VERSION "canboat-NMEA2000-curated"

NS_ :

BS_:

BU_: Vector__XXX
BO_ 2583635968 PGN_130856_simnetAlarmMessage: 229 Vector__XXX
 SG_ Manufacturer_Code : 0|11@1+ (1.0,0) [0|2047] "" Vector__XXX
 SG_ Industry_Code : 13|3@1+ (1.0,0) [0|7] "" Vector__XXX
 SG_ Alarm_ID : 16|16@1+ (1.0,0) [0|65535] "" Vector__XXX
 SG_ B : 32|8@1+ (1.0,0) [0|255] "" Vector__XXX
 SG_ C : 40|8@1+ (1.0,0) [0|255] "" Vector__XXX
 SG_ Text : 48|1784@1+ (1.0,0) [0|1090215279796298345343057319992441691038624747443985361781209060500115864369550760897269927218265076257224706224150656474098235960303036328065314058501678867531182833105052489870268422279120576700031813116210596361941430020414688522690787050244934600671795757515093047026287646566366777283893649942831776083163858446641848270013788759459916945946844663111358071639842481472666169361795887031940572252862030682746818684507336852618633070135215708762463263460541984102045620907003420426453486084172633338261276848631947315738747720031010815] "" Vector__XXX

BO_ 2650745856 PGN_130860_simnetApUnknown4: 23 Vector__XXX
 SG_ Manufacturer_Code : 0|11@1+ (1.0,0) [0|2047] "" Vector__XXX
 SG_ Industry_Code : 13|3@1+ (1.0,0) [0|7] "" Vector__XXX
 SG_ A : 16|8@1+ (1.0,0) [0|255] "" Vector__XXX
 SG_ B : 24|32@1- (1.0,0) [-2147483648|2147483647] "" Vector__XXX
 SG_ C : 56|32@1- (1.0,0) [-2147483648|2147483647] "" Vector__XXX
 SG_ D : 88|32@1+ (1.0,0) [0|4294967295] "" Vector__XXX
 SG_ E : 120|32@1- (1.0,0) [-2147483648|2147483647] "" Vector__XXX
 SG_ F : 152|32@1+ (1.0,0) [0|4294967295] "" Vector__XXX

BO_ 2583642112 PGN_130880_airmarAdditionalWeatherData: 9 Vector__XXX
 SG_ Manufacturer_Code : 0|11@1+ (1.0,0) [0|2047] "" Vector__XXX
 SG_ Industry_Code : 13|3@1+ (1.0,0) [0|7] "" Vector__XXX
 SG_ C : 16|8@1+ (1.0,0) [0|255] "" Vector__XXX
 SG_ Apparent_Windchill_Temperature : 24|16@1+ (0.01,0) [0.0|655.35] "" Vector__XXX
 SG_ True_Windchill_Temperature : 40|16@1+ (0.01,0) [0.0|655.35] "" Vector__XXX
 SG_ Dewpoint : 56|16@1+ (0.01,0) [0.0|655.35] "" Vector__XXX

BO_ 2583642368 PGN_130881_airmarHeaterControl: 9 Vector__XXX
 SG_ Manufacturer_Code : 0|11@1+ (1.0,0) [0|2047] "" Vector__XXX
 SG_ Industry_Code : 13|3@1+ (1.0,0) [0|7] "" Vector__XXX
 SG_ C : 16|8@1+ (1.0,0) [0|255] "" Vector__XXX
 SG_ Plate_Temperature : 24|16@1+ (0.01,0) [0.0|655.35] "" Vector__XXX
 SG_ Air_Temperature : 40|16@1+ (0.01,0) [0.0|655.35] "" Vector__XXX
 SG_ Dewpoint : 56|16@1+ (0.01,0) [0.0|655.35] "" Vector__XXX

BO_ 2583647232 PGN_130900_xantrexAcStatus: 20 Vector__XXX
 SG_ Manufacturer_Code : 0|11@1+ (1.0,0) [0|2047] "" Vector__XXX
 SG_ Industry_Code : 13|3@1+ (1.0,0) [0|7] "" Vector__XXX
 SG_ AC_Instance : 16|8@1+ (1.0,0) [0|255] "" Vector__XXX
 SG_ Number_of_Lines : 24|8@1+ (1.0,0) [0|255] "" Vector__XXX
 SG_ Line : 32|2@1+ (1.0,0) [0|3] "" Vector__XXX
 SG_ Acceptability : 34|2@1+ (1.0,0) [0|3] "" Vector__XXX
 SG_ Waveform : 36|3@1+ (1.0,0) [0|7] "" Vector__XXX
 SG_ Voltage : 40|16@1+ (0.01,0) [0.0|655.35] "" Vector__XXX
 SG_ Current : 56|16@1+ (0.1,0) [0.0|6553.5] "" Vector__XXX
 SG_ Frequency : 72|16@1+ (1.0,0) [0|65535] "" Vector__XXX
 SG_ Real_Power : 88|32@1- (1.0,0) [-2147483648|2147483647] "" Vector__XXX
 SG_ Reactive_Power : 120|32@1- (1.0,0) [-2147483648|2147483647] "" Vector__XXX
 SG_ Power_Factor : 152|8@1- (1.0,0) [-128|127] "%" Vector__XXX

BO_ 2583649792 PGN_130910_xantrexDcSourceConfigurationStatus: 19 Vector__XXX
 SG_ Manufacturer_Code : 0|11@1+ (1.0,0) [0|2047] "" Vector__XXX
 SG_ Industry_Code : 13|3@1+ (1.0,0) [0|7] "" Vector__XXX
 SG_ DC_Source_Instance : 16|8@1+ (1.0,0) [0|255] "" Vector__XXX
 SG_ DC_UV_Shutdown_Level : 24|16@1+ (0.01,0) [0.0|655.35] "" Vector__XXX
 SG_ DC_UV_Warning_Level : 40|16@1+ (0.01,0) [0.0|655.35] "" Vector__XXX
 SG_ DC_UV_Shutdown_Delay : 56|16@1+ (0.01,0) [0.0|655.35] "" Vector__XXX
 SG_ DC_UV_Recover_Level : 72|16@1+ (0.01,0) [0.0|655.35] "" Vector__XXX
 SG_ DC_OV_Shutdown_Level : 88|16@1+ (0.01,0) [0.0|655.35] "" Vector__XXX
 SG_ DC_OV_Warning_Level : 104|16@1+ (0.01,0) [0.0|655.35] "" Vector__XXX
 SG_ DC_OV_Shutdown_Delay : 120|16@1+ (0.01,0) [0.0|655.35] "" Vector__XXX
 SG_ DC_OV_Recover_Level : 136|16@1+ (0.01,0) [0.0|655.35] "" Vector__XXX

BO_ 2583650048 PGN_130911_xantrexAcOutputConfigurationStatus: 17 Vector__XXX
 SG_ Manufacturer_Code : 0|11@1+ (1.0,0) [0|2047] "" Vector__XXX
 SG_ Industry_Code : 13|3@1+ (1.0,0) [0|7] "" Vector__XXX
 SG_ AC_Source_Instance : 16|8@1+ (1.0,0) [0|255] "" Vector__XXX
 SG_ Number_of_Lines : 24|8@1+ (1.0,0) [0|255] "" Vector__XXX
 SG_ Line : 32|2@1+ (1.0,0) [0|3] "" Vector__XXX
 SG_ Voltage : 40|16@1+ (0.01,0) [0.0|655.35] "" Vector__XXX
 SG_ Frequency : 56|16@1+ (1.0,0) [0|65535] "" Vector__XXX
 SG_ Power_Limit : 72|32@1+ (1.0,0) [0|4294967295] "" Vector__XXX
 SG_ OV_Fault_Level : 104|16@1+ (0.01,0) [0.0|655.35] "" Vector__XXX
 SG_ UV_Fault_Level : 120|16@1+ (0.01,0) [0.0|655.35] "" Vector__XXX

BO_ 2583650304 PGN_130912_xantrexChargerConfigurationStatus: 24 Vector__XXX
 SG_ Manufacturer_Code : 0|11@1+ (1.0,0) [0|2047] "" Vector__XXX
 SG_ Industry_Code : 13|3@1+ (1.0,0) [0|7] "" Vector__XXX
 SG_ Charge_Instance : 16|8@1+ (1.0,0) [0|255] "" Vector__XXX
 SG_ Battery_Instance : 24|8@1+ (1.0,0) [0|255] "" Vector__XXX
 SG_ Bulk_Voltage : 32|16@1+ (0.01,0) [0.0|655.35] "" Vector__XXX
 SG_ Bulk_Time : 48|16@1+ (1.0,0) [0|65535] "" Vector__XXX
 SG_ Absorption_Voltage : 64|16@1+ (0.01,0) [0.0|655.35] "" Vector__XXX
 SG_ Absorption_Time : 80|16@1+ (1.0,0) [0|65535] "" Vector__XXX
 SG_ Float_Voltage : 96|16@1+ (0.01,0) [0.0|655.35] "" Vector__XXX
 SG_ Float_Time : 112|16@1+ (1.0,0) [0|65535] "" Vector__XXX
 SG_ Equalization_Voltage : 128|16@1+ (0.01,0) [0.0|655.35] "" Vector__XXX
 SG_ Generic_Charge_Voltage : 144|16@1+ (0.01,0) [0.0|655.35] "" Vector__XXX
 SG_ Generic_Charge_Current : 160|32@1+ (1.0,0) [0|4294967295] "" Vector__XXX

BO_ 2583650560 PGN_130913_xantrexAcInputConfigurationStatus: 27 Vector__XXX
 SG_ Manufacturer_Code : 0|11@1+ (1.0,0) [0|2047] "" Vector__XXX
 SG_ Industry_Code : 13|3@1+ (1.0,0) [0|7] "" Vector__XXX
 SG_ AC_Source_Instance : 16|8@1+ (1.0,0) [0|255] "" Vector__XXX
 SG_ Number_of_Lines : 24|8@1+ (1.0,0) [0|255] "" Vector__XXX
 SG_ Line : 32|2@1+ (1.0,0) [0|3] "" Vector__XXX
 SG_ Breaker_Size : 40|16@1+ (1.0,0) [0|65535] "" Vector__XXX
 SG_ AC_Lost_Level : 56|16@1+ (1.0,0) [0|65535] "" Vector__XXX
 SG_ AC_UV_Level : 72|16@1+ (0.01,0) [0.0|655.35] "" Vector__XXX
 SG_ AC_UV_Warning_Level : 88|16@1+ (1.0,0) [0|65535] "" Vector__XXX
 SG_ AC_UV_Delay : 104|16@1+ (1.0,0) [0|65535] "" Vector__XXX
 SG_ AC_OV_Level : 120|16@1+ (0.01,0) [0.0|655.35] "" Vector__XXX
 SG_ AC_OV_Warning_Level : 136|16@1+ (1.0,0) [0|65535] "" Vector__XXX
 SG_ AC_OV_Delay : 152|16@1+ (1.0,0) [0|65535] "" Vector__XXX
 SG_ AC_UF_Level : 168|16@1+ (1.0,0) [0|65535] "" Vector__XXX
 SG_ AC_OF_Level : 184|32@1+ (1.0,0) [0|4294967295] "" Vector__XXX

BO_ 2650760704 PGN_130918_seatalkRouteInformation: 47 Vector__XXX
 SG_ Manufacturer_Code : 0|11@1+ (1.0,0) [0|2047] "" Vector__XXX
 SG_ Industry_Code : 13|3@1+ (1.0,0) [0|7] "" Vector__XXX
 SG_ Current_Waypoint_Sequence : 16|16@1+ (1.0,0) [0|65535] "" Vector__XXX
 SG_ Current_Waypoint_Name : 32|128@1+ (1.0,0) [0|340282366920938463463374607431768211455] "" Vector__XXX
 SG_ Next_Waypoint_Sequence : 160|16@1+ (1.0,0) [0|65535] "" Vector__XXX
 SG_ Next_Waypoint_Name : 176|128@1+ (1.0,0) [0|340282366920938463463374607431768211455] "" Vector__XXX
 SG_ Unknown : 304|8@1+ (1.0,0) [0|255] "" Vector__XXX
 SG_ Distance__Position_to_Next_Waypoint : 312|32@1+ (1.0,0) [0|4294967295] "" Vector__XXX
 SG_ Bearing__Position_to_Next_Waypoint__True : 344|16@1+ (0.0001,0) [0.0|6.5535000000000005] "" Vector__XXX
 SG_ Bearing__Current_Waypoint_to_Next_Waypoint__True : 360|16@1+ (0.0001,0) [0.0|6.5535000000000005] "" Vector__XXX

BO_ 2583652608 PGN_130921_carlingBreakerStatusAndConfiguration: 222 Vector__XXX
 SG_ Manufacturer_Code : 0|11@1+ (1.0,0) [0|2047] "" Vector__XXX
 SG_ Industry_Code : 13|3@1+ (1.0,0) [0|7] "" Vector__XXX
 SG_ Message_Type : 16|8@1+ (1.0,0) [0|255] "" Vector__XXX
 SG_ Data : 24|1752@1+ (1.0,0) [0|253835525316255713194389203561572751737810845357362498012652867590104198169324258551297226738712069638358593504910975805040969504114016035586901488365065042751650985587633328947766782315243169828325466512751438739230257929399304213628821785153107391826760898696978820261146790945522202477765653734754718859485317591261548984333357950546759400970033524351045040329881590202605856899590205175788275025054353913931832342526721035274358715427856824538312680893703825795567971865414506855060692430514058409785217803118738186484842495] "" Vector__XXX

BO_ 2583657216 PGN_130939_lumishoreLightControl: 11 Vector__XXX
 SG_ Manufacturer_Code : 0|11@1+ (1.0,0) [0|2047] "" Vector__XXX
 SG_ Industry_Code : 13|3@1+ (1.0,0) [0|7] "" Vector__XXX
 SG_ Zone_Index : 16|8@1+ (1.0,0) [0|255] "" Vector__XXX
 SG_ Red : 24|8@1+ (1.0,0) [0|255] "" Vector__XXX
 SG_ Green : 32|8@1+ (1.0,0) [0|255] "" Vector__XXX
 SG_ Blue : 40|8@1+ (1.0,0) [0|255] "" Vector__XXX
 SG_ Cold_White : 48|8@1+ (1.0,0) [0|255] "" Vector__XXX
 SG_ Warm_White : 56|8@1+ (1.0,0) [0|255] "" Vector__XXX
 SG_ Intensity : 64|8@1+ (1.0,0) [0|255] "" Vector__XXX
 SG_ On_Off : 72|8@1+ (1.0,0) [0|255] "" Vector__XXX
 SG_ Status : 80|8@1+ (1.0,0) [0|255] "" Vector__XXX

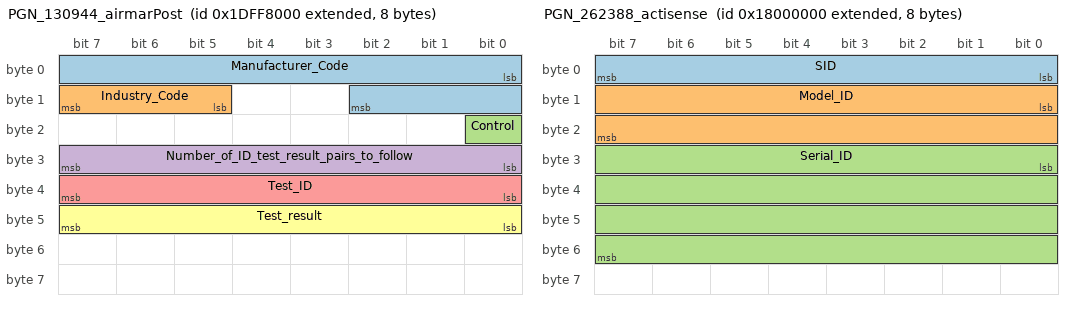
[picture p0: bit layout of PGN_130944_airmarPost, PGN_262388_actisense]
BO_ 2650767360 PGN_130944_airmarPost: 8 Vector__XXX
 SG_ Manufacturer_Code : 0|11@1+ (1.0,0) [0|2047] "" Vector__XXX
 SG_ Industry_Code : 13|3@1+ (1.0,0) [0|7] "" Vector__XXX
 SG_ Control : 16|1@1+ (1.0,0) [0|1] "" Vector__XXX
 SG_ Number_of_ID_test_result_pairs_to_follow : 24|8@1+ (1.0,0) [0|255] "" Vector__XXX
 SG_ Test_ID : 32|8@1+ (1.0,0) [0|255] "" Vector__XXX
 SG_ Test_result : 40|8@1+ (1.0,0) [0|255] "" Vector__XXX

BO_ 2583658752 PGN_130945_yamahaEngineData: 8 Vector__XXX
 SG_ Manufacturer_Code : 0|11@1+ (1.0,0) [0|2047] "" Vector__XXX
 SG_ Industry_Code : 13|3@1+ (1.0,0) [0|7] "" Vector__XXX

BO_ 2583659008 PGN_130946_yamahaEngineData2: 8 Vector__XXX
 SG_ Manufacturer_Code : 0|11@1+ (1.0,0) [0|2047] "" Vector__XXX
 SG_ Industry_Code : 13|3@1+ (1.0,0) [0|7] "" Vector__XXX

BO_ 2583659264 PGN_130947_yamahaEngineData3: 8 Vector__XXX
 SG_ Manufacturer_Code : 0|11@1+ (1.0,0) [0|2047] "" Vector__XXX
 SG_ Industry_Code : 13|3@1+ (1.0,0) [0|7] "" Vector__XXX

BO_ 2583660288 PGN_130951_yamahaEngineData4: 8 Vector__XXX
 SG_ Manufacturer_Code : 0|11@1+ (1.0,0) [0|2047] "" Vector__XXX
 SG_ Industry_Code : 13|3@1+ (1.0,0) [0|7] "" Vector__XXX

BO_ 2583674880 PGN_131008_yamahaEngineData5: 8 Vector__XXX
 SG_ Manufacturer_Code : 0|11@1+ (1.0,0) [0|2047] "" Vector__XXX
 SG_ Industry_Code : 13|3@1+ (1.0,0) [0|7] "" Vector__XXX

BO_ 2583675648 PGN_131011_yamahaEngineData6: 8 Vector__XXX
 SG_ Manufacturer_Code : 0|11@1+ (1.0,0) [0|2047] "" Vector__XXX
 SG_ Industry_Code : 13|3@1+ (1.0,0) [0|7] "" Vector__XXX

BO_ 2583675904 PGN_131012_yamahaEngineData7: 8 Vector__XXX
 SG_ Manufacturer_Code : 0|11@1+ (1.0,0) [0|2047] "" Vector__XXX
 SG_ Industry_Code : 13|3@1+ (1.0,0) [0|7] "" Vector__XXX

BO_ 2550136832 PGN_262161_actisenseOperatingMode: 13 Vector__XXX
 SG_ SID : 0|8@1+ (1.0,0) [0|255] "" Vector__XXX
 SG_ Model_ID : 8|16@1+ (1.0,0) [0|65535] "" Vector__XXX
 SG_ Serial_ID : 24|32@1+ (1.0,0) [0|4294967295] "" Vector__XXX
 SG_ Error_ID : 56|32@1+ (1.0,0) [0|4294967295] "" Vector__XXX
 SG_ Operating_Mode : 88|16@1+ (1.0,0) [0|65535] "" Vector__XXX

BO_ 2550136832 PGN_262384_actisenseStartupStatus: 15 Vector__XXX
 SG_ SID : 0|8@1+ (1.0,0) [0|255] "" Vector__XXX
 SG_ Model_ID : 8|16@1+ (1.0,0) [0|65535] "" Vector__XXX
 SG_ Serial_ID : 24|32@1+ (1.0,0) [0|4294967295] "" Vector__XXX
 SG_ Error_ID : 56|32@1+ (1.0,0) [0|4294967295] "" Vector__XXX
 SG_ Firmware_version : 88|16@1+ (0.001,0) [0.0|65.535] "" Vector__XXX
 SG_ Reset_status : 104|8@1+ (1.0,0) [0|255] "" Vector__XXX
 SG_ A : 112|8@1+ (1.0,0) [0|255] "" Vector__XXX

BO_ 2550136832 PGN_262386_actisenseSystemStatus: 33 Vector__XXX
 SG_ SID : 0|8@1+ (1.0,0) [0|255] "" Vector__XXX
 SG_ Model_ID : 8|16@1+ (1.0,0) [0|65535] "" Vector__XXX
 SG_ Serial_ID : 24|32@1+ (1.0,0) [0|4294967295] "" Vector__XXX
 SG_ Error_ID : 56|32@1+ (1.0,0) [0|4294967295] "" Vector__XXX
 SG_ Indi_channel_count : 88|8@1+ (1.0,0) [0|255] "" Vector__XXX
 SG_ Ch1_Rx_Bandwidth : 96|8@1+ (1.0,0) [0|255] "" Vector__XXX
 SG_ Ch1_Rx_Load : 104|8@1+ (1.0,0) [0|255] "" Vector__XXX
 SG_ Ch1_Rx_Filtered : 112|8@1+ (1.0,0) [0|255] "" Vector__XXX
 SG_ Ch1_Rx_Dropped : 120|8@1+ (1.0,0) [0|255] "" Vector__XXX
 SG_ Ch1_Tx_Bandwidth : 128|8@1+ (1.0,0) [0|255] "" Vector__XXX
 SG_ Ch1_Tx_Load : 136|8@1+ (1.0,0) [0|255] "" Vector__XXX
 SG_ Ch2_Rx_Bandwidth : 144|8@1+ (1.0,0) [0|255] "" Vector__XXX
 SG_ Ch2_Rx_Load : 152|8@1+ (1.0,0) [0|255] "" Vector__XXX
 SG_ Ch2_Rx_Filtered : 160|8@1+ (1.0,0) [0|255] "" Vector__XXX
 SG_ Ch2_Rx_Dropped : 168|8@1+ (1.0,0) [0|255] "" Vector__XXX
 SG_ Ch2_Tx_Bandwidth : 176|8@1+ (1.0,0) [0|255] "" Vector__XXX
 SG_ Ch2_Tx_Load : 184|8@1+ (1.0,0) [0|255] "" Vector__XXX
 SG_ Uni_channel_count : 192|8@1+ (1.0,0) [0|255] "" Vector__XXX
 SG_ Ch1_Bandwidth : 200|8@1+ (1.0,0) [0|255] "" Vector__XXX
 SG_ Ch1_Deleted : 208|8@1+ (1.0,0) [0|255] "" Vector__XXX
 SG_ Ch1_BufferLoading : 216|8@1+ (1.0,0) [0|255] "" Vector__XXX
 SG_ Ch1_PointerLoading : 224|8@1+ (1.0,0) [0|255] "" Vector__XXX
 SG_ Ch2_Bandwidth : 232|8@1+ (1.0,0) [0|255] "" Vector__XXX
 SG_ Ch2_Deleted : 240|8@1+ (1.0,0) [0|255] "" Vector__XXX
 SG_ Ch2_BufferLoading : 248|8@1+ (1.0,0) [0|255] "" Vector__XXX
 SG_ Ch2_PointerLoading : 256|8@1+ (1.0,0) [0|255] "" Vector__XXX

BO_ 2550136832 PGN_262388_actisense: 8 Vector__XXX
 SG_ SID : 0|8@1+ (1.0,0) [0|255] "" Vector__XXX
 SG_ Model_ID : 8|16@1+ (1.0,0) [0|65535] "" Vector__XXX
 SG_ Serial_ID : 24|32@1+ (1.0,0) [0|4294967295] "" Vector__XXX

BO_ 2550202368 PGN_262400_nmea2000GatewayNetworkStatus: 15 Vector__XXX
 SG_ CAN_network_load : 0|8@1+ (1.0,0) [0|255] "" Vector__XXX
 SG_ Errors : 8|32@1+ (1.0,0) [0|4294967295] "" Vector__XXX
 SG_ Device_count : 40|8@1+ (1.0,0) [0|255] "" Vector__XXX
 SG_ Uptime : 48|32@1+ (1.0,0) [0|4294967295] "" Vector__XXX
 SG_ Gateway_address : 80|8@1+ (1.0,0) [0|255] "" Vector__XXX
 SG_ Rejected_TX_requests : 88|32@1+ (1.0,0) [0|4294967295] "" Vector__XXX

BO_ 2550267904 PGN_262656_canboatStartup: 66 Vector__XXX
 SG_ Version : 0|16@1+ (0.001,0) [0.0|65.535] "" Vector__XXX
 SG_ Source : 16|256@1+ (1.0,0) [0|115792089237316195423570985008687907853269984665640564039457584007913129639935] "" Vector__XXX
 SG_ Device : 272|256@1+ (1.0,0) [0|115792089237316195423570985008687907853269984665640564039457584007913129639935] "" Vector__XXX

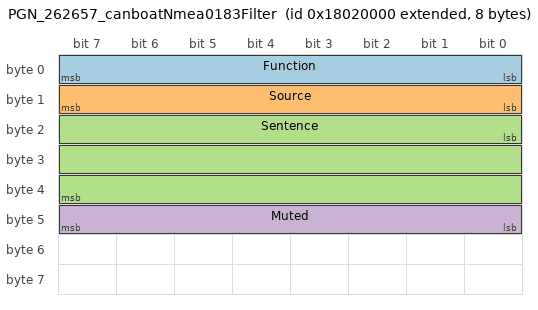
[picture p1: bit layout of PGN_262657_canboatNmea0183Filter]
BO_ 2550267904 PGN_262657_canboatNmea0183Filter: 8 Vector__XXX
 SG_ Function : 0|8@1+ (1.0,0) [0|255] "" Vector__XXX
 SG_ Source : 8|8@1+ (1.0,0) [0|255] "" Vector__XXX
 SG_ Sentence : 16|24@1+ (1.0,0) [0|16777215] "" Vector__XXX
 SG_ Muted : 40|8@1+ (1.0,0) [0|255] "" Vector__XXX

BO_ 2550267904 PGN_262658_canboatPgnOverride: 12 Vector__XXX
 SG_ Function : 0|8@1+ (1.0,0) [0|255] "" Vector__XXX
 SG_ Source : 8|8@1+ (1.0,0) [0|255] "" Vector__XXX
 SG_ PGN : 16|24@1+ (1.0,0) [0|16777215] "" Vector__XXX
 SG_ Interval : 40|32@1+ (1.0,0) [0|4294967295] "" Vector__XXX
 SG_ Manufacturer_Code : 72|16@1+ (1.0,0) [0|65535] "" Vector__XXX
 SG_ Industry_Code : 88|8@1+ (1.0,0) [0|255] "" Vector__XXX

CM_ BO_ 2583635968 "NMEA2000: PGN 130856 - Simnet: Alarm Message (type: Fast)";
CM_ BO_ 2650745856 "NMEA2000: PGN 130860 - Simnet: AP Unknown 4 (type: Fast)";
CM_ BO_ 2583642112 "NMEA2000: PGN 130880 - Airmar: Additional Weather Data (type: Fast)";
CM_ BO_ 2583642368 "NMEA2000: PGN 130881 - Airmar: Heater Control (type: Fast)";
CM_ BO_ 2583647232 "NMEA2000: PGN 130900 - Xantrex: AC Status (type: Fast)";
CM_ BO_ 2583649792 "NMEA2000: PGN 130910 - Xantrex: DC Source Configuration Status (type: Fast)";
CM_ BO_ 2583650048 "NMEA2000: PGN 130911 - Xantrex: AC Output Configuration Status (type: Fast)";
CM_ BO_ 2583650304 "NMEA2000: PGN 130912 - Xantrex: Charger Configuration Status (type: Fast)";
CM_ BO_ 2583650560 "NMEA2000: PGN 130913 - Xantrex: AC Input Configuration Status (type: Fast)";
CM_ BO_ 2650760704 "NMEA2000: PGN 130918 - SeaTalk: Route Information (type: Fast)";
CM_ BO_ 2583652608 "NMEA2000: PGN 130921 - Carling: Breaker Status and Configuration (type: Fast)";
CM_ BO_ 2583657216 "NMEA2000: PGN 130939 - Lumishore: Light Control (type: Fast)";
CM_ BO_ 2650767360 "NMEA2000: PGN 130944 - Airmar: POST (type: Fast)";
CM_ BO_ 2583658752 "NMEA2000: PGN 130945 - Yamaha: Engine Data (type: Fast)";
CM_ BO_ 2583659008 "NMEA2000: PGN 130946 - Yamaha: Engine Data 2 (type: Fast)";
CM_ BO_ 2583659264 "NMEA2000: PGN 130947 - Yamaha: Engine Data 3 (type: Fast)";
CM_ BO_ 2583660288 "NMEA2000: PGN 130951 - Yamaha: Engine Data 4 (type: Fast)";
CM_ BO_ 2583674880 "NMEA2000: PGN 131008 - Yamaha: Engine Data 5 (type: Fast)";
CM_ BO_ 2583675648 "NMEA2000: PGN 131011 - Yamaha: Engine Data 6 (type: Fast)";
CM_ BO_ 2583675904 "NMEA2000: PGN 131012 - Yamaha: Engine Data 7 (type: Fast)";
CM_ BO_ 2550136832 "NMEA2000: PGN 262161 - Actisense: Operating mode (type: Fast)";
CM_ BO_ 2550136832 "NMEA2000: PGN 262384 - Actisense: Startup status (type: Fast)";
CM_ BO_ 2550136832 "NMEA2000: PGN 262386 - Actisense: System status (type: Fast)";
CM_ BO_ 2550136832 "NMEA2000: PGN 262388 - Actisense: ? (type: Fast)";
CM_ BO_ 2550202368 "NMEA2000: PGN 262400 - NMEA 2000 gateway: network status (type: Fast)";
CM_ BO_ 2550267904 "NMEA2000: PGN 262656 - CANboat: Startup (type: Fast)";
CM_ BO_ 2550267904 "NMEA2000: PGN 262657 - CANboat: NMEA 0183 filter (type: Single)";
CM_ BO_ 2550267904 "NMEA2000: PGN 262658 - CANboat: PGN transmission-interval override (type: Fast)";
CM_ SG_ 2583635968 Manufacturer_Code "Simrad; canboat type: LOOKUP";
CM_ SG_ 2583635968 Industry_Code "Marine Industry; canboat type: LOOKUP";
CM_ SG_ 2583635968 Alarm_ID "canboat type: LOOKUP";
CM_ SG_ 2583635968 B "canboat type: UINT8";
CM_ SG_ 2583635968 C "canboat type: UINT8";
CM_ SG_ 2583635968 Text "canboat type: STRING_FIX";
CM_ SG_ 2650745856 Manufacturer_Code "Simrad; canboat type: LOOKUP";
CM_ SG_ 2650745856 Industry_Code "Marine Industry; canboat type: LOOKUP";
CM_ SG_ 2650745856 A "canboat type: UINT8";
CM_ SG_ 2650745856 B "canboat type: INT32";
CM_ SG_ 2650745856 C "canboat type: INT32";
CM_ SG_ 2650745856 D "canboat type: UINT32";
CM_ SG_ 2650745856 E "canboat type: INT32";
CM_ SG_ 2650745856 F "canboat type: UINT32";
CM_ SG_ 2583642112 Manufacturer_Code "Airmar; canboat type: LOOKUP";
CM_ SG_ 2583642112 Industry_Code "Marine Industry; canboat type: LOOKUP";
CM_ SG_ 2583642112 C "canboat type: UINT8";
CM_ SG_ 2583642112 Apparent_Windchill_Temperature "canboat type: TEMPERATURE";
CM_ SG_ 2583642112 True_Windchill_Temperature "canboat type: TEMPERATURE";
CM_ SG_ 2583642112 Dewpoint "canboat type: TEMPERATURE";
CM_ SG_ 2583642368 Manufacturer_Code "Airmar; canboat type: LOOKUP";
CM_ SG_ 2583642368 Industry_Code "Marine Industry; canboat type: LOOKUP";
CM_ SG_ 2583642368 C "canboat type: UINT8";
CM_ SG_ 2583642368 Plate_Temperature "canboat type: TEMPERATURE";
CM_ SG_ 2583642368 Air_Temperature "canboat type: TEMPERATURE";
CM_ SG_ 2583642368 Dewpoint "canboat type: TEMPERATURE";
CM_ SG_ 2583647232 Manufacturer_Code "Xantrex Technology Inc.; canboat type: LOOKUP";
CM_ SG_ 2583647232 Industry_Code "Marine Industry; canboat type: LOOKUP";
CM_ SG_ 2583647232 AC_Instance "canboat type: UINT8";
CM_ SG_ 2583647232 Number_of_Lines "canboat type: UINT8";
CM_ SG_ 2583647232 Line "canboat type: UNSIGNED_INTEGER";
CM_ SG_ 2583647232 Acceptability "canboat type: UNSIGNED_INTEGER";
CM_ SG_ 2583647232 Waveform "canboat type: UNSIGNED_INTEGER";
CM_ SG_ 2583647232 Voltage "canboat type: VOLTAGE_UFIX16_10MV";
CM_ SG_ 2583647232 Current "canboat type: CURRENT_UFIX16_DA";
CM_ SG_ 2583647232 Frequency "canboat type: UINT16";
CM_ SG_ 2583647232 Real_Power "W; canboat type: INT32";
CM_ SG_ 2583647232 Reactive_Power "VAR; canboat type: INT32";
CM_ SG_ 2583647232 Power_Factor "canboat type: PERCENTAGE_INT8";
CM_ SG_ 2583649792 Manufacturer_Code "Xantrex Technology Inc.; canboat type: LOOKUP";
CM_ SG_ 2583649792 Industry_Code "Marine Industry; canboat type: LOOKUP";
CM_ SG_ 2583649792 DC_Source_Instance "canboat type: UINT8";
CM_ SG_ 2583649792 DC_UV_Shutdown_Level "canboat type: VOLTAGE_UFIX16_10MV";
CM_ SG_ 2583649792 DC_UV_Warning_Level "canboat type: VOLTAGE_UFIX16_10MV";
CM_ SG_ 2583649792 DC_UV_Shutdown_Delay "canboat type: VOLTAGE_UFIX16_10MV";
CM_ SG_ 2583649792 DC_UV_Recover_Level "canboat type: VOLTAGE_UFIX16_10MV";
CM_ SG_ 2583649792 DC_OV_Shutdown_Level "canboat type: VOLTAGE_UFIX16_10MV";
CM_ SG_ 2583649792 DC_OV_Warning_Level "canboat type: VOLTAGE_UFIX16_10MV";
CM_ SG_ 2583649792 DC_OV_Shutdown_Delay "canboat type: VOLTAGE_UFIX16_10MV";
CM_ SG_ 2583649792 DC_OV_Recover_Level "canboat type: VOLTAGE_UFIX16_10MV";
CM_ SG_ 2583650048 Manufacturer_Code "Xantrex Technology Inc.; canboat type: LOOKUP";
CM_ SG_ 2583650048 Industry_Code "Marine Industry; canboat type: LOOKUP";
CM_ SG_ 2583650048 AC_Source_Instance "canboat type: UINT8";
CM_ SG_ 2583650048 Number_of_Lines "canboat type: UINT8";
CM_ SG_ 2583650048 Line "canboat type: UNSIGNED_INTEGER";
CM_ SG_ 2583650048 Voltage "canboat type: VOLTAGE_UFIX16_10MV";
CM_ SG_ 2583650048 Frequency "canboat type: UINT16";
CM_ SG_ 2583650048 Power_Limit "canboat type: UINT32";
CM_ SG_ 2583650048 OV_Fault_Level "canboat type: VOLTAGE_UFIX16_10MV";
CM_ SG_ 2583650048 UV_Fault_Level "canboat type: VOLTAGE_UFIX16_10MV";
CM_ SG_ 2583650304 Manufacturer_Code "Xantrex Technology Inc.; canboat type: LOOKUP";
CM_ SG_ 2583650304 Industry_Code "Marine Industry; canboat type: LOOKUP";
CM_ SG_ 2583650304 Charge_Instance "canboat type: UINT8";
CM_ SG_ 2583650304 Battery_Instance "canboat type: UINT8";
CM_ SG_ 2583650304 Bulk_Voltage "canboat type: VOLTAGE_UFIX16_10MV";
CM_ SG_ 2583650304 Bulk_Time "canboat type: UINT16";
CM_ SG_ 2583650304 Absorption_Voltage "canboat type: VOLTAGE_UFIX16_10MV";
CM_ SG_ 2583650304 Absorption_Time "canboat type: UINT16";
CM_ SG_ 2583650304 Float_Voltage "canboat type: VOLTAGE_UFIX16_10MV";
CM_ SG_ 2583650304 Float_Time "canboat type: UINT16";
CM_ SG_ 2583650304 Equalization_Voltage "canboat type: VOLTAGE_UFIX16_10MV";
CM_ SG_ 2583650304 Generic_Charge_Voltage "canboat type: VOLTAGE_UFIX16_10MV";
CM_ SG_ 2583650304 Generic_Charge_Current "canboat type: UINT32";
CM_ SG_ 2583650560 Manufacturer_Code "Xantrex Technology Inc.; canboat type: LOOKUP";
CM_ SG_ 2583650560 Industry_Code "Marine Industry; canboat type: LOOKUP";
CM_ SG_ 2583650560 AC_Source_Instance "canboat type: UINT8";
CM_ SG_ 2583650560 Number_of_Lines "canboat type: UINT8";
CM_ SG_ 2583650560 Line "canboat type: UNSIGNED_INTEGER";
CM_ SG_ 2583650560 Breaker_Size "canboat type: UINT16";
CM_ SG_ 2583650560 AC_Lost_Level "canboat type: UINT16";
CM_ SG_ 2583650560 AC_UV_Level "canboat type: VOLTAGE_UFIX16_10MV";
CM_ SG_ 2583650560 AC_UV_Warning_Level "canboat type: UINT16";
CM_ SG_ 2583650560 AC_UV_Delay "canboat type: UINT16";
CM_ SG_ 2583650560 AC_OV_Level "canboat type: VOLTAGE_UFIX16_10MV";
CM_ SG_ 2583650560 AC_OV_Warning_Level "canboat type: UINT16";
CM_ SG_ 2583650560 AC_OV_Delay "canboat type: UINT16";
CM_ SG_ 2583650560 AC_UF_Level "canboat type: UINT16";
CM_ SG_ 2583650560 AC_OF_Level "canboat type: UINT32";
CM_ SG_ 2650760704 Manufacturer_Code "Raymarine; canboat type: LOOKUP";
CM_ SG_ 2650760704 Industry_Code "Marine Industry; canboat type: LOOKUP";
CM_ SG_ 2650760704 Current_Waypoint_Sequence "canboat type: UINT16";
CM_ SG_ 2650760704 Current_Waypoint_Name "canboat type: STRING_FIX";
CM_ SG_ 2650760704 Next_Waypoint_Sequence "canboat type: UINT16";
CM_ SG_ 2650760704 Next_Waypoint_Name "canboat type: STRING_FIX";
CM_ SG_ 2650760704 Unknown "canboat type: UINT8";
CM_ SG_ 2650760704 Distance__Position_to_Next_Waypoint "canboat type: LENGTH_UFIX32_M";
CM_ SG_ 2650760704 Bearing__Position_to_Next_Waypoint__True "canboat type: ANGLE_UFIX16";
CM_ SG_ 2650760704 Bearing__Current_Waypoint_to_Next_Waypoint__True "canboat type: ANGLE_UFIX16";
CM_ SG_ 2583652608 Manufacturer_Code "Carling Technologies Inc. (Moritz Aerospace); canboat type: LOOKUP";
CM_ SG_ 2583652608 Industry_Code "Marine Industry; canboat type: LOOKUP";
CM_ SG_ 2583652608 Message_Type "canboat type: UINT8";
CM_ SG_ 2583652608 Data "Payload varies by Message Type.; canboat type: BINARY";
CM_ SG_ 2583657216 Manufacturer_Code "Lumishore; canboat type: LOOKUP";
CM_ SG_ 2583657216 Industry_Code "Marine Industry; canboat type: LOOKUP";
CM_ SG_ 2583657216 Zone_Index "canboat type: UINT8";
CM_ SG_ 2583657216 Red "canboat type: UINT8";
CM_ SG_ 2583657216 Green "canboat type: UINT8";
CM_ SG_ 2583657216 Blue "canboat type: UINT8";
CM_ SG_ 2583657216 Cold_White "canboat type: UINT8";
CM_ SG_ 2583657216 Warm_White "canboat type: UINT8";
CM_ SG_ 2583657216 Intensity "canboat type: UINT8";
CM_ SG_ 2583657216 On_Off "canboat type: UINT8";
CM_ SG_ 2583657216 Status "canboat type: UINT8";
CM_ SG_ 2650767360 Manufacturer_Code "Airmar; canboat type: LOOKUP";
CM_ SG_ 2650767360 Industry_Code "Marine Industry; canboat type: LOOKUP";
CM_ SG_ 2650767360 Control "canboat type: LOOKUP";
CM_ SG_ 2650767360 Number_of_ID_test_result_pairs_to_follow "canboat type: UINT8";
CM_ SG_ 2650767360 Test_ID "See Airmar docs for table of IDs and failure codes; these lookup values are for DST200; canboat type: LOOKUP";
CM_ SG_ 2650767360 Test_result "Values other than 0 are failure codes; canboat type: UINT8";
CM_ SG_ 2583658752 Manufacturer_Code "Mystic Valley Communications; canboat type: LOOKUP";
CM_ SG_ 2583658752 Industry_Code "Marine Industry; canboat type: LOOKUP";
CM_ SG_ 2583659008 Manufacturer_Code "Mystic Valley Communications; canboat type: LOOKUP";
CM_ SG_ 2583659008 Industry_Code "Marine Industry; canboat type: LOOKUP";
CM_ SG_ 2583659264 Manufacturer_Code "Mystic Valley Communications; canboat type: LOOKUP";
CM_ SG_ 2583659264 Industry_Code "Marine Industry; canboat type: LOOKUP";
CM_ SG_ 2583660288 Manufacturer_Code "Mystic Valley Communications; canboat type: LOOKUP";
CM_ SG_ 2583660288 Industry_Code "Marine Industry; canboat type: LOOKUP";
CM_ SG_ 2583674880 Manufacturer_Code "Mystic Valley Communications; canboat type: LOOKUP";
CM_ SG_ 2583674880 Industry_Code "Marine Industry; canboat type: LOOKUP";
CM_ SG_ 2583675648 Manufacturer_Code "Mystic Valley Communications; canboat type: LOOKUP";
CM_ SG_ 2583675648 Industry_Code "Marine Industry; canboat type: LOOKUP";
CM_ SG_ 2583675904 Manufacturer_Code "Mystic Valley Communications; canboat type: LOOKUP";
CM_ SG_ 2583675904 Industry_Code "Marine Industry; canboat type: LOOKUP";
CM_ SG_ 2550136832 SID "canboat type: UINT8";
CM_ SG_ 2550136832 Model_ID "canboat type: UINT16";
CM_ SG_ 2550136832 Serial_ID "canboat type: UINT32";
CM_ SG_ 2550136832 Error_ID "canboat type: UINT32";
CM_ SG_ 2550136832 Operating_Mode "canboat type: UINT16";
CM_ SG_ 2550136832 SID "canboat type: UINT8";
CM_ SG_ 2550136832 Model_ID "canboat type: UINT16";
CM_ SG_ 2550136832 Serial_ID "canboat type: UINT32";
CM_ SG_ 2550136832 Error_ID "canboat type: UINT32";
CM_ SG_ 2550136832 Firmware_version "canboat type: VERSION";
CM_ SG_ 2550136832 Reset_status "canboat type: UINT8";
CM_ SG_ 2550136832 A "canboat type: UINT8";
CM_ SG_ 2550136832 SID "canboat type: UINT8";
CM_ SG_ 2550136832 Model_ID "canboat type: UINT16";
CM_ SG_ 2550136832 Serial_ID "canboat type: UINT32";
CM_ SG_ 2550136832 Error_ID "canboat type: UINT32";
CM_ SG_ 2550136832 Indi_channel_count "canboat type: UINT8";
CM_ SG_ 2550136832 Ch1_Rx_Bandwidth "canboat type: UINT8";
CM_ SG_ 2550136832 Ch1_Rx_Load "canboat type: UINT8";
CM_ SG_ 2550136832 Ch1_Rx_Filtered "canboat type: UINT8";
CM_ SG_ 2550136832 Ch1_Rx_Dropped "canboat type: UINT8";
CM_ SG_ 2550136832 Ch1_Tx_Bandwidth "canboat type: UINT8";
CM_ SG_ 2550136832 Ch1_Tx_Load "canboat type: UINT8";
CM_ SG_ 2550136832 Ch2_Rx_Bandwidth "canboat type: UINT8";
CM_ SG_ 2550136832 Ch2_Rx_Load "canboat type: UINT8";
CM_ SG_ 2550136832 Ch2_Rx_Filtered "canboat type: UINT8";
CM_ SG_ 2550136832 Ch2_Rx_Dropped "canboat type: UINT8";
CM_ SG_ 2550136832 Ch2_Tx_Bandwidth "canboat type: UINT8";
CM_ SG_ 2550136832 Ch2_Tx_Load "canboat type: UINT8";
CM_ SG_ 2550136832 Uni_channel_count "canboat type: UINT8";
CM_ SG_ 2550136832 Ch1_Bandwidth "canboat type: UINT8";
CM_ SG_ 2550136832 Ch1_Deleted "canboat type: UINT8";
CM_ SG_ 2550136832 Ch1_BufferLoading "canboat type: UINT8";
CM_ SG_ 2550136832 Ch1_PointerLoading "canboat type: UINT8";
CM_ SG_ 2550136832 Ch2_Bandwidth "canboat type: UINT8";
CM_ SG_ 2550136832 Ch2_Deleted "canboat type: UINT8";
CM_ SG_ 2550136832 Ch2_BufferLoading "canboat type: UINT8";
CM_ SG_ 2550136832 Ch2_PointerLoading "canboat type: UINT8";
CM_ SG_ 2550136832 SID "canboat type: UINT8";
CM_ SG_ 2550136832 Model_ID "canboat type: UINT16";
CM_ SG_ 2550136832 Serial_ID "canboat type: UINT32";
CM_ SG_ 2550202368 CAN_network_load "canboat type: UINT8";
CM_ SG_ 2550202368 Errors "canboat type: UINT32";
CM_ SG_ 2550202368 Device_count "canboat type: UINT8";
CM_ SG_ 2550202368 Uptime "canboat type: DURATION_UFIX32_S";
CM_ SG_ 2550202368 Gateway_address "canboat type: UINT8";
CM_ SG_ 2550202368 Rejected_TX_requests "canboat type: UINT32";
CM_ SG_ 2550267904 Version "canboat type: VERSION";
CM_ SG_ 2550267904 Source "canboat type: STRING_FIX";
CM_ SG_ 2550267904 Device "canboat type: STRING_FIX";
CM_ SG_ 2550267904 Function "0=Report (pipeline->tui), 1=Set (tui->pipeline); canboat type: NUMBER";
CM_ SG_ 2550267904 Source "N2K source address this record refers to; canboat type: NUMBER";
CM_ SG_ 2550267904 Sentence "3-letter NMEA 0183 formatter, or 'ALL' for the whole source; canboat type: STRING_FIX";
CM_ SG_ 2550267904 Muted "0=active (emitting), 1=muted; canboat type: NUMBER";
CM_ SG_ 2550267904 Function "0=Report (server->tui), 1=Set, 2=Request, 3=Delete (tui->server); canboat type: NUMBER";
CM_ SG_ 2550267904 Source "N2K source address of the device the override targets; canboat type: NUMBER";
CM_ SG_ 2550267904 PGN "Commanded PGN whose transmission interval is overridden; canboat type: NUMBER";
CM_ SG_ 2550267904 Interval "Requested transmission interval in ms; 0 = stop transmitting; canboat type: NUMBER";
CM_ SG_ 2550267904 Manufacturer_Code "For proprietary PGNs; 0xffff = not applicable; canboat type: NUMBER";
CM_ SG_ 2550267904 Industry_Code "For proprietary PGNs; 0xff = not applicable; canboat type: NUMBER";
VAL_ 2583635968 Manufacturer_Code 69 "ARKS Enterprises" 78 "FW Murphy/Enovation Controls" 80 "Twin Disc" 85 "Kohler Power Systems" 88 "Hemisphere GPS" 135 "Airmar" 137 "Maretron" 140 "Lowrance" 144 "Mercury Marine" 147 "Nautibus Electronic" 148 "Blue Water Data" 154 "Westerbeke" 157 "ISSPRO" 161 "Offshore Systems (UK)" 163 "Evinrude/BRP" 165 "CPAC Systems" 168 "Xantrex Technology" 169 "Marlin Technologies" 172 "Yanmar Marine" 174 "Volvo Penta" 176 "Carling Technologies Inc. (Moritz Aerospace)" 185 "Beede Instruments" 192 "Floscan Instrument" 193 "Nobeltec" 198 "Mystic Valley Communications" 199 "Actia" 201 "Disenos Y Technologia" 211 "Digital Switching Systems" 215 "Xintex/Atena" 224 "EMMI NETWORK" 228 "ZF" 229 "Garmin" 233 "Yacht Monitoring Solutions" 235 "Sailormade Marine Telemetry/Tetra Technology" 243 "Eride" 257 "Honda Motor" 272 "Groco" 273 "Actisense" 274 "Amphenol LTW Technology" 275 "Navico" 283 "Hamilton Jet" 285 "Sea Recovery" 286 "Coelmo SRL Italy" 295 "BEP Marine" 304 "Empir Bus" 305 "NovAtel" 306 "Sleipner Motor" 307 "MBW Technologies" 315 "ICOM" 328 "Qwerty" 329 "Dief" 341 "Boening Automationstechnologie" 345 "Korean Maritime University" 351 "Thrane and Thrane" 355 "Mastervolt" 356 "Fischer Panda Generators" 358 "Victron Energy" 370 "Rolls Royce Marine" 373 "Electronic Design" 374 "Northern Lights" 378 "Glendinning" 381 "B & G" 384 "Rose Point Navigation Systems" 385 "Johnson Outdoors Marine Electronics Inc Geonav" 394 "Capi 2" 396 "Beyond Measure" 400 "Livorsi Marine" 404 "ComNav" 409 "Chetco" 419 "Fusion Electronics" 421 "Standard Horizon" 422 "True Heading" 426 "Egersund Marine Electronics" 427 "em-trak Marine Electronics" 431 "Tohatsu Co, JP" 437 "Digital Yacht" 438 "Comar Systems Limited" 440 "Cummins" 443 "VDO (aka Continental-Corporation)" 451 "Parker Hannifin aka Village Marine Tech" 459 "Alltek Marine Electronics" 460 "SAN GIORGIO S.E.I.N" 466 "Veethree Electronics & Marine" 470 "SI-TEX Marine Electronics" 471 "Sea Cross Marine" 475 "GME aka Standard Communications" 476 "Humminbird Marine Electronics" 478 "Ocean Sat" 481 "Chetco Digital Instruments" 493 "Watcheye" 499 "Lcj Capteurs" 502 "Attwood Marine" 503 "Naviop S.R.L." 504 "Vesper Marine" 510 "Marinesoft" 513 "Simarine" 517 "NoLand Engineering" 518 "Transas USA" 529 "National Instruments Korea" 530 "National Marine Electronics Association" 532 "Onwa Marine" 540 "Webasto" 571 "Marinecraft (South Korea)" 573 "McMurdo Group aka Orolia" 578 "Advansea" 579 "KVH" 580 "San Jose Technology" 583 "Yacht Control" 586 "Suzuki Motor" 591 "US Coast Guard" 595 "Ship Module aka Customware" 600 "Aquatic AV" 605 "Aventics" 606 "Intellian" 612 "SamwonIT" 614 "Arlt Tecnologies" 637 "Bavaria Yachts" 641 "Diverse Yacht Services" 644 "Wema U.S.A dba KUS" 658 "Shenzhen Jiuzhou Himunication" 688 "Rockford" 699 "Harman International" 704 "JL Audio" 708 "Lars Thrane" 715 "Autonnic" 717 "Yacht Devices" 734 "REAP Systems" 735 "AEM Performance Electronics" 739 "LxNav" 741 "Littelfuse, Inc (formerly Carling Technologies)" 743 "DaeMyung" 744 "Woosung" 748 "ISOTTA IFRA srl" 773 "Clarion US" 776 "HMI Systems" 777 "Ocean Signal" 778 "Seakeeper" 781 "Poly Planar" 785 "Fischer Panda DE" 795 "Broyda Industries" 796 "Canadian Automotive" 797 "Tides Marine" 798 "Lumishore" 799 "Still Water Designs and Audio" 802 "BJ Technologies (Beneteau)" 803 "Gill Sensors" 811 "Blue Water Desalination" 815 "FLIR" 824 "Undheim Systems" 826 "Lewmar" 838 "TeamSurv" 844 "Fell Marine" 847 "Oceanvolt" 862 "Prospec" 868 "Data Panel" 890 "L3 Technologies" 894 "Rhodan Marine Systems" 896 "Nexfour Solutions" 905 "ASA Electronics" 909 "Marines Co (South Korea)" 911 "Nautic-on" 917 "Sentinel" 929 "JL Marine Systems" 930 "Ecotronix" 944 "Zontisa Marine" 951 "EXOR International" 962 "Timbolier Industries" 963 "TJC Micro" 968 "Cox Powertrain" 969 "Blue Seas" 981 "Kobelt Manufacturing" 992 "Blue Ocean IOT" 997 "Xenta Systems" 999 "Signal K" 1004 "Ultraflex" 1008 "Lintest SmartBoat" 1011 "Soundmax" 1020 "Team Italia Marine (Onyx Marine Automation s.r.l)" 1021 "Entratech" 1022 "ITC" 1029 "The Marine Guardian" 1047 "Sonic" 1051 "ProNav" 1053 "Vetus Maxwell INC." 1056 "Lithium Pros" 1059 "Boatrax" 1062 "Marol Co ltd" 1065 "CALYPSO Instruments" 1066 "Spot Zero Water" 1069 "Lithionics Battery" 1070 "Quick-teck Electronics" 1075 "Uniden America" 1083 "Nauticoncept" 1084 "Shadow-Caster LED lighting" 1085 "Wet Sounds" 1088 "E-T-A Circuit Breakers" 1092 "Scheiber" 1100 "Smart Yachts International Limited" 1109 "Dockmate" 1114 "Bobs Machine" 1118 "L3Harris ASV" 1119 "Balmar" 1120 "Elettromedia" 1127 "Electromaax" 1140 "Across Oceans Systems" 1145 "Kiwi Yachting" 1150 "BSB Artificial Intelligence" 1151 "Orca Technologies" 1154 "TBS Electronics" 1158 "Technoton Electroics" 1160 "MG Energy Systems" 1169 "Sea Machine Robotics" 1171 "Vista Manufacturing" 1183 "Zipwake" 1186 "Sailmon" 1192 "Airmoniq Pro Kft" 1194 "Sierra Marine" 1200 "Xinuo Information Technology (Xiamen)" 1218 "Septentrio" 1233 "NKE Marine Electronics" 1238 "SuperTrack Aps" 1239 "Honda Electronics" 1245 "Raritan Engineering" 1249 "Integrated Power Solutions AG" 1260 "Interactive Technologies" 1283 "LTG-Tech" 1299 "Energy Solutions (UK)" 1300 "WATT Fuel Cell" 1302 "Pro Mainer" 1305 "Dragonfly Energy" 1306 "Koden Electronics" 1311 "Humphree" 1316 "Hinkley Yachts" 1317 "Global Marine Management GmbH (GMM)" 1320 "Triskel Marine" 1330 "Warwick Control Technologies" 1331 "Dolphin Charger" 1337 "Barnacle Systems" 1348 "Radian IoT" 1353 "Ocean LED Marine" 1359 "BluNav" 1361 "OVA (Nantong Saiyang Electronics Co., Ltd)" 1368 "RAD Propulsion" 1369 "Electric Yacht" 1372 "Elco Motor Yachts" 1384 "Tecnoseal Foundry S.r.l" 1385 "Pro Charging Systems" 1389 "EVEX" 1398 "Gobius Sensor Technology" 1403 "Arco Marine" 1408 "Lenco Marine" 1413 "Naocontrol" 1417 "Revatek" 1438 "Aeolionics" 1439 "PredictWind" 1440 "Egis Mobile Electric" 1445 "Starboard Yacht Group" 1446 "Roswell Marine" 1451 "ePropulsion (Guangdong ePropulsion Technology Ltd.)" 1452 "Micro-Air" 1453 "Vital Battery" 1458 "Ride Controller" 1460 "Tocaro Blue" 1461 "Vanquish Yachts" 1471 "FT Technologies" 1478 "Alps Alpine" 1481 "E-Force Marine" 1482 "CMC Marine" 1483 "Nanjing Sandemarine Information Technology" 1850 "Teleflex Marine (SeaStar Solutions)" 1851 "Raymarine" 1852 "Navionics" 1853 "Japan Radio" 1854 "Northstar Technologies" 1855 "Furuno" 1856 "Trimble" 1857 "Simrad" 1858 "Litton" 1859 "Kvasar" 1860 "MMP" 1861 "Vector Cantech" 1862 "Yamaha Marine" 1863 "Faria Instruments" ;
VAL_ 2583635968 Industry_Code 0 "Global" 1 "Highway" 2 "Agriculture" 3 "Construction" 4 "Marine Industry" 5 "Industrial" ;
VAL_ 2583635968 Alarm_ID 10 "Shallow water" 11 "Deep water" 12 "Anchor depth" 13 "True wind shift" 14 "True wind high" 15 "True wind low" 16 "Low boat speed" 17 "High voltage" 18 "Low voltage" 19 "Depth data missing" 20 "Wind data missing" 21 "Nav data missing" 22 "Heading missing" 23 "XTE" 24 "Rudder data missing" 25 "Rudder controller fault" 26 "No rudder response" 27 "Rudder drive overload" 28 "High internal temperature" 29 "AP clutch overload" 30 "AP clutch disengaged" 31 "High drive supply" 32 "Low drive supply" 33 "No active autopilot control unit" 34 "No autopilot computer" 35 "Memory fail" 36 "Water temp missing" 37 "Low water temp" 38 "High water temp" 39 "Water temp rate" 40 "Fish" 41 "No GPS fix" 42 "WAAS/DGPS" 45 "Arrival" 46 "Anchor" 47 "Fuel low" 48 "Fuel high" 49 "Tank low" 50 "Tank high" 51 "BEP" 52 "Waypoint radius" 53 "CPA" 54 "AIS range to vessel" 55 "AIS vessel lost" 56 "Vessel message" 57 "Lightning" 58 "Severe weather" 59 "Storm" 61 "Engine Check" 62 "Engine over temperature" 63 "Engine low oil pressure" 64 "Engine low oil level" 65 "Engine low fuel pressure" 66 "Engine low voltage" 67 "Engine low coolant level" 68 "Engine water flow" 69 "Engine water in fuel" 70 "Engine charge" 71 "Engine preheat" 72 "Engine high boost pressure" 73 "Engine rev limit" 74 "Engine EGR system" 75 "Engine throttle position" 76 "Engine emergency stop" 77 "Engine warning level 1" 78 "Engine warning level 2" 79 "Engine power reduction" 80 "Engine maintenance" 81 "Engine comm error" 82 "Engine throttle" 83 "Engine start protect" 84 "Engine shutting down" 85 "Transmission Check" 86 "Transmission over temperature" 87 "Transmission low oil pressure" 88 "Transmission low oil level" 89 "Sail drive" 96 "Fresh water low" 97 "Fresh water high" 98 "Gray water low" 99 "Gray water high" 100 "Live well low" 101 "Live well high" 102 "Oil low" 103 "Oil high" 104 "Black water low" 105 "Black water high" 106 "Weather data missing" 107 "AP Position data missing" 108 "AP Speed data missing" 109 "AP Depth data missing" 110 "AP Heading data missing" 111 "AP Nav data missing" 112 "AP Off course" 113 "AP Rudder data missing" 114 "AP Wind data missing" 115 "Radar guard zone" 116 "MARPA target lost" 117 "MARPA unavailable" 118 "Dangerous vessel" 119 "Radar error" 120 "CZone critical" 121 "CZone important" 122 "CZone standard" 123 "CZone warning" 124 "True wind shift" 125 "EVC Com Error" 126 "EVC override" 127 "High drive temperature" 128 "Drive inhibit" 129 "CAN bus supply overload" 130 "Drive ref voltage missing" 131 "Rudder limit" 132 "Compass difference" 133 "AP Low boat speed" 134 "Monitor compass missing" 135 "Cross track distance limit" 137 "End of route" 138 "Compass alignment" 139 "R.A.I.M" 141 "Off heading" 142 "Supply voltage" 143 "Low CAN bus voltage" 144 "CAN bus failure" 145 "Drive ready missing" 146 "Drive computer missing" 147 "External mode illegal" 148 "Rudder too slow" 149 "Wheel over" 150 "Thruster inhibited" 151 "Check heading" 152 "True wind speed high" 153 "Override" 154 "Speed through water rationality fault" 155 "No drives available" 156 "Fuel remaining low" 157 "Fuel remaining high" 158 "Generator Check" 159 "Generator over temperature" 160 "Generator low oil pressure" 161 "Generator low oil level" 162 "Generator low fuel pressure" 163 "Generator low voltage" 164 "Generator low coolant level" 165 "Generator water flow" 166 "Generator water in fuel" 167 "Generator charge" 168 "Generator preheat" 169 "Generator high boost pressure" 170 "Generator rev limit" 171 "Generator EGR system" 172 "Generator throttle position" 173 "Generator emergency stop" 174 "Generator warning level 1" 175 "Generator warning level 2" 176 "Generator power reduction" 177 "Generator maintenance" 178 "Generator comm error" 179 "Generator throttle" 180 "Generator start protect" 181 "Generator shutting down" 182 "Shallow aft depth" 183 "Forward range" 245 "Alarm source missing" 246 "External" 247 "EVC Com Error" 248 "Wind sensor battery low" 266 "Gasoline low" 267 "Gasoline high" 268 "Charging System" 269 "Seawater Flow" 270 "Water in Drive Seal" 272 "Turnover" 273 "Helm ECU Detect Failure" 274 "Joystick ECU Detect Failure" 275 "Drive ECU Detect Failure" 276 "Hot Transmission" 277 "Low Gear Oil Pressure" 278 "Low Drive Lub Oil Level" 285 "Check Thermostat" 287 "Track offset active" 385 "Navigation Not Supported" ;
VAL_ 2650745856 Manufacturer_Code 69 "ARKS Enterprises" 78 "FW Murphy/Enovation Controls" 80 "Twin Disc" 85 "Kohler Power Systems" 88 "Hemisphere GPS" 135 "Airmar" 137 "Maretron" 140 "Lowrance" 144 "Mercury Marine" 147 "Nautibus Electronic" 148 "Blue Water Data" 154 "Westerbeke" 157 "ISSPRO" 161 "Offshore Systems (UK)" 163 "Evinrude/BRP" 165 "CPAC Systems" 168 "Xantrex Technology" 169 "Marlin Technologies" 172 "Yanmar Marine" 174 "Volvo Penta" 176 "Carling Technologies Inc. (Moritz Aerospace)" 185 "Beede Instruments" 192 "Floscan Instrument" 193 "Nobeltec" 198 "Mystic Valley Communications" 199 "Actia" 201 "Disenos Y Technologia" 211 "Digital Switching Systems" 215 "Xintex/Atena" 224 "EMMI NETWORK" 228 "ZF" 229 "Garmin" 233 "Yacht Monitoring Solutions" 235 "Sailormade Marine Telemetry/Tetra Technology" 243 "Eride" 257 "Honda Motor" 272 "Groco" 273 "Actisense" 274 "Amphenol LTW Technology" 275 "Navico" 283 "Hamilton Jet" 285 "Sea Recovery" 286 "Coelmo SRL Italy" 295 "BEP Marine" 304 "Empir Bus" 305 "NovAtel" 306 "Sleipner Motor" 307 "MBW Technologies" 315 "ICOM" 328 "Qwerty" 329 "Dief" 341 "Boening Automationstechnologie" 345 "Korean Maritime University" 351 "Thrane and Thrane" 355 "Mastervolt" 356 "Fischer Panda Generators" 358 "Victron Energy" 370 "Rolls Royce Marine" 373 "Electronic Design" 374 "Northern Lights" 378 "Glendinning" 381 "B & G" 384 "Rose Point Navigation Systems" 385 "Johnson Outdoors Marine Electronics Inc Geonav" 394 "Capi 2" 396 "Beyond Measure" 400 "Livorsi Marine" 404 "ComNav" 409 "Chetco" 419 "Fusion Electronics" 421 "Standard Horizon" 422 "True Heading" 426 "Egersund Marine Electronics" 427 "em-trak Marine Electronics" 431 "Tohatsu Co, JP" 437 "Digital Yacht" 438 "Comar Systems Limited" 440 "Cummins" 443 "VDO (aka Continental-Corporation)" 451 "Parker Hannifin aka Village Marine Tech" 459 "Alltek Marine Electronics" 460 "SAN GIORGIO S.E.I.N" 466 "Veethree Electronics & Marine" 470 "SI-TEX Marine Electronics" 471 "Sea Cross Marine" 475 "GME aka Standard Communications" 476 "Humminbird Marine Electronics" 478 "Ocean Sat" 481 "Chetco Digital Instruments" 493 "Watcheye" 499 "Lcj Capteurs" 502 "Attwood Marine" 503 "Naviop S.R.L." 504 "Vesper Marine" 510 "Marinesoft" 513 "Simarine" 517 "NoLand Engineering" 518 "Transas USA" 529 "National Instruments Korea" 530 "National Marine Electronics Association" 532 "Onwa Marine" 540 "Webasto" 571 "Marinecraft (South Korea)" 573 "McMurdo Group aka Orolia" 578 "Advansea" 579 "KVH" 580 "San Jose Technology" 583 "Yacht Control" 586 "Suzuki Motor" 591 "US Coast Guard" 595 "Ship Module aka Customware" 600 "Aquatic AV" 605 "Aventics" 606 "Intellian" 612 "SamwonIT" 614 "Arlt Tecnologies" 637 "Bavaria Yachts" 641 "Diverse Yacht Services" 644 "Wema U.S.A dba KUS" 658 "Shenzhen Jiuzhou Himunication" 688 "Rockford" 699 "Harman International" 704 "JL Audio" 708 "Lars Thrane" 715 "Autonnic" 717 "Yacht Devices" 734 "REAP Systems" 735 "AEM Performance Electronics" 739 "LxNav" 741 "Littelfuse, Inc (formerly Carling Technologies)" 743 "DaeMyung" 744 "Woosung" 748 "ISOTTA IFRA srl" 773 "Clarion US" 776 "HMI Systems" 777 "Ocean Signal" 778 "Seakeeper" 781 "Poly Planar" 785 "Fischer Panda DE" 795 "Broyda Industries" 796 "Canadian Automotive" 797 "Tides Marine" 798 "Lumishore" 799 "Still Water Designs and Audio" 802 "BJ Technologies (Beneteau)" 803 "Gill Sensors" 811 "Blue Water Desalination" 815 "FLIR" 824 "Undheim Systems" 826 "Lewmar" 838 "TeamSurv" 844 "Fell Marine" 847 "Oceanvolt" 862 "Prospec" 868 "Data Panel" 890 "L3 Technologies" 894 "Rhodan Marine Systems" 896 "Nexfour Solutions" 905 "ASA Electronics" 909 "Marines Co (South Korea)" 911 "Nautic-on" 917 "Sentinel" 929 "JL Marine Systems" 930 "Ecotronix" 944 "Zontisa Marine" 951 "EXOR International" 962 "Timbolier Industries" 963 "TJC Micro" 968 "Cox Powertrain" 969 "Blue Seas" 981 "Kobelt Manufacturing" 992 "Blue Ocean IOT" 997 "Xenta Systems" 999 "Signal K" 1004 "Ultraflex" 1008 "Lintest SmartBoat" 1011 "Soundmax" 1020 "Team Italia Marine (Onyx Marine Automation s.r.l)" 1021 "Entratech" 1022 "ITC" 1029 "The Marine Guardian" 1047 "Sonic" 1051 "ProNav" 1053 "Vetus Maxwell INC." 1056 "Lithium Pros" 1059 "Boatrax" 1062 "Marol Co ltd" 1065 "CALYPSO Instruments" 1066 "Spot Zero Water" 1069 "Lithionics Battery" 1070 "Quick-teck Electronics" 1075 "Uniden America" 1083 "Nauticoncept" 1084 "Shadow-Caster LED lighting" 1085 "Wet Sounds" 1088 "E-T-A Circuit Breakers" 1092 "Scheiber" 1100 "Smart Yachts International Limited" 1109 "Dockmate" 1114 "Bobs Machine" 1118 "L3Harris ASV" 1119 "Balmar" 1120 "Elettromedia" 1127 "Electromaax" 1140 "Across Oceans Systems" 1145 "Kiwi Yachting" 1150 "BSB Artificial Intelligence" 1151 "Orca Technologies" 1154 "TBS Electronics" 1158 "Technoton Electroics" 1160 "MG Energy Systems" 1169 "Sea Machine Robotics" 1171 "Vista Manufacturing" 1183 "Zipwake" 1186 "Sailmon" 1192 "Airmoniq Pro Kft" 1194 "Sierra Marine" 1200 "Xinuo Information Technology (Xiamen)" 1218 "Septentrio" 1233 "NKE Marine Electronics" 1238 "SuperTrack Aps" 1239 "Honda Electronics" 1245 "Raritan Engineering" 1249 "Integrated Power Solutions AG" 1260 "Interactive Technologies" 1283 "LTG-Tech" 1299 "Energy Solutions (UK)" 1300 "WATT Fuel Cell" 1302 "Pro Mainer" 1305 "Dragonfly Energy" 1306 "Koden Electronics" 1311 "Humphree" 1316 "Hinkley Yachts" 1317 "Global Marine Management GmbH (GMM)" 1320 "Triskel Marine" 1330 "Warwick Control Technologies" 1331 "Dolphin Charger" 1337 "Barnacle Systems" 1348 "Radian IoT" 1353 "Ocean LED Marine" 1359 "BluNav" 1361 "OVA (Nantong Saiyang Electronics Co., Ltd)" 1368 "RAD Propulsion" 1369 "Electric Yacht" 1372 "Elco Motor Yachts" 1384 "Tecnoseal Foundry S.r.l" 1385 "Pro Charging Systems" 1389 "EVEX" 1398 "Gobius Sensor Technology" 1403 "Arco Marine" 1408 "Lenco Marine" 1413 "Naocontrol" 1417 "Revatek" 1438 "Aeolionics" 1439 "PredictWind" 1440 "Egis Mobile Electric" 1445 "Starboard Yacht Group" 1446 "Roswell Marine" 1451 "ePropulsion (Guangdong ePropulsion Technology Ltd.)" 1452 "Micro-Air" 1453 "Vital Battery" 1458 "Ride Controller" 1460 "Tocaro Blue" 1461 "Vanquish Yachts" 1471 "FT Technologies" 1478 "Alps Alpine" 1481 "E-Force Marine" 1482 "CMC Marine" 1483 "Nanjing Sandemarine Information Technology" 1850 "Teleflex Marine (SeaStar Solutions)" 1851 "Raymarine" 1852 "Navionics" 1853 "Japan Radio" 1854 "Northstar Technologies" 1855 "Furuno" 1856 "Trimble" 1857 "Simrad" 1858 "Litton" 1859 "Kvasar" 1860 "MMP" 1861 "Vector Cantech" 1862 "Yamaha Marine" 1863 "Faria Instruments" ;
VAL_ 2650745856 Industry_Code 0 "Global" 1 "Highway" 2 "Agriculture" 3 "Construction" 4 "Marine Industry" 5 "Industrial" ;
VAL_ 2583642112 Manufacturer_Code 69 "ARKS Enterprises" 78 "FW Murphy/Enovation Controls" 80 "Twin Disc" 85 "Kohler Power Systems" 88 "Hemisphere GPS" 135 "Airmar" 137 "Maretron" 140 "Lowrance" 144 "Mercury Marine" 147 "Nautibus Electronic" 148 "Blue Water Data" 154 "Westerbeke" 157 "ISSPRO" 161 "Offshore Systems (UK)" 163 "Evinrude/BRP" 165 "CPAC Systems" 168 "Xantrex Technology" 169 "Marlin Technologies" 172 "Yanmar Marine" 174 "Volvo Penta" 176 "Carling Technologies Inc. (Moritz Aerospace)" 185 "Beede Instruments" 192 "Floscan Instrument" 193 "Nobeltec" 198 "Mystic Valley Communications" 199 "Actia" 201 "Disenos Y Technologia" 211 "Digital Switching Systems" 215 "Xintex/Atena" 224 "EMMI NETWORK" 228 "ZF" 229 "Garmin" 233 "Yacht Monitoring Solutions" 235 "Sailormade Marine Telemetry/Tetra Technology" 243 "Eride" 257 "Honda Motor" 272 "Groco" 273 "Actisense" 274 "Amphenol LTW Technology" 275 "Navico" 283 "Hamilton Jet" 285 "Sea Recovery" 286 "Coelmo SRL Italy" 295 "BEP Marine" 304 "Empir Bus" 305 "NovAtel" 306 "Sleipner Motor" 307 "MBW Technologies" 315 "ICOM" 328 "Qwerty" 329 "Dief" 341 "Boening Automationstechnologie" 345 "Korean Maritime University" 351 "Thrane and Thrane" 355 "Mastervolt" 356 "Fischer Panda Generators" 358 "Victron Energy" 370 "Rolls Royce Marine" 373 "Electronic Design" 374 "Northern Lights" 378 "Glendinning" 381 "B & G" 384 "Rose Point Navigation Systems" 385 "Johnson Outdoors Marine Electronics Inc Geonav" 394 "Capi 2" 396 "Beyond Measure" 400 "Livorsi Marine" 404 "ComNav" 409 "Chetco" 419 "Fusion Electronics" 421 "Standard Horizon" 422 "True Heading" 426 "Egersund Marine Electronics" 427 "em-trak Marine Electronics" 431 "Tohatsu Co, JP" 437 "Digital Yacht" 438 "Comar Systems Limited" 440 "Cummins" 443 "VDO (aka Continental-Corporation)" 451 "Parker Hannifin aka Village Marine Tech" 459 "Alltek Marine Electronics" 460 "SAN GIORGIO S.E.I.N" 466 "Veethree Electronics & Marine" 470 "SI-TEX Marine Electronics" 471 "Sea Cross Marine" 475 "GME aka Standard Communications" 476 "Humminbird Marine Electronics" 478 "Ocean Sat" 481 "Chetco Digital Instruments" 493 "Watcheye" 499 "Lcj Capteurs" 502 "Attwood Marine" 503 "Naviop S.R.L." 504 "Vesper Marine" 510 "Marinesoft" 513 "Simarine" 517 "NoLand Engineering" 518 "Transas USA" 529 "National Instruments Korea" 530 "National Marine Electronics Association" 532 "Onwa Marine" 540 "Webasto" 571 "Marinecraft (South Korea)" 573 "McMurdo Group aka Orolia" 578 "Advansea" 579 "KVH" 580 "San Jose Technology" 583 "Yacht Control" 586 "Suzuki Motor" 591 "US Coast Guard" 595 "Ship Module aka Customware" 600 "Aquatic AV" 605 "Aventics" 606 "Intellian" 612 "SamwonIT" 614 "Arlt Tecnologies" 637 "Bavaria Yachts" 641 "Diverse Yacht Services" 644 "Wema U.S.A dba KUS" 658 "Shenzhen Jiuzhou Himunication" 688 "Rockford" 699 "Harman International" 704 "JL Audio" 708 "Lars Thrane" 715 "Autonnic" 717 "Yacht Devices" 734 "REAP Systems" 735 "AEM Performance Electronics" 739 "LxNav" 741 "Littelfuse, Inc (formerly Carling Technologies)" 743 "DaeMyung" 744 "Woosung" 748 "ISOTTA IFRA srl" 773 "Clarion US" 776 "HMI Systems" 777 "Ocean Signal" 778 "Seakeeper" 781 "Poly Planar" 785 "Fischer Panda DE" 795 "Broyda Industries" 796 "Canadian Automotive" 797 "Tides Marine" 798 "Lumishore" 799 "Still Water Designs and Audio" 802 "BJ Technologies (Beneteau)" 803 "Gill Sensors" 811 "Blue Water Desalination" 815 "FLIR" 824 "Undheim Systems" 826 "Lewmar" 838 "TeamSurv" 844 "Fell Marine" 847 "Oceanvolt" 862 "Prospec" 868 "Data Panel" 890 "L3 Technologies" 894 "Rhodan Marine Systems" 896 "Nexfour Solutions" 905 "ASA Electronics" 909 "Marines Co (South Korea)" 911 "Nautic-on" 917 "Sentinel" 929 "JL Marine Systems" 930 "Ecotronix" 944 "Zontisa Marine" 951 "EXOR International" 962 "Timbolier Industries" 963 "TJC Micro" 968 "Cox Powertrain" 969 "Blue Seas" 981 "Kobelt Manufacturing" 992 "Blue Ocean IOT" 997 "Xenta Systems" 999 "Signal K" 1004 "Ultraflex" 1008 "Lintest SmartBoat" 1011 "Soundmax" 1020 "Team Italia Marine (Onyx Marine Automation s.r.l)" 1021 "Entratech" 1022 "ITC" 1029 "The Marine Guardian" 1047 "Sonic" 1051 "ProNav" 1053 "Vetus Maxwell INC." 1056 "Lithium Pros" 1059 "Boatrax" 1062 "Marol Co ltd" 1065 "CALYPSO Instruments" 1066 "Spot Zero Water" 1069 "Lithionics Battery" 1070 "Quick-teck Electronics" 1075 "Uniden America" 1083 "Nauticoncept" 1084 "Shadow-Caster LED lighting" 1085 "Wet Sounds" 1088 "E-T-A Circuit Breakers" 1092 "Scheiber" 1100 "Smart Yachts International Limited" 1109 "Dockmate" 1114 "Bobs Machine" 1118 "L3Harris ASV" 1119 "Balmar" 1120 "Elettromedia" 1127 "Electromaax" 1140 "Across Oceans Systems" 1145 "Kiwi Yachting" 1150 "BSB Artificial Intelligence" 1151 "Orca Technologies" 1154 "TBS Electronics" 1158 "Technoton Electroics" 1160 "MG Energy Systems" 1169 "Sea Machine Robotics" 1171 "Vista Manufacturing" 1183 "Zipwake" 1186 "Sailmon" 1192 "Airmoniq Pro Kft" 1194 "Sierra Marine" 1200 "Xinuo Information Technology (Xiamen)" 1218 "Septentrio" 1233 "NKE Marine Electronics" 1238 "SuperTrack Aps" 1239 "Honda Electronics" 1245 "Raritan Engineering" 1249 "Integrated Power Solutions AG" 1260 "Interactive Technologies" 1283 "LTG-Tech" 1299 "Energy Solutions (UK)" 1300 "WATT Fuel Cell" 1302 "Pro Mainer" 1305 "Dragonfly Energy" 1306 "Koden Electronics" 1311 "Humphree" 1316 "Hinkley Yachts" 1317 "Global Marine Management GmbH (GMM)" 1320 "Triskel Marine" 1330 "Warwick Control Technologies" 1331 "Dolphin Charger" 1337 "Barnacle Systems" 1348 "Radian IoT" 1353 "Ocean LED Marine" 1359 "BluNav" 1361 "OVA (Nantong Saiyang Electronics Co., Ltd)" 1368 "RAD Propulsion" 1369 "Electric Yacht" 1372 "Elco Motor Yachts" 1384 "Tecnoseal Foundry S.r.l" 1385 "Pro Charging Systems" 1389 "EVEX" 1398 "Gobius Sensor Technology" 1403 "Arco Marine" 1408 "Lenco Marine" 1413 "Naocontrol" 1417 "Revatek" 1438 "Aeolionics" 1439 "PredictWind" 1440 "Egis Mobile Electric" 1445 "Starboard Yacht Group" 1446 "Roswell Marine" 1451 "ePropulsion (Guangdong ePropulsion Technology Ltd.)" 1452 "Micro-Air" 1453 "Vital Battery" 1458 "Ride Controller" 1460 "Tocaro Blue" 1461 "Vanquish Yachts" 1471 "FT Technologies" 1478 "Alps Alpine" 1481 "E-Force Marine" 1482 "CMC Marine" 1483 "Nanjing Sandemarine Information Technology" 1850 "Teleflex Marine (SeaStar Solutions)" 1851 "Raymarine" 1852 "Navionics" 1853 "Japan Radio" 1854 "Northstar Technologies" 1855 "Furuno" 1856 "Trimble" 1857 "Simrad" 1858 "Litton" 1859 "Kvasar" 1860 "MMP" 1861 "Vector Cantech" 1862 "Yamaha Marine" 1863 "Faria Instruments" ;
VAL_ 2583642112 Industry_Code 0 "Global" 1 "Highway" 2 "Agriculture" 3 "Construction" 4 "Marine Industry" 5 "Industrial" ;
VAL_ 2583642368 Manufacturer_Code 69 "ARKS Enterprises" 78 "FW Murphy/Enovation Controls" 80 "Twin Disc" 85 "Kohler Power Systems" 88 "Hemisphere GPS" 135 "Airmar" 137 "Maretron" 140 "Lowrance" 144 "Mercury Marine" 147 "Nautibus Electronic" 148 "Blue Water Data" 154 "Westerbeke" 157 "ISSPRO" 161 "Offshore Systems (UK)" 163 "Evinrude/BRP" 165 "CPAC Systems" 168 "Xantrex Technology" 169 "Marlin Technologies" 172 "Yanmar Marine" 174 "Volvo Penta" 176 "Carling Technologies Inc. (Moritz Aerospace)" 185 "Beede Instruments" 192 "Floscan Instrument" 193 "Nobeltec" 198 "Mystic Valley Communications" 199 "Actia" 201 "Disenos Y Technologia" 211 "Digital Switching Systems" 215 "Xintex/Atena" 224 "EMMI NETWORK" 228 "ZF" 229 "Garmin" 233 "Yacht Monitoring Solutions" 235 "Sailormade Marine Telemetry/Tetra Technology" 243 "Eride" 257 "Honda Motor" 272 "Groco" 273 "Actisense" 274 "Amphenol LTW Technology" 275 "Navico" 283 "Hamilton Jet" 285 "Sea Recovery" 286 "Coelmo SRL Italy" 295 "BEP Marine" 304 "Empir Bus" 305 "NovAtel" 306 "Sleipner Motor" 307 "MBW Technologies" 315 "ICOM" 328 "Qwerty" 329 "Dief" 341 "Boening Automationstechnologie" 345 "Korean Maritime University" 351 "Thrane and Thrane" 355 "Mastervolt" 356 "Fischer Panda Generators" 358 "Victron Energy" 370 "Rolls Royce Marine" 373 "Electronic Design" 374 "Northern Lights" 378 "Glendinning" 381 "B & G" 384 "Rose Point Navigation Systems" 385 "Johnson Outdoors Marine Electronics Inc Geonav" 394 "Capi 2" 396 "Beyond Measure" 400 "Livorsi Marine" 404 "ComNav" 409 "Chetco" 419 "Fusion Electronics" 421 "Standard Horizon" 422 "True Heading" 426 "Egersund Marine Electronics" 427 "em-trak Marine Electronics" 431 "Tohatsu Co, JP" 437 "Digital Yacht" 438 "Comar Systems Limited" 440 "Cummins" 443 "VDO (aka Continental-Corporation)" 451 "Parker Hannifin aka Village Marine Tech" 459 "Alltek Marine Electronics" 460 "SAN GIORGIO S.E.I.N" 466 "Veethree Electronics & Marine" 470 "SI-TEX Marine Electronics" 471 "Sea Cross Marine" 475 "GME aka Standard Communications" 476 "Humminbird Marine Electronics" 478 "Ocean Sat" 481 "Chetco Digital Instruments" 493 "Watcheye" 499 "Lcj Capteurs" 502 "Attwood Marine" 503 "Naviop S.R.L." 504 "Vesper Marine" 510 "Marinesoft" 513 "Simarine" 517 "NoLand Engineering" 518 "Transas USA" 529 "National Instruments Korea" 530 "National Marine Electronics Association" 532 "Onwa Marine" 540 "Webasto" 571 "Marinecraft (South Korea)" 573 "McMurdo Group aka Orolia" 578 "Advansea" 579 "KVH" 580 "San Jose Technology" 583 "Yacht Control" 586 "Suzuki Motor" 591 "US Coast Guard" 595 "Ship Module aka Customware" 600 "Aquatic AV" 605 "Aventics" 606 "Intellian" 612 "SamwonIT" 614 "Arlt Tecnologies" 637 "Bavaria Yachts" 641 "Diverse Yacht Services" 644 "Wema U.S.A dba KUS" 658 "Shenzhen Jiuzhou Himunication" 688 "Rockford" 699 "Harman International" 704 "JL Audio" 708 "Lars Thrane" 715 "Autonnic" 717 "Yacht Devices" 734 "REAP Systems" 735 "AEM Performance Electronics" 739 "LxNav" 741 "Littelfuse, Inc (formerly Carling Technologies)" 743 "DaeMyung" 744 "Woosung" 748 "ISOTTA IFRA srl" 773 "Clarion US" 776 "HMI Systems" 777 "Ocean Signal" 778 "Seakeeper" 781 "Poly Planar" 785 "Fischer Panda DE" 795 "Broyda Industries" 796 "Canadian Automotive" 797 "Tides Marine" 798 "Lumishore" 799 "Still Water Designs and Audio" 802 "BJ Technologies (Beneteau)" 803 "Gill Sensors" 811 "Blue Water Desalination" 815 "FLIR" 824 "Undheim Systems" 826 "Lewmar" 838 "TeamSurv" 844 "Fell Marine" 847 "Oceanvolt" 862 "Prospec" 868 "Data Panel" 890 "L3 Technologies" 894 "Rhodan Marine Systems" 896 "Nexfour Solutions" 905 "ASA Electronics" 909 "Marines Co (South Korea)" 911 "Nautic-on" 917 "Sentinel" 929 "JL Marine Systems" 930 "Ecotronix" 944 "Zontisa Marine" 951 "EXOR International" 962 "Timbolier Industries" 963 "TJC Micro" 968 "Cox Powertrain" 969 "Blue Seas" 981 "Kobelt Manufacturing" 992 "Blue Ocean IOT" 997 "Xenta Systems" 999 "Signal K" 1004 "Ultraflex" 1008 "Lintest SmartBoat" 1011 "Soundmax" 1020 "Team Italia Marine (Onyx Marine Automation s.r.l)" 1021 "Entratech" 1022 "ITC" 1029 "The Marine Guardian" 1047 "Sonic" 1051 "ProNav" 1053 "Vetus Maxwell INC." 1056 "Lithium Pros" 1059 "Boatrax" 1062 "Marol Co ltd" 1065 "CALYPSO Instruments" 1066 "Spot Zero Water" 1069 "Lithionics Battery" 1070 "Quick-teck Electronics" 1075 "Uniden America" 1083 "Nauticoncept" 1084 "Shadow-Caster LED lighting" 1085 "Wet Sounds" 1088 "E-T-A Circuit Breakers" 1092 "Scheiber" 1100 "Smart Yachts International Limited" 1109 "Dockmate" 1114 "Bobs Machine" 1118 "L3Harris ASV" 1119 "Balmar" 1120 "Elettromedia" 1127 "Electromaax" 1140 "Across Oceans Systems" 1145 "Kiwi Yachting" 1150 "BSB Artificial Intelligence" 1151 "Orca Technologies" 1154 "TBS Electronics" 1158 "Technoton Electroics" 1160 "MG Energy Systems" 1169 "Sea Machine Robotics" 1171 "Vista Manufacturing" 1183 "Zipwake" 1186 "Sailmon" 1192 "Airmoniq Pro Kft" 1194 "Sierra Marine" 1200 "Xinuo Information Technology (Xiamen)" 1218 "Septentrio" 1233 "NKE Marine Electronics" 1238 "SuperTrack Aps" 1239 "Honda Electronics" 1245 "Raritan Engineering" 1249 "Integrated Power Solutions AG" 1260 "Interactive Technologies" 1283 "LTG-Tech" 1299 "Energy Solutions (UK)" 1300 "WATT Fuel Cell" 1302 "Pro Mainer" 1305 "Dragonfly Energy" 1306 "Koden Electronics" 1311 "Humphree" 1316 "Hinkley Yachts" 1317 "Global Marine Management GmbH (GMM)" 1320 "Triskel Marine" 1330 "Warwick Control Technologies" 1331 "Dolphin Charger" 1337 "Barnacle Systems" 1348 "Radian IoT" 1353 "Ocean LED Marine" 1359 "BluNav" 1361 "OVA (Nantong Saiyang Electronics Co., Ltd)" 1368 "RAD Propulsion" 1369 "Electric Yacht" 1372 "Elco Motor Yachts" 1384 "Tecnoseal Foundry S.r.l" 1385 "Pro Charging Systems" 1389 "EVEX" 1398 "Gobius Sensor Technology" 1403 "Arco Marine" 1408 "Lenco Marine" 1413 "Naocontrol" 1417 "Revatek" 1438 "Aeolionics" 1439 "PredictWind" 1440 "Egis Mobile Electric" 1445 "Starboard Yacht Group" 1446 "Roswell Marine" 1451 "ePropulsion (Guangdong ePropulsion Technology Ltd.)" 1452 "Micro-Air" 1453 "Vital Battery" 1458 "Ride Controller" 1460 "Tocaro Blue" 1461 "Vanquish Yachts" 1471 "FT Technologies" 1478 "Alps Alpine" 1481 "E-Force Marine" 1482 "CMC Marine" 1483 "Nanjing Sandemarine Information Technology" 1850 "Teleflex Marine (SeaStar Solutions)" 1851 "Raymarine" 1852 "Navionics" 1853 "Japan Radio" 1854 "Northstar Technologies" 1855 "Furuno" 1856 "Trimble" 1857 "Simrad" 1858 "Litton" 1859 "Kvasar" 1860 "MMP" 1861 "Vector Cantech" 1862 "Yamaha Marine" 1863 "Faria Instruments" ;
VAL_ 2583642368 Industry_Code 0 "Global" 1 "Highway" 2 "Agriculture" 3 "Construction" 4 "Marine Industry" 5 "Industrial" ;
VAL_ 2583647232 Manufacturer_Code 69 "ARKS Enterprises" 78 "FW Murphy/Enovation Controls" 80 "Twin Disc" 85 "Kohler Power Systems" 88 "Hemisphere GPS" 135 "Airmar" 137 "Maretron" 140 "Lowrance" 144 "Mercury Marine" 147 "Nautibus Electronic" 148 "Blue Water Data" 154 "Westerbeke" 157 "ISSPRO" 161 "Offshore Systems (UK)" 163 "Evinrude/BRP" 165 "CPAC Systems" 168 "Xantrex Technology" 169 "Marlin Technologies" 172 "Yanmar Marine" 174 "Volvo Penta" 176 "Carling Technologies Inc. (Moritz Aerospace)" 185 "Beede Instruments" 192 "Floscan Instrument" 193 "Nobeltec" 198 "Mystic Valley Communications" 199 "Actia" 201 "Disenos Y Technologia" 211 "Digital Switching Systems" 215 "Xintex/Atena" 224 "EMMI NETWORK" 228 "ZF" 229 "Garmin" 233 "Yacht Monitoring Solutions" 235 "Sailormade Marine Telemetry/Tetra Technology" 243 "Eride" 257 "Honda Motor" 272 "Groco" 273 "Actisense" 274 "Amphenol LTW Technology" 275 "Navico" 283 "Hamilton Jet" 285 "Sea Recovery" 286 "Coelmo SRL Italy" 295 "BEP Marine" 304 "Empir Bus" 305 "NovAtel" 306 "Sleipner Motor" 307 "MBW Technologies" 315 "ICOM" 328 "Qwerty" 329 "Dief" 341 "Boening Automationstechnologie" 345 "Korean Maritime University" 351 "Thrane and Thrane" 355 "Mastervolt" 356 "Fischer Panda Generators" 358 "Victron Energy" 370 "Rolls Royce Marine" 373 "Electronic Design" 374 "Northern Lights" 378 "Glendinning" 381 "B & G" 384 "Rose Point Navigation Systems" 385 "Johnson Outdoors Marine Electronics Inc Geonav" 394 "Capi 2" 396 "Beyond Measure" 400 "Livorsi Marine" 404 "ComNav" 409 "Chetco" 419 "Fusion Electronics" 421 "Standard Horizon" 422 "True Heading" 426 "Egersund Marine Electronics" 427 "em-trak Marine Electronics" 431 "Tohatsu Co, JP" 437 "Digital Yacht" 438 "Comar Systems Limited" 440 "Cummins" 443 "VDO (aka Continental-Corporation)" 451 "Parker Hannifin aka Village Marine Tech" 459 "Alltek Marine Electronics" 460 "SAN GIORGIO S.E.I.N" 466 "Veethree Electronics & Marine" 470 "SI-TEX Marine Electronics" 471 "Sea Cross Marine" 475 "GME aka Standard Communications" 476 "Humminbird Marine Electronics" 478 "Ocean Sat" 481 "Chetco Digital Instruments" 493 "Watcheye" 499 "Lcj Capteurs" 502 "Attwood Marine" 503 "Naviop S.R.L." 504 "Vesper Marine" 510 "Marinesoft" 513 "Simarine" 517 "NoLand Engineering" 518 "Transas USA" 529 "National Instruments Korea" 530 "National Marine Electronics Association" 532 "Onwa Marine" 540 "Webasto" 571 "Marinecraft (South Korea)" 573 "McMurdo Group aka Orolia" 578 "Advansea" 579 "KVH" 580 "San Jose Technology" 583 "Yacht Control" 586 "Suzuki Motor" 591 "US Coast Guard" 595 "Ship Module aka Customware" 600 "Aquatic AV" 605 "Aventics" 606 "Intellian" 612 "SamwonIT" 614 "Arlt Tecnologies" 637 "Bavaria Yachts" 641 "Diverse Yacht Services" 644 "Wema U.S.A dba KUS" 658 "Shenzhen Jiuzhou Himunication" 688 "Rockford" 699 "Harman International" 704 "JL Audio" 708 "Lars Thrane" 715 "Autonnic" 717 "Yacht Devices" 734 "REAP Systems" 735 "AEM Performance Electronics" 739 "LxNav" 741 "Littelfuse, Inc (formerly Carling Technologies)" 743 "DaeMyung" 744 "Woosung" 748 "ISOTTA IFRA srl" 773 "Clarion US" 776 "HMI Systems" 777 "Ocean Signal" 778 "Seakeeper" 781 "Poly Planar" 785 "Fischer Panda DE" 795 "Broyda Industries" 796 "Canadian Automotive" 797 "Tides Marine" 798 "Lumishore" 799 "Still Water Designs and Audio" 802 "BJ Technologies (Beneteau)" 803 "Gill Sensors" 811 "Blue Water Desalination" 815 "FLIR" 824 "Undheim Systems" 826 "Lewmar" 838 "TeamSurv" 844 "Fell Marine" 847 "Oceanvolt" 862 "Prospec" 868 "Data Panel" 890 "L3 Technologies" 894 "Rhodan Marine Systems" 896 "Nexfour Solutions" 905 "ASA Electronics" 909 "Marines Co (South Korea)" 911 "Nautic-on" 917 "Sentinel" 929 "JL Marine Systems" 930 "Ecotronix" 944 "Zontisa Marine" 951 "EXOR International" 962 "Timbolier Industries" 963 "TJC Micro" 968 "Cox Powertrain" 969 "Blue Seas" 981 "Kobelt Manufacturing" 992 "Blue Ocean IOT" 997 "Xenta Systems" 999 "Signal K" 1004 "Ultraflex" 1008 "Lintest SmartBoat" 1011 "Soundmax" 1020 "Team Italia Marine (Onyx Marine Automation s.r.l)" 1021 "Entratech" 1022 "ITC" 1029 "The Marine Guardian" 1047 "Sonic" 1051 "ProNav" 1053 "Vetus Maxwell INC." 1056 "Lithium Pros" 1059 "Boatrax" 1062 "Marol Co ltd" 1065 "CALYPSO Instruments" 1066 "Spot Zero Water" 1069 "Lithionics Battery" 1070 "Quick-teck Electronics" 1075 "Uniden America" 1083 "Nauticoncept" 1084 "Shadow-Caster LED lighting" 1085 "Wet Sounds" 1088 "E-T-A Circuit Breakers" 1092 "Scheiber" 1100 "Smart Yachts International Limited" 1109 "Dockmate" 1114 "Bobs Machine" 1118 "L3Harris ASV" 1119 "Balmar" 1120 "Elettromedia" 1127 "Electromaax" 1140 "Across Oceans Systems" 1145 "Kiwi Yachting" 1150 "BSB Artificial Intelligence" 1151 "Orca Technologies" 1154 "TBS Electronics" 1158 "Technoton Electroics" 1160 "MG Energy Systems" 1169 "Sea Machine Robotics" 1171 "Vista Manufacturing" 1183 "Zipwake" 1186 "Sailmon" 1192 "Airmoniq Pro Kft" 1194 "Sierra Marine" 1200 "Xinuo Information Technology (Xiamen)" 1218 "Septentrio" 1233 "NKE Marine Electronics" 1238 "SuperTrack Aps" 1239 "Honda Electronics" 1245 "Raritan Engineering" 1249 "Integrated Power Solutions AG" 1260 "Interactive Technologies" 1283 "LTG-Tech" 1299 "Energy Solutions (UK)" 1300 "WATT Fuel Cell" 1302 "Pro Mainer" 1305 "Dragonfly Energy" 1306 "Koden Electronics" 1311 "Humphree" 1316 "Hinkley Yachts" 1317 "Global Marine Management GmbH (GMM)" 1320 "Triskel Marine" 1330 "Warwick Control Technologies" 1331 "Dolphin Charger" 1337 "Barnacle Systems" 1348 "Radian IoT" 1353 "Ocean LED Marine" 1359 "BluNav" 1361 "OVA (Nantong Saiyang Electronics Co., Ltd)" 1368 "RAD Propulsion" 1369 "Electric Yacht" 1372 "Elco Motor Yachts" 1384 "Tecnoseal Foundry S.r.l" 1385 "Pro Charging Systems" 1389 "EVEX" 1398 "Gobius Sensor Technology" 1403 "Arco Marine" 1408 "Lenco Marine" 1413 "Naocontrol" 1417 "Revatek" 1438 "Aeolionics" 1439 "PredictWind" 1440 "Egis Mobile Electric" 1445 "Starboard Yacht Group" 1446 "Roswell Marine" 1451 "ePropulsion (Guangdong ePropulsion Technology Ltd.)" 1452 "Micro-Air" 1453 "Vital Battery" 1458 "Ride Controller" 1460 "Tocaro Blue" 1461 "Vanquish Yachts" 1471 "FT Technologies" 1478 "Alps Alpine" 1481 "E-Force Marine" 1482 "CMC Marine" 1483 "Nanjing Sandemarine Information Technology" 1850 "Teleflex Marine (SeaStar Solutions)" 1851 "Raymarine" 1852 "Navionics" 1853 "Japan Radio" 1854 "Northstar Technologies" 1855 "Furuno" 1856 "Trimble" 1857 "Simrad" 1858 "Litton" 1859 "Kvasar" 1860 "MMP" 1861 "Vector Cantech" 1862 "Yamaha Marine" 1863 "Faria Instruments" ;
VAL_ 2583647232 Industry_Code 0 "Global" 1 "Highway" 2 "Agriculture" 3 "Construction" 4 "Marine Industry" 5 "Industrial" ;
VAL_ 2583649792 Manufacturer_Code 69 "ARKS Enterprises" 78 "FW Murphy/Enovation Controls" 80 "Twin Disc" 85 "Kohler Power Systems" 88 "Hemisphere GPS" 135 "Airmar" 137 "Maretron" 140 "Lowrance" 144 "Mercury Marine" 147 "Nautibus Electronic" 148 "Blue Water Data" 154 "Westerbeke" 157 "ISSPRO" 161 "Offshore Systems (UK)" 163 "Evinrude/BRP" 165 "CPAC Systems" 168 "Xantrex Technology" 169 "Marlin Technologies" 172 "Yanmar Marine" 174 "Volvo Penta" 176 "Carling Technologies Inc. (Moritz Aerospace)" 185 "Beede Instruments" 192 "Floscan Instrument" 193 "Nobeltec" 198 "Mystic Valley Communications" 199 "Actia" 201 "Disenos Y Technologia" 211 "Digital Switching Systems" 215 "Xintex/Atena" 224 "EMMI NETWORK" 228 "ZF" 229 "Garmin" 233 "Yacht Monitoring Solutions" 235 "Sailormade Marine Telemetry/Tetra Technology" 243 "Eride" 257 "Honda Motor" 272 "Groco" 273 "Actisense" 274 "Amphenol LTW Technology" 275 "Navico" 283 "Hamilton Jet" 285 "Sea Recovery" 286 "Coelmo SRL Italy" 295 "BEP Marine" 304 "Empir Bus" 305 "NovAtel" 306 "Sleipner Motor" 307 "MBW Technologies" 315 "ICOM" 328 "Qwerty" 329 "Dief" 341 "Boening Automationstechnologie" 345 "Korean Maritime University" 351 "Thrane and Thrane" 355 "Mastervolt" 356 "Fischer Panda Generators" 358 "Victron Energy" 370 "Rolls Royce Marine" 373 "Electronic Design" 374 "Northern Lights" 378 "Glendinning" 381 "B & G" 384 "Rose Point Navigation Systems" 385 "Johnson Outdoors Marine Electronics Inc Geonav" 394 "Capi 2" 396 "Beyond Measure" 400 "Livorsi Marine" 404 "ComNav" 409 "Chetco" 419 "Fusion Electronics" 421 "Standard Horizon" 422 "True Heading" 426 "Egersund Marine Electronics" 427 "em-trak Marine Electronics" 431 "Tohatsu Co, JP" 437 "Digital Yacht" 438 "Comar Systems Limited" 440 "Cummins" 443 "VDO (aka Continental-Corporation)" 451 "Parker Hannifin aka Village Marine Tech" 459 "Alltek Marine Electronics" 460 "SAN GIORGIO S.E.I.N" 466 "Veethree Electronics & Marine" 470 "SI-TEX Marine Electronics" 471 "Sea Cross Marine" 475 "GME aka Standard Communications" 476 "Humminbird Marine Electronics" 478 "Ocean Sat" 481 "Chetco Digital Instruments" 493 "Watcheye" 499 "Lcj Capteurs" 502 "Attwood Marine" 503 "Naviop S.R.L." 504 "Vesper Marine" 510 "Marinesoft" 513 "Simarine" 517 "NoLand Engineering" 518 "Transas USA" 529 "National Instruments Korea" 530 "National Marine Electronics Association" 532 "Onwa Marine" 540 "Webasto" 571 "Marinecraft (South Korea)" 573 "McMurdo Group aka Orolia" 578 "Advansea" 579 "KVH" 580 "San Jose Technology" 583 "Yacht Control" 586 "Suzuki Motor" 591 "US Coast Guard" 595 "Ship Module aka Customware" 600 "Aquatic AV" 605 "Aventics" 606 "Intellian" 612 "SamwonIT" 614 "Arlt Tecnologies" 637 "Bavaria Yachts" 641 "Diverse Yacht Services" 644 "Wema U.S.A dba KUS" 658 "Shenzhen Jiuzhou Himunication" 688 "Rockford" 699 "Harman International" 704 "JL Audio" 708 "Lars Thrane" 715 "Autonnic" 717 "Yacht Devices" 734 "REAP Systems" 735 "AEM Performance Electronics" 739 "LxNav" 741 "Littelfuse, Inc (formerly Carling Technologies)" 743 "DaeMyung" 744 "Woosung" 748 "ISOTTA IFRA srl" 773 "Clarion US" 776 "HMI Systems" 777 "Ocean Signal" 778 "Seakeeper" 781 "Poly Planar" 785 "Fischer Panda DE" 795 "Broyda Industries" 796 "Canadian Automotive" 797 "Tides Marine" 798 "Lumishore" 799 "Still Water Designs and Audio" 802 "BJ Technologies (Beneteau)" 803 "Gill Sensors" 811 "Blue Water Desalination" 815 "FLIR" 824 "Undheim Systems" 826 "Lewmar" 838 "TeamSurv" 844 "Fell Marine" 847 "Oceanvolt" 862 "Prospec" 868 "Data Panel" 890 "L3 Technologies" 894 "Rhodan Marine Systems" 896 "Nexfour Solutions" 905 "ASA Electronics" 909 "Marines Co (South Korea)" 911 "Nautic-on" 917 "Sentinel" 929 "JL Marine Systems" 930 "Ecotronix" 944 "Zontisa Marine" 951 "EXOR International" 962 "Timbolier Industries" 963 "TJC Micro" 968 "Cox Powertrain" 969 "Blue Seas" 981 "Kobelt Manufacturing" 992 "Blue Ocean IOT" 997 "Xenta Systems" 999 "Signal K" 1004 "Ultraflex" 1008 "Lintest SmartBoat" 1011 "Soundmax" 1020 "Team Italia Marine (Onyx Marine Automation s.r.l)" 1021 "Entratech" 1022 "ITC" 1029 "The Marine Guardian" 1047 "Sonic" 1051 "ProNav" 1053 "Vetus Maxwell INC." 1056 "Lithium Pros" 1059 "Boatrax" 1062 "Marol Co ltd" 1065 "CALYPSO Instruments" 1066 "Spot Zero Water" 1069 "Lithionics Battery" 1070 "Quick-teck Electronics" 1075 "Uniden America" 1083 "Nauticoncept" 1084 "Shadow-Caster LED lighting" 1085 "Wet Sounds" 1088 "E-T-A Circuit Breakers" 1092 "Scheiber" 1100 "Smart Yachts International Limited" 1109 "Dockmate" 1114 "Bobs Machine" 1118 "L3Harris ASV" 1119 "Balmar" 1120 "Elettromedia" 1127 "Electromaax" 1140 "Across Oceans Systems" 1145 "Kiwi Yachting" 1150 "BSB Artificial Intelligence" 1151 "Orca Technologies" 1154 "TBS Electronics" 1158 "Technoton Electroics" 1160 "MG Energy Systems" 1169 "Sea Machine Robotics" 1171 "Vista Manufacturing" 1183 "Zipwake" 1186 "Sailmon" 1192 "Airmoniq Pro Kft" 1194 "Sierra Marine" 1200 "Xinuo Information Technology (Xiamen)" 1218 "Septentrio" 1233 "NKE Marine Electronics" 1238 "SuperTrack Aps" 1239 "Honda Electronics" 1245 "Raritan Engineering" 1249 "Integrated Power Solutions AG" 1260 "Interactive Technologies" 1283 "LTG-Tech" 1299 "Energy Solutions (UK)" 1300 "WATT Fuel Cell" 1302 "Pro Mainer" 1305 "Dragonfly Energy" 1306 "Koden Electronics" 1311 "Humphree" 1316 "Hinkley Yachts" 1317 "Global Marine Management GmbH (GMM)" 1320 "Triskel Marine" 1330 "Warwick Control Technologies" 1331 "Dolphin Charger" 1337 "Barnacle Systems" 1348 "Radian IoT" 1353 "Ocean LED Marine" 1359 "BluNav" 1361 "OVA (Nantong Saiyang Electronics Co., Ltd)" 1368 "RAD Propulsion" 1369 "Electric Yacht" 1372 "Elco Motor Yachts" 1384 "Tecnoseal Foundry S.r.l" 1385 "Pro Charging Systems" 1389 "EVEX" 1398 "Gobius Sensor Technology" 1403 "Arco Marine" 1408 "Lenco Marine" 1413 "Naocontrol" 1417 "Revatek" 1438 "Aeolionics" 1439 "PredictWind" 1440 "Egis Mobile Electric" 1445 "Starboard Yacht Group" 1446 "Roswell Marine" 1451 "ePropulsion (Guangdong ePropulsion Technology Ltd.)" 1452 "Micro-Air" 1453 "Vital Battery" 1458 "Ride Controller" 1460 "Tocaro Blue" 1461 "Vanquish Yachts" 1471 "FT Technologies" 1478 "Alps Alpine" 1481 "E-Force Marine" 1482 "CMC Marine" 1483 "Nanjing Sandemarine Information Technology" 1850 "Teleflex Marine (SeaStar Solutions)" 1851 "Raymarine" 1852 "Navionics" 1853 "Japan Radio" 1854 "Northstar Technologies" 1855 "Furuno" 1856 "Trimble" 1857 "Simrad" 1858 "Litton" 1859 "Kvasar" 1860 "MMP" 1861 "Vector Cantech" 1862 "Yamaha Marine" 1863 "Faria Instruments" ;
VAL_ 2583649792 Industry_Code 0 "Global" 1 "Highway" 2 "Agriculture" 3 "Construction" 4 "Marine Industry" 5 "Industrial" ;
VAL_ 2583650048 Manufacturer_Code 69 "ARKS Enterprises" 78 "FW Murphy/Enovation Controls" 80 "Twin Disc" 85 "Kohler Power Systems" 88 "Hemisphere GPS" 135 "Airmar" 137 "Maretron" 140 "Lowrance" 144 "Mercury Marine" 147 "Nautibus Electronic" 148 "Blue Water Data" 154 "Westerbeke" 157 "ISSPRO" 161 "Offshore Systems (UK)" 163 "Evinrude/BRP" 165 "CPAC Systems" 168 "Xantrex Technology" 169 "Marlin Technologies" 172 "Yanmar Marine" 174 "Volvo Penta" 176 "Carling Technologies Inc. (Moritz Aerospace)" 185 "Beede Instruments" 192 "Floscan Instrument" 193 "Nobeltec" 198 "Mystic Valley Communications" 199 "Actia" 201 "Disenos Y Technologia" 211 "Digital Switching Systems" 215 "Xintex/Atena" 224 "EMMI NETWORK" 228 "ZF" 229 "Garmin" 233 "Yacht Monitoring Solutions" 235 "Sailormade Marine Telemetry/Tetra Technology" 243 "Eride" 257 "Honda Motor" 272 "Groco" 273 "Actisense" 274 "Amphenol LTW Technology" 275 "Navico" 283 "Hamilton Jet" 285 "Sea Recovery" 286 "Coelmo SRL Italy" 295 "BEP Marine" 304 "Empir Bus" 305 "NovAtel" 306 "Sleipner Motor" 307 "MBW Technologies" 315 "ICOM" 328 "Qwerty" 329 "Dief" 341 "Boening Automationstechnologie" 345 "Korean Maritime University" 351 "Thrane and Thrane" 355 "Mastervolt" 356 "Fischer Panda Generators" 358 "Victron Energy" 370 "Rolls Royce Marine" 373 "Electronic Design" 374 "Northern Lights" 378 "Glendinning" 381 "B & G" 384 "Rose Point Navigation Systems" 385 "Johnson Outdoors Marine Electronics Inc Geonav" 394 "Capi 2" 396 "Beyond Measure" 400 "Livorsi Marine" 404 "ComNav" 409 "Chetco" 419 "Fusion Electronics" 421 "Standard Horizon" 422 "True Heading" 426 "Egersund Marine Electronics" 427 "em-trak Marine Electronics" 431 "Tohatsu Co, JP" 437 "Digital Yacht" 438 "Comar Systems Limited" 440 "Cummins" 443 "VDO (aka Continental-Corporation)" 451 "Parker Hannifin aka Village Marine Tech" 459 "Alltek Marine Electronics" 460 "SAN GIORGIO S.E.I.N" 466 "Veethree Electronics & Marine" 470 "SI-TEX Marine Electronics" 471 "Sea Cross Marine" 475 "GME aka Standard Communications" 476 "Humminbird Marine Electronics" 478 "Ocean Sat" 481 "Chetco Digital Instruments" 493 "Watcheye" 499 "Lcj Capteurs" 502 "Attwood Marine" 503 "Naviop S.R.L." 504 "Vesper Marine" 510 "Marinesoft" 513 "Simarine" 517 "NoLand Engineering" 518 "Transas USA" 529 "National Instruments Korea" 530 "National Marine Electronics Association" 532 "Onwa Marine" 540 "Webasto" 571 "Marinecraft (South Korea)" 573 "McMurdo Group aka Orolia" 578 "Advansea" 579 "KVH" 580 "San Jose Technology" 583 "Yacht Control" 586 "Suzuki Motor" 591 "US Coast Guard" 595 "Ship Module aka Customware" 600 "Aquatic AV" 605 "Aventics" 606 "Intellian" 612 "SamwonIT" 614 "Arlt Tecnologies" 637 "Bavaria Yachts" 641 "Diverse Yacht Services" 644 "Wema U.S.A dba KUS" 658 "Shenzhen Jiuzhou Himunication" 688 "Rockford" 699 "Harman International" 704 "JL Audio" 708 "Lars Thrane" 715 "Autonnic" 717 "Yacht Devices" 734 "REAP Systems" 735 "AEM Performance Electronics" 739 "LxNav" 741 "Littelfuse, Inc (formerly Carling Technologies)" 743 "DaeMyung" 744 "Woosung" 748 "ISOTTA IFRA srl" 773 "Clarion US" 776 "HMI Systems" 777 "Ocean Signal" 778 "Seakeeper" 781 "Poly Planar" 785 "Fischer Panda DE" 795 "Broyda Industries" 796 "Canadian Automotive" 797 "Tides Marine" 798 "Lumishore" 799 "Still Water Designs and Audio" 802 "BJ Technologies (Beneteau)" 803 "Gill Sensors" 811 "Blue Water Desalination" 815 "FLIR" 824 "Undheim Systems" 826 "Lewmar" 838 "TeamSurv" 844 "Fell Marine" 847 "Oceanvolt" 862 "Prospec" 868 "Data Panel" 890 "L3 Technologies" 894 "Rhodan Marine Systems" 896 "Nexfour Solutions" 905 "ASA Electronics" 909 "Marines Co (South Korea)" 911 "Nautic-on" 917 "Sentinel" 929 "JL Marine Systems" 930 "Ecotronix" 944 "Zontisa Marine" 951 "EXOR International" 962 "Timbolier Industries" 963 "TJC Micro" 968 "Cox Powertrain" 969 "Blue Seas" 981 "Kobelt Manufacturing" 992 "Blue Ocean IOT" 997 "Xenta Systems" 999 "Signal K" 1004 "Ultraflex" 1008 "Lintest SmartBoat" 1011 "Soundmax" 1020 "Team Italia Marine (Onyx Marine Automation s.r.l)" 1021 "Entratech" 1022 "ITC" 1029 "The Marine Guardian" 1047 "Sonic" 1051 "ProNav" 1053 "Vetus Maxwell INC." 1056 "Lithium Pros" 1059 "Boatrax" 1062 "Marol Co ltd" 1065 "CALYPSO Instruments" 1066 "Spot Zero Water" 1069 "Lithionics Battery" 1070 "Quick-teck Electronics" 1075 "Uniden America" 1083 "Nauticoncept" 1084 "Shadow-Caster LED lighting" 1085 "Wet Sounds" 1088 "E-T-A Circuit Breakers" 1092 "Scheiber" 1100 "Smart Yachts International Limited" 1109 "Dockmate" 1114 "Bobs Machine" 1118 "L3Harris ASV" 1119 "Balmar" 1120 "Elettromedia" 1127 "Electromaax" 1140 "Across Oceans Systems" 1145 "Kiwi Yachting" 1150 "BSB Artificial Intelligence" 1151 "Orca Technologies" 1154 "TBS Electronics" 1158 "Technoton Electroics" 1160 "MG Energy Systems" 1169 "Sea Machine Robotics" 1171 "Vista Manufacturing" 1183 "Zipwake" 1186 "Sailmon" 1192 "Airmoniq Pro Kft" 1194 "Sierra Marine" 1200 "Xinuo Information Technology (Xiamen)" 1218 "Septentrio" 1233 "NKE Marine Electronics" 1238 "SuperTrack Aps" 1239 "Honda Electronics" 1245 "Raritan Engineering" 1249 "Integrated Power Solutions AG" 1260 "Interactive Technologies" 1283 "LTG-Tech" 1299 "Energy Solutions (UK)" 1300 "WATT Fuel Cell" 1302 "Pro Mainer" 1305 "Dragonfly Energy" 1306 "Koden Electronics" 1311 "Humphree" 1316 "Hinkley Yachts" 1317 "Global Marine Management GmbH (GMM)" 1320 "Triskel Marine" 1330 "Warwick Control Technologies" 1331 "Dolphin Charger" 1337 "Barnacle Systems" 1348 "Radian IoT" 1353 "Ocean LED Marine" 1359 "BluNav" 1361 "OVA (Nantong Saiyang Electronics Co., Ltd)" 1368 "RAD Propulsion" 1369 "Electric Yacht" 1372 "Elco Motor Yachts" 1384 "Tecnoseal Foundry S.r.l" 1385 "Pro Charging Systems" 1389 "EVEX" 1398 "Gobius Sensor Technology" 1403 "Arco Marine" 1408 "Lenco Marine" 1413 "Naocontrol" 1417 "Revatek" 1438 "Aeolionics" 1439 "PredictWind" 1440 "Egis Mobile Electric" 1445 "Starboard Yacht Group" 1446 "Roswell Marine" 1451 "ePropulsion (Guangdong ePropulsion Technology Ltd.)" 1452 "Micro-Air" 1453 "Vital Battery" 1458 "Ride Controller" 1460 "Tocaro Blue" 1461 "Vanquish Yachts" 1471 "FT Technologies" 1478 "Alps Alpine" 1481 "E-Force Marine" 1482 "CMC Marine" 1483 "Nanjing Sandemarine Information Technology" 1850 "Teleflex Marine (SeaStar Solutions)" 1851 "Raymarine" 1852 "Navionics" 1853 "Japan Radio" 1854 "Northstar Technologies" 1855 "Furuno" 1856 "Trimble" 1857 "Simrad" 1858 "Litton" 1859 "Kvasar" 1860 "MMP" 1861 "Vector Cantech" 1862 "Yamaha Marine" 1863 "Faria Instruments" ;
VAL_ 2583650048 Industry_Code 0 "Global" 1 "Highway" 2 "Agriculture" 3 "Construction" 4 "Marine Industry" 5 "Industrial" ;
VAL_ 2583650304 Manufacturer_Code 69 "ARKS Enterprises" 78 "FW Murphy/Enovation Controls" 80 "Twin Disc" 85 "Kohler Power Systems" 88 "Hemisphere GPS" 135 "Airmar" 137 "Maretron" 140 "Lowrance" 144 "Mercury Marine" 147 "Nautibus Electronic" 148 "Blue Water Data" 154 "Westerbeke" 157 "ISSPRO" 161 "Offshore Systems (UK)" 163 "Evinrude/BRP" 165 "CPAC Systems" 168 "Xantrex Technology" 169 "Marlin Technologies" 172 "Yanmar Marine" 174 "Volvo Penta" 176 "Carling Technologies Inc. (Moritz Aerospace)" 185 "Beede Instruments" 192 "Floscan Instrument" 193 "Nobeltec" 198 "Mystic Valley Communications" 199 "Actia" 201 "Disenos Y Technologia" 211 "Digital Switching Systems" 215 "Xintex/Atena" 224 "EMMI NETWORK" 228 "ZF" 229 "Garmin" 233 "Yacht Monitoring Solutions" 235 "Sailormade Marine Telemetry/Tetra Technology" 243 "Eride" 257 "Honda Motor" 272 "Groco" 273 "Actisense" 274 "Amphenol LTW Technology" 275 "Navico" 283 "Hamilton Jet" 285 "Sea Recovery" 286 "Coelmo SRL Italy" 295 "BEP Marine" 304 "Empir Bus" 305 "NovAtel" 306 "Sleipner Motor" 307 "MBW Technologies" 315 "ICOM" 328 "Qwerty" 329 "Dief" 341 "Boening Automationstechnologie" 345 "Korean Maritime University" 351 "Thrane and Thrane" 355 "Mastervolt" 356 "Fischer Panda Generators" 358 "Victron Energy" 370 "Rolls Royce Marine" 373 "Electronic Design" 374 "Northern Lights" 378 "Glendinning" 381 "B & G" 384 "Rose Point Navigation Systems" 385 "Johnson Outdoors Marine Electronics Inc Geonav" 394 "Capi 2" 396 "Beyond Measure" 400 "Livorsi Marine" 404 "ComNav" 409 "Chetco" 419 "Fusion Electronics" 421 "Standard Horizon" 422 "True Heading" 426 "Egersund Marine Electronics" 427 "em-trak Marine Electronics" 431 "Tohatsu Co, JP" 437 "Digital Yacht" 438 "Comar Systems Limited" 440 "Cummins" 443 "VDO (aka Continental-Corporation)" 451 "Parker Hannifin aka Village Marine Tech" 459 "Alltek Marine Electronics" 460 "SAN GIORGIO S.E.I.N" 466 "Veethree Electronics & Marine" 470 "SI-TEX Marine Electronics" 471 "Sea Cross Marine" 475 "GME aka Standard Communications" 476 "Humminbird Marine Electronics" 478 "Ocean Sat" 481 "Chetco Digital Instruments" 493 "Watcheye" 499 "Lcj Capteurs" 502 "Attwood Marine" 503 "Naviop S.R.L." 504 "Vesper Marine" 510 "Marinesoft" 513 "Simarine" 517 "NoLand Engineering" 518 "Transas USA" 529 "National Instruments Korea" 530 "National Marine Electronics Association" 532 "Onwa Marine" 540 "Webasto" 571 "Marinecraft (South Korea)" 573 "McMurdo Group aka Orolia" 578 "Advansea" 579 "KVH" 580 "San Jose Technology" 583 "Yacht Control" 586 "Suzuki Motor" 591 "US Coast Guard" 595 "Ship Module aka Customware" 600 "Aquatic AV" 605 "Aventics" 606 "Intellian" 612 "SamwonIT" 614 "Arlt Tecnologies" 637 "Bavaria Yachts" 641 "Diverse Yacht Services" 644 "Wema U.S.A dba KUS" 658 "Shenzhen Jiuzhou Himunication" 688 "Rockford" 699 "Harman International" 704 "JL Audio" 708 "Lars Thrane" 715 "Autonnic" 717 "Yacht Devices" 734 "REAP Systems" 735 "AEM Performance Electronics" 739 "LxNav" 741 "Littelfuse, Inc (formerly Carling Technologies)" 743 "DaeMyung" 744 "Woosung" 748 "ISOTTA IFRA srl" 773 "Clarion US" 776 "HMI Systems" 777 "Ocean Signal" 778 "Seakeeper" 781 "Poly Planar" 785 "Fischer Panda DE" 795 "Broyda Industries" 796 "Canadian Automotive" 797 "Tides Marine" 798 "Lumishore" 799 "Still Water Designs and Audio" 802 "BJ Technologies (Beneteau)" 803 "Gill Sensors" 811 "Blue Water Desalination" 815 "FLIR" 824 "Undheim Systems" 826 "Lewmar" 838 "TeamSurv" 844 "Fell Marine" 847 "Oceanvolt" 862 "Prospec" 868 "Data Panel" 890 "L3 Technologies" 894 "Rhodan Marine Systems" 896 "Nexfour Solutions" 905 "ASA Electronics" 909 "Marines Co (South Korea)" 911 "Nautic-on" 917 "Sentinel" 929 "JL Marine Systems" 930 "Ecotronix" 944 "Zontisa Marine" 951 "EXOR International" 962 "Timbolier Industries" 963 "TJC Micro" 968 "Cox Powertrain" 969 "Blue Seas" 981 "Kobelt Manufacturing" 992 "Blue Ocean IOT" 997 "Xenta Systems" 999 "Signal K" 1004 "Ultraflex" 1008 "Lintest SmartBoat" 1011 "Soundmax" 1020 "Team Italia Marine (Onyx Marine Automation s.r.l)" 1021 "Entratech" 1022 "ITC" 1029 "The Marine Guardian" 1047 "Sonic" 1051 "ProNav" 1053 "Vetus Maxwell INC." 1056 "Lithium Pros" 1059 "Boatrax" 1062 "Marol Co ltd" 1065 "CALYPSO Instruments" 1066 "Spot Zero Water" 1069 "Lithionics Battery" 1070 "Quick-teck Electronics" 1075 "Uniden America" 1083 "Nauticoncept" 1084 "Shadow-Caster LED lighting" 1085 "Wet Sounds" 1088 "E-T-A Circuit Breakers" 1092 "Scheiber" 1100 "Smart Yachts International Limited" 1109 "Dockmate" 1114 "Bobs Machine" 1118 "L3Harris ASV" 1119 "Balmar" 1120 "Elettromedia" 1127 "Electromaax" 1140 "Across Oceans Systems" 1145 "Kiwi Yachting" 1150 "BSB Artificial Intelligence" 1151 "Orca Technologies" 1154 "TBS Electronics" 1158 "Technoton Electroics" 1160 "MG Energy Systems" 1169 "Sea Machine Robotics" 1171 "Vista Manufacturing" 1183 "Zipwake" 1186 "Sailmon" 1192 "Airmoniq Pro Kft" 1194 "Sierra Marine" 1200 "Xinuo Information Technology (Xiamen)" 1218 "Septentrio" 1233 "NKE Marine Electronics" 1238 "SuperTrack Aps" 1239 "Honda Electronics" 1245 "Raritan Engineering" 1249 "Integrated Power Solutions AG" 1260 "Interactive Technologies" 1283 "LTG-Tech" 1299 "Energy Solutions (UK)" 1300 "WATT Fuel Cell" 1302 "Pro Mainer" 1305 "Dragonfly Energy" 1306 "Koden Electronics" 1311 "Humphree" 1316 "Hinkley Yachts" 1317 "Global Marine Management GmbH (GMM)" 1320 "Triskel Marine" 1330 "Warwick Control Technologies" 1331 "Dolphin Charger" 1337 "Barnacle Systems" 1348 "Radian IoT" 1353 "Ocean LED Marine" 1359 "BluNav" 1361 "OVA (Nantong Saiyang Electronics Co., Ltd)" 1368 "RAD Propulsion" 1369 "Electric Yacht" 1372 "Elco Motor Yachts" 1384 "Tecnoseal Foundry S.r.l" 1385 "Pro Charging Systems" 1389 "EVEX" 1398 "Gobius Sensor Technology" 1403 "Arco Marine" 1408 "Lenco Marine" 1413 "Naocontrol" 1417 "Revatek" 1438 "Aeolionics" 1439 "PredictWind" 1440 "Egis Mobile Electric" 1445 "Starboard Yacht Group" 1446 "Roswell Marine" 1451 "ePropulsion (Guangdong ePropulsion Technology Ltd.)" 1452 "Micro-Air" 1453 "Vital Battery" 1458 "Ride Controller" 1460 "Tocaro Blue" 1461 "Vanquish Yachts" 1471 "FT Technologies" 1478 "Alps Alpine" 1481 "E-Force Marine" 1482 "CMC Marine" 1483 "Nanjing Sandemarine Information Technology" 1850 "Teleflex Marine (SeaStar Solutions)" 1851 "Raymarine" 1852 "Navionics" 1853 "Japan Radio" 1854 "Northstar Technologies" 1855 "Furuno" 1856 "Trimble" 1857 "Simrad" 1858 "Litton" 1859 "Kvasar" 1860 "MMP" 1861 "Vector Cantech" 1862 "Yamaha Marine" 1863 "Faria Instruments" ;
VAL_ 2583650304 Industry_Code 0 "Global" 1 "Highway" 2 "Agriculture" 3 "Construction" 4 "Marine Industry" 5 "Industrial" ;
VAL_ 2583650560 Manufacturer_Code 69 "ARKS Enterprises" 78 "FW Murphy/Enovation Controls" 80 "Twin Disc" 85 "Kohler Power Systems" 88 "Hemisphere GPS" 135 "Airmar" 137 "Maretron" 140 "Lowrance" 144 "Mercury Marine" 147 "Nautibus Electronic" 148 "Blue Water Data" 154 "Westerbeke" 157 "ISSPRO" 161 "Offshore Systems (UK)" 163 "Evinrude/BRP" 165 "CPAC Systems" 168 "Xantrex Technology" 169 "Marlin Technologies" 172 "Yanmar Marine" 174 "Volvo Penta" 176 "Carling Technologies Inc. (Moritz Aerospace)" 185 "Beede Instruments" 192 "Floscan Instrument" 193 "Nobeltec" 198 "Mystic Valley Communications" 199 "Actia" 201 "Disenos Y Technologia" 211 "Digital Switching Systems" 215 "Xintex/Atena" 224 "EMMI NETWORK" 228 "ZF" 229 "Garmin" 233 "Yacht Monitoring Solutions" 235 "Sailormade Marine Telemetry/Tetra Technology" 243 "Eride" 257 "Honda Motor" 272 "Groco" 273 "Actisense" 274 "Amphenol LTW Technology" 275 "Navico" 283 "Hamilton Jet" 285 "Sea Recovery" 286 "Coelmo SRL Italy" 295 "BEP Marine" 304 "Empir Bus" 305 "NovAtel" 306 "Sleipner Motor" 307 "MBW Technologies" 315 "ICOM" 328 "Qwerty" 329 "Dief" 341 "Boening Automationstechnologie" 345 "Korean Maritime University" 351 "Thrane and Thrane" 355 "Mastervolt" 356 "Fischer Panda Generators" 358 "Victron Energy" 370 "Rolls Royce Marine" 373 "Electronic Design" 374 "Northern Lights" 378 "Glendinning" 381 "B & G" 384 "Rose Point Navigation Systems" 385 "Johnson Outdoors Marine Electronics Inc Geonav" 394 "Capi 2" 396 "Beyond Measure" 400 "Livorsi Marine" 404 "ComNav" 409 "Chetco" 419 "Fusion Electronics" 421 "Standard Horizon" 422 "True Heading" 426 "Egersund Marine Electronics" 427 "em-trak Marine Electronics" 431 "Tohatsu Co, JP" 437 "Digital Yacht" 438 "Comar Systems Limited" 440 "Cummins" 443 "VDO (aka Continental-Corporation)" 451 "Parker Hannifin aka Village Marine Tech" 459 "Alltek Marine Electronics" 460 "SAN GIORGIO S.E.I.N" 466 "Veethree Electronics & Marine" 470 "SI-TEX Marine Electronics" 471 "Sea Cross Marine" 475 "GME aka Standard Communications" 476 "Humminbird Marine Electronics" 478 "Ocean Sat" 481 "Chetco Digital Instruments" 493 "Watcheye" 499 "Lcj Capteurs" 502 "Attwood Marine" 503 "Naviop S.R.L." 504 "Vesper Marine" 510 "Marinesoft" 513 "Simarine" 517 "NoLand Engineering" 518 "Transas USA" 529 "National Instruments Korea" 530 "National Marine Electronics Association" 532 "Onwa Marine" 540 "Webasto" 571 "Marinecraft (South Korea)" 573 "McMurdo Group aka Orolia" 578 "Advansea" 579 "KVH" 580 "San Jose Technology" 583 "Yacht Control" 586 "Suzuki Motor" 591 "US Coast Guard" 595 "Ship Module aka Customware" 600 "Aquatic AV" 605 "Aventics" 606 "Intellian" 612 "SamwonIT" 614 "Arlt Tecnologies" 637 "Bavaria Yachts" 641 "Diverse Yacht Services" 644 "Wema U.S.A dba KUS" 658 "Shenzhen Jiuzhou Himunication" 688 "Rockford" 699 "Harman International" 704 "JL Audio" 708 "Lars Thrane" 715 "Autonnic" 717 "Yacht Devices" 734 "REAP Systems" 735 "AEM Performance Electronics" 739 "LxNav" 741 "Littelfuse, Inc (formerly Carling Technologies)" 743 "DaeMyung" 744 "Woosung" 748 "ISOTTA IFRA srl" 773 "Clarion US" 776 "HMI Systems" 777 "Ocean Signal" 778 "Seakeeper" 781 "Poly Planar" 785 "Fischer Panda DE" 795 "Broyda Industries" 796 "Canadian Automotive" 797 "Tides Marine" 798 "Lumishore" 799 "Still Water Designs and Audio" 802 "BJ Technologies (Beneteau)" 803 "Gill Sensors" 811 "Blue Water Desalination" 815 "FLIR" 824 "Undheim Systems" 826 "Lewmar" 838 "TeamSurv" 844 "Fell Marine" 847 "Oceanvolt" 862 "Prospec" 868 "Data Panel" 890 "L3 Technologies" 894 "Rhodan Marine Systems" 896 "Nexfour Solutions" 905 "ASA Electronics" 909 "Marines Co (South Korea)" 911 "Nautic-on" 917 "Sentinel" 929 "JL Marine Systems" 930 "Ecotronix" 944 "Zontisa Marine" 951 "EXOR International" 962 "Timbolier Industries" 963 "TJC Micro" 968 "Cox Powertrain" 969 "Blue Seas" 981 "Kobelt Manufacturing" 992 "Blue Ocean IOT" 997 "Xenta Systems" 999 "Signal K" 1004 "Ultraflex" 1008 "Lintest SmartBoat" 1011 "Soundmax" 1020 "Team Italia Marine (Onyx Marine Automation s.r.l)" 1021 "Entratech" 1022 "ITC" 1029 "The Marine Guardian" 1047 "Sonic" 1051 "ProNav" 1053 "Vetus Maxwell INC." 1056 "Lithium Pros" 1059 "Boatrax" 1062 "Marol Co ltd" 1065 "CALYPSO Instruments" 1066 "Spot Zero Water" 1069 "Lithionics Battery" 1070 "Quick-teck Electronics" 1075 "Uniden America" 1083 "Nauticoncept" 1084 "Shadow-Caster LED lighting" 1085 "Wet Sounds" 1088 "E-T-A Circuit Breakers" 1092 "Scheiber" 1100 "Smart Yachts International Limited" 1109 "Dockmate" 1114 "Bobs Machine" 1118 "L3Harris ASV" 1119 "Balmar" 1120 "Elettromedia" 1127 "Electromaax" 1140 "Across Oceans Systems" 1145 "Kiwi Yachting" 1150 "BSB Artificial Intelligence" 1151 "Orca Technologies" 1154 "TBS Electronics" 1158 "Technoton Electroics" 1160 "MG Energy Systems" 1169 "Sea Machine Robotics" 1171 "Vista Manufacturing" 1183 "Zipwake" 1186 "Sailmon" 1192 "Airmoniq Pro Kft" 1194 "Sierra Marine" 1200 "Xinuo Information Technology (Xiamen)" 1218 "Septentrio" 1233 "NKE Marine Electronics" 1238 "SuperTrack Aps" 1239 "Honda Electronics" 1245 "Raritan Engineering" 1249 "Integrated Power Solutions AG" 1260 "Interactive Technologies" 1283 "LTG-Tech" 1299 "Energy Solutions (UK)" 1300 "WATT Fuel Cell" 1302 "Pro Mainer" 1305 "Dragonfly Energy" 1306 "Koden Electronics" 1311 "Humphree" 1316 "Hinkley Yachts" 1317 "Global Marine Management GmbH (GMM)" 1320 "Triskel Marine" 1330 "Warwick Control Technologies" 1331 "Dolphin Charger" 1337 "Barnacle Systems" 1348 "Radian IoT" 1353 "Ocean LED Marine" 1359 "BluNav" 1361 "OVA (Nantong Saiyang Electronics Co., Ltd)" 1368 "RAD Propulsion" 1369 "Electric Yacht" 1372 "Elco Motor Yachts" 1384 "Tecnoseal Foundry S.r.l" 1385 "Pro Charging Systems" 1389 "EVEX" 1398 "Gobius Sensor Technology" 1403 "Arco Marine" 1408 "Lenco Marine" 1413 "Naocontrol" 1417 "Revatek" 1438 "Aeolionics" 1439 "PredictWind" 1440 "Egis Mobile Electric" 1445 "Starboard Yacht Group" 1446 "Roswell Marine" 1451 "ePropulsion (Guangdong ePropulsion Technology Ltd.)" 1452 "Micro-Air" 1453 "Vital Battery" 1458 "Ride Controller" 1460 "Tocaro Blue" 1461 "Vanquish Yachts" 1471 "FT Technologies" 1478 "Alps Alpine" 1481 "E-Force Marine" 1482 "CMC Marine" 1483 "Nanjing Sandemarine Information Technology" 1850 "Teleflex Marine (SeaStar Solutions)" 1851 "Raymarine" 1852 "Navionics" 1853 "Japan Radio" 1854 "Northstar Technologies" 1855 "Furuno" 1856 "Trimble" 1857 "Simrad" 1858 "Litton" 1859 "Kvasar" 1860 "MMP" 1861 "Vector Cantech" 1862 "Yamaha Marine" 1863 "Faria Instruments" ;
VAL_ 2583650560 Industry_Code 0 "Global" 1 "Highway" 2 "Agriculture" 3 "Construction" 4 "Marine Industry" 5 "Industrial" ;
VAL_ 2650760704 Manufacturer_Code 69 "ARKS Enterprises" 78 "FW Murphy/Enovation Controls" 80 "Twin Disc" 85 "Kohler Power Systems" 88 "Hemisphere GPS" 135 "Airmar" 137 "Maretron" 140 "Lowrance" 144 "Mercury Marine" 147 "Nautibus Electronic" 148 "Blue Water Data" 154 "Westerbeke" 157 "ISSPRO" 161 "Offshore Systems (UK)" 163 "Evinrude/BRP" 165 "CPAC Systems" 168 "Xantrex Technology" 169 "Marlin Technologies" 172 "Yanmar Marine" 174 "Volvo Penta" 176 "Carling Technologies Inc. (Moritz Aerospace)" 185 "Beede Instruments" 192 "Floscan Instrument" 193 "Nobeltec" 198 "Mystic Valley Communications" 199 "Actia" 201 "Disenos Y Technologia" 211 "Digital Switching Systems" 215 "Xintex/Atena" 224 "EMMI NETWORK" 228 "ZF" 229 "Garmin" 233 "Yacht Monitoring Solutions" 235 "Sailormade Marine Telemetry/Tetra Technology" 243 "Eride" 257 "Honda Motor" 272 "Groco" 273 "Actisense" 274 "Amphenol LTW Technology" 275 "Navico" 283 "Hamilton Jet" 285 "Sea Recovery" 286 "Coelmo SRL Italy" 295 "BEP Marine" 304 "Empir Bus" 305 "NovAtel" 306 "Sleipner Motor" 307 "MBW Technologies" 315 "ICOM" 328 "Qwerty" 329 "Dief" 341 "Boening Automationstechnologie" 345 "Korean Maritime University" 351 "Thrane and Thrane" 355 "Mastervolt" 356 "Fischer Panda Generators" 358 "Victron Energy" 370 "Rolls Royce Marine" 373 "Electronic Design" 374 "Northern Lights" 378 "Glendinning" 381 "B & G" 384 "Rose Point Navigation Systems" 385 "Johnson Outdoors Marine Electronics Inc Geonav" 394 "Capi 2" 396 "Beyond Measure" 400 "Livorsi Marine" 404 "ComNav" 409 "Chetco" 419 "Fusion Electronics" 421 "Standard Horizon" 422 "True Heading" 426 "Egersund Marine Electronics" 427 "em-trak Marine Electronics" 431 "Tohatsu Co, JP" 437 "Digital Yacht" 438 "Comar Systems Limited" 440 "Cummins" 443 "VDO (aka Continental-Corporation)" 451 "Parker Hannifin aka Village Marine Tech" 459 "Alltek Marine Electronics" 460 "SAN GIORGIO S.E.I.N" 466 "Veethree Electronics & Marine" 470 "SI-TEX Marine Electronics" 471 "Sea Cross Marine" 475 "GME aka Standard Communications" 476 "Humminbird Marine Electronics" 478 "Ocean Sat" 481 "Chetco Digital Instruments" 493 "Watcheye" 499 "Lcj Capteurs" 502 "Attwood Marine" 503 "Naviop S.R.L." 504 "Vesper Marine" 510 "Marinesoft" 513 "Simarine" 517 "NoLand Engineering" 518 "Transas USA" 529 "National Instruments Korea" 530 "National Marine Electronics Association" 532 "Onwa Marine" 540 "Webasto" 571 "Marinecraft (South Korea)" 573 "McMurdo Group aka Orolia" 578 "Advansea" 579 "KVH" 580 "San Jose Technology" 583 "Yacht Control" 586 "Suzuki Motor" 591 "US Coast Guard" 595 "Ship Module aka Customware" 600 "Aquatic AV" 605 "Aventics" 606 "Intellian" 612 "SamwonIT" 614 "Arlt Tecnologies" 637 "Bavaria Yachts" 641 "Diverse Yacht Services" 644 "Wema U.S.A dba KUS" 658 "Shenzhen Jiuzhou Himunication" 688 "Rockford" 699 "Harman International" 704 "JL Audio" 708 "Lars Thrane" 715 "Autonnic" 717 "Yacht Devices" 734 "REAP Systems" 735 "AEM Performance Electronics" 739 "LxNav" 741 "Littelfuse, Inc (formerly Carling Technologies)" 743 "DaeMyung" 744 "Woosung" 748 "ISOTTA IFRA srl" 773 "Clarion US" 776 "HMI Systems" 777 "Ocean Signal" 778 "Seakeeper" 781 "Poly Planar" 785 "Fischer Panda DE" 795 "Broyda Industries" 796 "Canadian Automotive" 797 "Tides Marine" 798 "Lumishore" 799 "Still Water Designs and Audio" 802 "BJ Technologies (Beneteau)" 803 "Gill Sensors" 811 "Blue Water Desalination" 815 "FLIR" 824 "Undheim Systems" 826 "Lewmar" 838 "TeamSurv" 844 "Fell Marine" 847 "Oceanvolt" 862 "Prospec" 868 "Data Panel" 890 "L3 Technologies" 894 "Rhodan Marine Systems" 896 "Nexfour Solutions" 905 "ASA Electronics" 909 "Marines Co (South Korea)" 911 "Nautic-on" 917 "Sentinel" 929 "JL Marine Systems" 930 "Ecotronix" 944 "Zontisa Marine" 951 "EXOR International" 962 "Timbolier Industries" 963 "TJC Micro" 968 "Cox Powertrain" 969 "Blue Seas" 981 "Kobelt Manufacturing" 992 "Blue Ocean IOT" 997 "Xenta Systems" 999 "Signal K" 1004 "Ultraflex" 1008 "Lintest SmartBoat" 1011 "Soundmax" 1020 "Team Italia Marine (Onyx Marine Automation s.r.l)" 1021 "Entratech" 1022 "ITC" 1029 "The Marine Guardian" 1047 "Sonic" 1051 "ProNav" 1053 "Vetus Maxwell INC." 1056 "Lithium Pros" 1059 "Boatrax" 1062 "Marol Co ltd" 1065 "CALYPSO Instruments" 1066 "Spot Zero Water" 1069 "Lithionics Battery" 1070 "Quick-teck Electronics" 1075 "Uniden America" 1083 "Nauticoncept" 1084 "Shadow-Caster LED lighting" 1085 "Wet Sounds" 1088 "E-T-A Circuit Breakers" 1092 "Scheiber" 1100 "Smart Yachts International Limited" 1109 "Dockmate" 1114 "Bobs Machine" 1118 "L3Harris ASV" 1119 "Balmar" 1120 "Elettromedia" 1127 "Electromaax" 1140 "Across Oceans Systems" 1145 "Kiwi Yachting" 1150 "BSB Artificial Intelligence" 1151 "Orca Technologies" 1154 "TBS Electronics" 1158 "Technoton Electroics" 1160 "MG Energy Systems" 1169 "Sea Machine Robotics" 1171 "Vista Manufacturing" 1183 "Zipwake" 1186 "Sailmon" 1192 "Airmoniq Pro Kft" 1194 "Sierra Marine" 1200 "Xinuo Information Technology (Xiamen)" 1218 "Septentrio" 1233 "NKE Marine Electronics" 1238 "SuperTrack Aps" 1239 "Honda Electronics" 1245 "Raritan Engineering" 1249 "Integrated Power Solutions AG" 1260 "Interactive Technologies" 1283 "LTG-Tech" 1299 "Energy Solutions (UK)" 1300 "WATT Fuel Cell" 1302 "Pro Mainer" 1305 "Dragonfly Energy" 1306 "Koden Electronics" 1311 "Humphree" 1316 "Hinkley Yachts" 1317 "Global Marine Management GmbH (GMM)" 1320 "Triskel Marine" 1330 "Warwick Control Technologies" 1331 "Dolphin Charger" 1337 "Barnacle Systems" 1348 "Radian IoT" 1353 "Ocean LED Marine" 1359 "BluNav" 1361 "OVA (Nantong Saiyang Electronics Co., Ltd)" 1368 "RAD Propulsion" 1369 "Electric Yacht" 1372 "Elco Motor Yachts" 1384 "Tecnoseal Foundry S.r.l" 1385 "Pro Charging Systems" 1389 "EVEX" 1398 "Gobius Sensor Technology" 1403 "Arco Marine" 1408 "Lenco Marine" 1413 "Naocontrol" 1417 "Revatek" 1438 "Aeolionics" 1439 "PredictWind" 1440 "Egis Mobile Electric" 1445 "Starboard Yacht Group" 1446 "Roswell Marine" 1451 "ePropulsion (Guangdong ePropulsion Technology Ltd.)" 1452 "Micro-Air" 1453 "Vital Battery" 1458 "Ride Controller" 1460 "Tocaro Blue" 1461 "Vanquish Yachts" 1471 "FT Technologies" 1478 "Alps Alpine" 1481 "E-Force Marine" 1482 "CMC Marine" 1483 "Nanjing Sandemarine Information Technology" 1850 "Teleflex Marine (SeaStar Solutions)" 1851 "Raymarine" 1852 "Navionics" 1853 "Japan Radio" 1854 "Northstar Technologies" 1855 "Furuno" 1856 "Trimble" 1857 "Simrad" 1858 "Litton" 1859 "Kvasar" 1860 "MMP" 1861 "Vector Cantech" 1862 "Yamaha Marine" 1863 "Faria Instruments" ;
VAL_ 2650760704 Industry_Code 0 "Global" 1 "Highway" 2 "Agriculture" 3 "Construction" 4 "Marine Industry" 5 "Industrial" ;
VAL_ 2583652608 Manufacturer_Code 69 "ARKS Enterprises" 78 "FW Murphy/Enovation Controls" 80 "Twin Disc" 85 "Kohler Power Systems" 88 "Hemisphere GPS" 135 "Airmar" 137 "Maretron" 140 "Lowrance" 144 "Mercury Marine" 147 "Nautibus Electronic" 148 "Blue Water Data" 154 "Westerbeke" 157 "ISSPRO" 161 "Offshore Systems (UK)" 163 "Evinrude/BRP" 165 "CPAC Systems" 168 "Xantrex Technology" 169 "Marlin Technologies" 172 "Yanmar Marine" 174 "Volvo Penta" 176 "Carling Technologies Inc. (Moritz Aerospace)" 185 "Beede Instruments" 192 "Floscan Instrument" 193 "Nobeltec" 198 "Mystic Valley Communications" 199 "Actia" 201 "Disenos Y Technologia" 211 "Digital Switching Systems" 215 "Xintex/Atena" 224 "EMMI NETWORK" 228 "ZF" 229 "Garmin" 233 "Yacht Monitoring Solutions" 235 "Sailormade Marine Telemetry/Tetra Technology" 243 "Eride" 257 "Honda Motor" 272 "Groco" 273 "Actisense" 274 "Amphenol LTW Technology" 275 "Navico" 283 "Hamilton Jet" 285 "Sea Recovery" 286 "Coelmo SRL Italy" 295 "BEP Marine" 304 "Empir Bus" 305 "NovAtel" 306 "Sleipner Motor" 307 "MBW Technologies" 315 "ICOM" 328 "Qwerty" 329 "Dief" 341 "Boening Automationstechnologie" 345 "Korean Maritime University" 351 "Thrane and Thrane" 355 "Mastervolt" 356 "Fischer Panda Generators" 358 "Victron Energy" 370 "Rolls Royce Marine" 373 "Electronic Design" 374 "Northern Lights" 378 "Glendinning" 381 "B & G" 384 "Rose Point Navigation Systems" 385 "Johnson Outdoors Marine Electronics Inc Geonav" 394 "Capi 2" 396 "Beyond Measure" 400 "Livorsi Marine" 404 "ComNav" 409 "Chetco" 419 "Fusion Electronics" 421 "Standard Horizon" 422 "True Heading" 426 "Egersund Marine Electronics" 427 "em-trak Marine Electronics" 431 "Tohatsu Co, JP" 437 "Digital Yacht" 438 "Comar Systems Limited" 440 "Cummins" 443 "VDO (aka Continental-Corporation)" 451 "Parker Hannifin aka Village Marine Tech" 459 "Alltek Marine Electronics" 460 "SAN GIORGIO S.E.I.N" 466 "Veethree Electronics & Marine" 470 "SI-TEX Marine Electronics" 471 "Sea Cross Marine" 475 "GME aka Standard Communications" 476 "Humminbird Marine Electronics" 478 "Ocean Sat" 481 "Chetco Digital Instruments" 493 "Watcheye" 499 "Lcj Capteurs" 502 "Attwood Marine" 503 "Naviop S.R.L." 504 "Vesper Marine" 510 "Marinesoft" 513 "Simarine" 517 "NoLand Engineering" 518 "Transas USA" 529 "National Instruments Korea" 530 "National Marine Electronics Association" 532 "Onwa Marine" 540 "Webasto" 571 "Marinecraft (South Korea)" 573 "McMurdo Group aka Orolia" 578 "Advansea" 579 "KVH" 580 "San Jose Technology" 583 "Yacht Control" 586 "Suzuki Motor" 591 "US Coast Guard" 595 "Ship Module aka Customware" 600 "Aquatic AV" 605 "Aventics" 606 "Intellian" 612 "SamwonIT" 614 "Arlt Tecnologies" 637 "Bavaria Yachts" 641 "Diverse Yacht Services" 644 "Wema U.S.A dba KUS" 658 "Shenzhen Jiuzhou Himunication" 688 "Rockford" 699 "Harman International" 704 "JL Audio" 708 "Lars Thrane" 715 "Autonnic" 717 "Yacht Devices" 734 "REAP Systems" 735 "AEM Performance Electronics" 739 "LxNav" 741 "Littelfuse, Inc (formerly Carling Technologies)" 743 "DaeMyung" 744 "Woosung" 748 "ISOTTA IFRA srl" 773 "Clarion US" 776 "HMI Systems" 777 "Ocean Signal" 778 "Seakeeper" 781 "Poly Planar" 785 "Fischer Panda DE" 795 "Broyda Industries" 796 "Canadian Automotive" 797 "Tides Marine" 798 "Lumishore" 799 "Still Water Designs and Audio" 802 "BJ Technologies (Beneteau)" 803 "Gill Sensors" 811 "Blue Water Desalination" 815 "FLIR" 824 "Undheim Systems" 826 "Lewmar" 838 "TeamSurv" 844 "Fell Marine" 847 "Oceanvolt" 862 "Prospec" 868 "Data Panel" 890 "L3 Technologies" 894 "Rhodan Marine Systems" 896 "Nexfour Solutions" 905 "ASA Electronics" 909 "Marines Co (South Korea)" 911 "Nautic-on" 917 "Sentinel" 929 "JL Marine Systems" 930 "Ecotronix" 944 "Zontisa Marine" 951 "EXOR International" 962 "Timbolier Industries" 963 "TJC Micro" 968 "Cox Powertrain" 969 "Blue Seas" 981 "Kobelt Manufacturing" 992 "Blue Ocean IOT" 997 "Xenta Systems" 999 "Signal K" 1004 "Ultraflex" 1008 "Lintest SmartBoat" 1011 "Soundmax" 1020 "Team Italia Marine (Onyx Marine Automation s.r.l)" 1021 "Entratech" 1022 "ITC" 1029 "The Marine Guardian" 1047 "Sonic" 1051 "ProNav" 1053 "Vetus Maxwell INC." 1056 "Lithium Pros" 1059 "Boatrax" 1062 "Marol Co ltd" 1065 "CALYPSO Instruments" 1066 "Spot Zero Water" 1069 "Lithionics Battery" 1070 "Quick-teck Electronics" 1075 "Uniden America" 1083 "Nauticoncept" 1084 "Shadow-Caster LED lighting" 1085 "Wet Sounds" 1088 "E-T-A Circuit Breakers" 1092 "Scheiber" 1100 "Smart Yachts International Limited" 1109 "Dockmate" 1114 "Bobs Machine" 1118 "L3Harris ASV" 1119 "Balmar" 1120 "Elettromedia" 1127 "Electromaax" 1140 "Across Oceans Systems" 1145 "Kiwi Yachting" 1150 "BSB Artificial Intelligence" 1151 "Orca Technologies" 1154 "TBS Electronics" 1158 "Technoton Electroics" 1160 "MG Energy Systems" 1169 "Sea Machine Robotics" 1171 "Vista Manufacturing" 1183 "Zipwake" 1186 "Sailmon" 1192 "Airmoniq Pro Kft" 1194 "Sierra Marine" 1200 "Xinuo Information Technology (Xiamen)" 1218 "Septentrio" 1233 "NKE Marine Electronics" 1238 "SuperTrack Aps" 1239 "Honda Electronics" 1245 "Raritan Engineering" 1249 "Integrated Power Solutions AG" 1260 "Interactive Technologies" 1283 "LTG-Tech" 1299 "Energy Solutions (UK)" 1300 "WATT Fuel Cell" 1302 "Pro Mainer" 1305 "Dragonfly Energy" 1306 "Koden Electronics" 1311 "Humphree" 1316 "Hinkley Yachts" 1317 "Global Marine Management GmbH (GMM)" 1320 "Triskel Marine" 1330 "Warwick Control Technologies" 1331 "Dolphin Charger" 1337 "Barnacle Systems" 1348 "Radian IoT" 1353 "Ocean LED Marine" 1359 "BluNav" 1361 "OVA (Nantong Saiyang Electronics Co., Ltd)" 1368 "RAD Propulsion" 1369 "Electric Yacht" 1372 "Elco Motor Yachts" 1384 "Tecnoseal Foundry S.r.l" 1385 "Pro Charging Systems" 1389 "EVEX" 1398 "Gobius Sensor Technology" 1403 "Arco Marine" 1408 "Lenco Marine" 1413 "Naocontrol" 1417 "Revatek" 1438 "Aeolionics" 1439 "PredictWind" 1440 "Egis Mobile Electric" 1445 "Starboard Yacht Group" 1446 "Roswell Marine" 1451 "ePropulsion (Guangdong ePropulsion Technology Ltd.)" 1452 "Micro-Air" 1453 "Vital Battery" 1458 "Ride Controller" 1460 "Tocaro Blue" 1461 "Vanquish Yachts" 1471 "FT Technologies" 1478 "Alps Alpine" 1481 "E-Force Marine" 1482 "CMC Marine" 1483 "Nanjing Sandemarine Information Technology" 1850 "Teleflex Marine (SeaStar Solutions)" 1851 "Raymarine" 1852 "Navionics" 1853 "Japan Radio" 1854 "Northstar Technologies" 1855 "Furuno" 1856 "Trimble" 1857 "Simrad" 1858 "Litton" 1859 "Kvasar" 1860 "MMP" 1861 "Vector Cantech" 1862 "Yamaha Marine" 1863 "Faria Instruments" ;
VAL_ 2583652608 Industry_Code 0 "Global" 1 "Highway" 2 "Agriculture" 3 "Construction" 4 "Marine Industry" 5 "Industrial" ;
VAL_ 2583657216 Manufacturer_Code 69 "ARKS Enterprises" 78 "FW Murphy/Enovation Controls" 80 "Twin Disc" 85 "Kohler Power Systems" 88 "Hemisphere GPS" 135 "Airmar" 137 "Maretron" 140 "Lowrance" 144 "Mercury Marine" 147 "Nautibus Electronic" 148 "Blue Water Data" 154 "Westerbeke" 157 "ISSPRO" 161 "Offshore Systems (UK)" 163 "Evinrude/BRP" 165 "CPAC Systems" 168 "Xantrex Technology" 169 "Marlin Technologies" 172 "Yanmar Marine" 174 "Volvo Penta" 176 "Carling Technologies Inc. (Moritz Aerospace)" 185 "Beede Instruments" 192 "Floscan Instrument" 193 "Nobeltec" 198 "Mystic Valley Communications" 199 "Actia" 201 "Disenos Y Technologia" 211 "Digital Switching Systems" 215 "Xintex/Atena" 224 "EMMI NETWORK" 228 "ZF" 229 "Garmin" 233 "Yacht Monitoring Solutions" 235 "Sailormade Marine Telemetry/Tetra Technology" 243 "Eride" 257 "Honda Motor" 272 "Groco" 273 "Actisense" 274 "Amphenol LTW Technology" 275 "Navico" 283 "Hamilton Jet" 285 "Sea Recovery" 286 "Coelmo SRL Italy" 295 "BEP Marine" 304 "Empir Bus" 305 "NovAtel" 306 "Sleipner Motor" 307 "MBW Technologies" 315 "ICOM" 328 "Qwerty" 329 "Dief" 341 "Boening Automationstechnologie" 345 "Korean Maritime University" 351 "Thrane and Thrane" 355 "Mastervolt" 356 "Fischer Panda Generators" 358 "Victron Energy" 370 "Rolls Royce Marine" 373 "Electronic Design" 374 "Northern Lights" 378 "Glendinning" 381 "B & G" 384 "Rose Point Navigation Systems" 385 "Johnson Outdoors Marine Electronics Inc Geonav" 394 "Capi 2" 396 "Beyond Measure" 400 "Livorsi Marine" 404 "ComNav" 409 "Chetco" 419 "Fusion Electronics" 421 "Standard Horizon" 422 "True Heading" 426 "Egersund Marine Electronics" 427 "em-trak Marine Electronics" 431 "Tohatsu Co, JP" 437 "Digital Yacht" 438 "Comar Systems Limited" 440 "Cummins" 443 "VDO (aka Continental-Corporation)" 451 "Parker Hannifin aka Village Marine Tech" 459 "Alltek Marine Electronics" 460 "SAN GIORGIO S.E.I.N" 466 "Veethree Electronics & Marine" 470 "SI-TEX Marine Electronics" 471 "Sea Cross Marine" 475 "GME aka Standard Communications" 476 "Humminbird Marine Electronics" 478 "Ocean Sat" 481 "Chetco Digital Instruments" 493 "Watcheye" 499 "Lcj Capteurs" 502 "Attwood Marine" 503 "Naviop S.R.L." 504 "Vesper Marine" 510 "Marinesoft" 513 "Simarine" 517 "NoLand Engineering" 518 "Transas USA" 529 "National Instruments Korea" 530 "National Marine Electronics Association" 532 "Onwa Marine" 540 "Webasto" 571 "Marinecraft (South Korea)" 573 "McMurdo Group aka Orolia" 578 "Advansea" 579 "KVH" 580 "San Jose Technology" 583 "Yacht Control" 586 "Suzuki Motor" 591 "US Coast Guard" 595 "Ship Module aka Customware" 600 "Aquatic AV" 605 "Aventics" 606 "Intellian" 612 "SamwonIT" 614 "Arlt Tecnologies" 637 "Bavaria Yachts" 641 "Diverse Yacht Services" 644 "Wema U.S.A dba KUS" 658 "Shenzhen Jiuzhou Himunication" 688 "Rockford" 699 "Harman International" 704 "JL Audio" 708 "Lars Thrane" 715 "Autonnic" 717 "Yacht Devices" 734 "REAP Systems" 735 "AEM Performance Electronics" 739 "LxNav" 741 "Littelfuse, Inc (formerly Carling Technologies)" 743 "DaeMyung" 744 "Woosung" 748 "ISOTTA IFRA srl" 773 "Clarion US" 776 "HMI Systems" 777 "Ocean Signal" 778 "Seakeeper" 781 "Poly Planar" 785 "Fischer Panda DE" 795 "Broyda Industries" 796 "Canadian Automotive" 797 "Tides Marine" 798 "Lumishore" 799 "Still Water Designs and Audio" 802 "BJ Technologies (Beneteau)" 803 "Gill Sensors" 811 "Blue Water Desalination" 815 "FLIR" 824 "Undheim Systems" 826 "Lewmar" 838 "TeamSurv" 844 "Fell Marine" 847 "Oceanvolt" 862 "Prospec" 868 "Data Panel" 890 "L3 Technologies" 894 "Rhodan Marine Systems" 896 "Nexfour Solutions" 905 "ASA Electronics" 909 "Marines Co (South Korea)" 911 "Nautic-on" 917 "Sentinel" 929 "JL Marine Systems" 930 "Ecotronix" 944 "Zontisa Marine" 951 "EXOR International" 962 "Timbolier Industries" 963 "TJC Micro" 968 "Cox Powertrain" 969 "Blue Seas" 981 "Kobelt Manufacturing" 992 "Blue Ocean IOT" 997 "Xenta Systems" 999 "Signal K" 1004 "Ultraflex" 1008 "Lintest SmartBoat" 1011 "Soundmax" 1020 "Team Italia Marine (Onyx Marine Automation s.r.l)" 1021 "Entratech" 1022 "ITC" 1029 "The Marine Guardian" 1047 "Sonic" 1051 "ProNav" 1053 "Vetus Maxwell INC." 1056 "Lithium Pros" 1059 "Boatrax" 1062 "Marol Co ltd" 1065 "CALYPSO Instruments" 1066 "Spot Zero Water" 1069 "Lithionics Battery" 1070 "Quick-teck Electronics" 1075 "Uniden America" 1083 "Nauticoncept" 1084 "Shadow-Caster LED lighting" 1085 "Wet Sounds" 1088 "E-T-A Circuit Breakers" 1092 "Scheiber" 1100 "Smart Yachts International Limited" 1109 "Dockmate" 1114 "Bobs Machine" 1118 "L3Harris ASV" 1119 "Balmar" 1120 "Elettromedia" 1127 "Electromaax" 1140 "Across Oceans Systems" 1145 "Kiwi Yachting" 1150 "BSB Artificial Intelligence" 1151 "Orca Technologies" 1154 "TBS Electronics" 1158 "Technoton Electroics" 1160 "MG Energy Systems" 1169 "Sea Machine Robotics" 1171 "Vista Manufacturing" 1183 "Zipwake" 1186 "Sailmon" 1192 "Airmoniq Pro Kft" 1194 "Sierra Marine" 1200 "Xinuo Information Technology (Xiamen)" 1218 "Septentrio" 1233 "NKE Marine Electronics" 1238 "SuperTrack Aps" 1239 "Honda Electronics" 1245 "Raritan Engineering" 1249 "Integrated Power Solutions AG" 1260 "Interactive Technologies" 1283 "LTG-Tech" 1299 "Energy Solutions (UK)" 1300 "WATT Fuel Cell" 1302 "Pro Mainer" 1305 "Dragonfly Energy" 1306 "Koden Electronics" 1311 "Humphree" 1316 "Hinkley Yachts" 1317 "Global Marine Management GmbH (GMM)" 1320 "Triskel Marine" 1330 "Warwick Control Technologies" 1331 "Dolphin Charger" 1337 "Barnacle Systems" 1348 "Radian IoT" 1353 "Ocean LED Marine" 1359 "BluNav" 1361 "OVA (Nantong Saiyang Electronics Co., Ltd)" 1368 "RAD Propulsion" 1369 "Electric Yacht" 1372 "Elco Motor Yachts" 1384 "Tecnoseal Foundry S.r.l" 1385 "Pro Charging Systems" 1389 "EVEX" 1398 "Gobius Sensor Technology" 1403 "Arco Marine" 1408 "Lenco Marine" 1413 "Naocontrol" 1417 "Revatek" 1438 "Aeolionics" 1439 "PredictWind" 1440 "Egis Mobile Electric" 1445 "Starboard Yacht Group" 1446 "Roswell Marine" 1451 "ePropulsion (Guangdong ePropulsion Technology Ltd.)" 1452 "Micro-Air" 1453 "Vital Battery" 1458 "Ride Controller" 1460 "Tocaro Blue" 1461 "Vanquish Yachts" 1471 "FT Technologies" 1478 "Alps Alpine" 1481 "E-Force Marine" 1482 "CMC Marine" 1483 "Nanjing Sandemarine Information Technology" 1850 "Teleflex Marine (SeaStar Solutions)" 1851 "Raymarine" 1852 "Navionics" 1853 "Japan Radio" 1854 "Northstar Technologies" 1855 "Furuno" 1856 "Trimble" 1857 "Simrad" 1858 "Litton" 1859 "Kvasar" 1860 "MMP" 1861 "Vector Cantech" 1862 "Yamaha Marine" 1863 "Faria Instruments" ;
VAL_ 2583657216 Industry_Code 0 "Global" 1 "Highway" 2 "Agriculture" 3 "Construction" 4 "Marine Industry" 5 "Industrial" ;
VAL_ 2650767360 Manufacturer_Code 69 "ARKS Enterprises" 78 "FW Murphy/Enovation Controls" 80 "Twin Disc" 85 "Kohler Power Systems" 88 "Hemisphere GPS" 135 "Airmar" 137 "Maretron" 140 "Lowrance" 144 "Mercury Marine" 147 "Nautibus Electronic" 148 "Blue Water Data" 154 "Westerbeke" 157 "ISSPRO" 161 "Offshore Systems (UK)" 163 "Evinrude/BRP" 165 "CPAC Systems" 168 "Xantrex Technology" 169 "Marlin Technologies" 172 "Yanmar Marine" 174 "Volvo Penta" 176 "Carling Technologies Inc. (Moritz Aerospace)" 185 "Beede Instruments" 192 "Floscan Instrument" 193 "Nobeltec" 198 "Mystic Valley Communications" 199 "Actia" 201 "Disenos Y Technologia" 211 "Digital Switching Systems" 215 "Xintex/Atena" 224 "EMMI NETWORK" 228 "ZF" 229 "Garmin" 233 "Yacht Monitoring Solutions" 235 "Sailormade Marine Telemetry/Tetra Technology" 243 "Eride" 257 "Honda Motor" 272 "Groco" 273 "Actisense" 274 "Amphenol LTW Technology" 275 "Navico" 283 "Hamilton Jet" 285 "Sea Recovery" 286 "Coelmo SRL Italy" 295 "BEP Marine" 304 "Empir Bus" 305 "NovAtel" 306 "Sleipner Motor" 307 "MBW Technologies" 315 "ICOM" 328 "Qwerty" 329 "Dief" 341 "Boening Automationstechnologie" 345 "Korean Maritime University" 351 "Thrane and Thrane" 355 "Mastervolt" 356 "Fischer Panda Generators" 358 "Victron Energy" 370 "Rolls Royce Marine" 373 "Electronic Design" 374 "Northern Lights" 378 "Glendinning" 381 "B & G" 384 "Rose Point Navigation Systems" 385 "Johnson Outdoors Marine Electronics Inc Geonav" 394 "Capi 2" 396 "Beyond Measure" 400 "Livorsi Marine" 404 "ComNav" 409 "Chetco" 419 "Fusion Electronics" 421 "Standard Horizon" 422 "True Heading" 426 "Egersund Marine Electronics" 427 "em-trak Marine Electronics" 431 "Tohatsu Co, JP" 437 "Digital Yacht" 438 "Comar Systems Limited" 440 "Cummins" 443 "VDO (aka Continental-Corporation)" 451 "Parker Hannifin aka Village Marine Tech" 459 "Alltek Marine Electronics" 460 "SAN GIORGIO S.E.I.N" 466 "Veethree Electronics & Marine" 470 "SI-TEX Marine Electronics" 471 "Sea Cross Marine" 475 "GME aka Standard Communications" 476 "Humminbird Marine Electronics" 478 "Ocean Sat" 481 "Chetco Digital Instruments" 493 "Watcheye" 499 "Lcj Capteurs" 502 "Attwood Marine" 503 "Naviop S.R.L." 504 "Vesper Marine" 510 "Marinesoft" 513 "Simarine" 517 "NoLand Engineering" 518 "Transas USA" 529 "National Instruments Korea" 530 "National Marine Electronics Association" 532 "Onwa Marine" 540 "Webasto" 571 "Marinecraft (South Korea)" 573 "McMurdo Group aka Orolia" 578 "Advansea" 579 "KVH" 580 "San Jose Technology" 583 "Yacht Control" 586 "Suzuki Motor" 591 "US Coast Guard" 595 "Ship Module aka Customware" 600 "Aquatic AV" 605 "Aventics" 606 "Intellian" 612 "SamwonIT" 614 "Arlt Tecnologies" 637 "Bavaria Yachts" 641 "Diverse Yacht Services" 644 "Wema U.S.A dba KUS" 658 "Shenzhen Jiuzhou Himunication" 688 "Rockford" 699 "Harman International" 704 "JL Audio" 708 "Lars Thrane" 715 "Autonnic" 717 "Yacht Devices" 734 "REAP Systems" 735 "AEM Performance Electronics" 739 "LxNav" 741 "Littelfuse, Inc (formerly Carling Technologies)" 743 "DaeMyung" 744 "Woosung" 748 "ISOTTA IFRA srl" 773 "Clarion US" 776 "HMI Systems" 777 "Ocean Signal" 778 "Seakeeper" 781 "Poly Planar" 785 "Fischer Panda DE" 795 "Broyda Industries" 796 "Canadian Automotive" 797 "Tides Marine" 798 "Lumishore" 799 "Still Water Designs and Audio" 802 "BJ Technologies (Beneteau)" 803 "Gill Sensors" 811 "Blue Water Desalination" 815 "FLIR" 824 "Undheim Systems" 826 "Lewmar" 838 "TeamSurv" 844 "Fell Marine" 847 "Oceanvolt" 862 "Prospec" 868 "Data Panel" 890 "L3 Technologies" 894 "Rhodan Marine Systems" 896 "Nexfour Solutions" 905 "ASA Electronics" 909 "Marines Co (South Korea)" 911 "Nautic-on" 917 "Sentinel" 929 "JL Marine Systems" 930 "Ecotronix" 944 "Zontisa Marine" 951 "EXOR International" 962 "Timbolier Industries" 963 "TJC Micro" 968 "Cox Powertrain" 969 "Blue Seas" 981 "Kobelt Manufacturing" 992 "Blue Ocean IOT" 997 "Xenta Systems" 999 "Signal K" 1004 "Ultraflex" 1008 "Lintest SmartBoat" 1011 "Soundmax" 1020 "Team Italia Marine (Onyx Marine Automation s.r.l)" 1021 "Entratech" 1022 "ITC" 1029 "The Marine Guardian" 1047 "Sonic" 1051 "ProNav" 1053 "Vetus Maxwell INC." 1056 "Lithium Pros" 1059 "Boatrax" 1062 "Marol Co ltd" 1065 "CALYPSO Instruments" 1066 "Spot Zero Water" 1069 "Lithionics Battery" 1070 "Quick-teck Electronics" 1075 "Uniden America" 1083 "Nauticoncept" 1084 "Shadow-Caster LED lighting" 1085 "Wet Sounds" 1088 "E-T-A Circuit Breakers" 1092 "Scheiber" 1100 "Smart Yachts International Limited" 1109 "Dockmate" 1114 "Bobs Machine" 1118 "L3Harris ASV" 1119 "Balmar" 1120 "Elettromedia" 1127 "Electromaax" 1140 "Across Oceans Systems" 1145 "Kiwi Yachting" 1150 "BSB Artificial Intelligence" 1151 "Orca Technologies" 1154 "TBS Electronics" 1158 "Technoton Electroics" 1160 "MG Energy Systems" 1169 "Sea Machine Robotics" 1171 "Vista Manufacturing" 1183 "Zipwake" 1186 "Sailmon" 1192 "Airmoniq Pro Kft" 1194 "Sierra Marine" 1200 "Xinuo Information Technology (Xiamen)" 1218 "Septentrio" 1233 "NKE Marine Electronics" 1238 "SuperTrack Aps" 1239 "Honda Electronics" 1245 "Raritan Engineering" 1249 "Integrated Power Solutions AG" 1260 "Interactive Technologies" 1283 "LTG-Tech" 1299 "Energy Solutions (UK)" 1300 "WATT Fuel Cell" 1302 "Pro Mainer" 1305 "Dragonfly Energy" 1306 "Koden Electronics" 1311 "Humphree" 1316 "Hinkley Yachts" 1317 "Global Marine Management GmbH (GMM)" 1320 "Triskel Marine" 1330 "Warwick Control Technologies" 1331 "Dolphin Charger" 1337 "Barnacle Systems" 1348 "Radian IoT" 1353 "Ocean LED Marine" 1359 "BluNav" 1361 "OVA (Nantong Saiyang Electronics Co., Ltd)" 1368 "RAD Propulsion" 1369 "Electric Yacht" 1372 "Elco Motor Yachts" 1384 "Tecnoseal Foundry S.r.l" 1385 "Pro Charging Systems" 1389 "EVEX" 1398 "Gobius Sensor Technology" 1403 "Arco Marine" 1408 "Lenco Marine" 1413 "Naocontrol" 1417 "Revatek" 1438 "Aeolionics" 1439 "PredictWind" 1440 "Egis Mobile Electric" 1445 "Starboard Yacht Group" 1446 "Roswell Marine" 1451 "ePropulsion (Guangdong ePropulsion Technology Ltd.)" 1452 "Micro-Air" 1453 "Vital Battery" 1458 "Ride Controller" 1460 "Tocaro Blue" 1461 "Vanquish Yachts" 1471 "FT Technologies" 1478 "Alps Alpine" 1481 "E-Force Marine" 1482 "CMC Marine" 1483 "Nanjing Sandemarine Information Technology" 1850 "Teleflex Marine (SeaStar Solutions)" 1851 "Raymarine" 1852 "Navionics" 1853 "Japan Radio" 1854 "Northstar Technologies" 1855 "Furuno" 1856 "Trimble" 1857 "Simrad" 1858 "Litton" 1859 "Kvasar" 1860 "MMP" 1861 "Vector Cantech" 1862 "Yamaha Marine" 1863 "Faria Instruments" ;
VAL_ 2650767360 Industry_Code 0 "Global" 1 "Highway" 2 "Agriculture" 3 "Construction" 4 "Marine Industry" 5 "Industrial" ;
VAL_ 2650767360 Control 0 "Report previous values" 1 "Generate new values" ;
VAL_ 2650767360 Test_ID 1 "Format Code" 2 "Factory EEPROM" 3 "User EEPROM" 4 "Water Temperature Sensor" 5 "Sonar Transceiver" 6 "Speed sensor" 7 "Internal temperature sensor" 8 "Battery voltage sensor" ;
VAL_ 2583658752 Manufacturer_Code 69 "ARKS Enterprises" 78 "FW Murphy/Enovation Controls" 80 "Twin Disc" 85 "Kohler Power Systems" 88 "Hemisphere GPS" 135 "Airmar" 137 "Maretron" 140 "Lowrance" 144 "Mercury Marine" 147 "Nautibus Electronic" 148 "Blue Water Data" 154 "Westerbeke" 157 "ISSPRO" 161 "Offshore Systems (UK)" 163 "Evinrude/BRP" 165 "CPAC Systems" 168 "Xantrex Technology" 169 "Marlin Technologies" 172 "Yanmar Marine" 174 "Volvo Penta" 176 "Carling Technologies Inc. (Moritz Aerospace)" 185 "Beede Instruments" 192 "Floscan Instrument" 193 "Nobeltec" 198 "Mystic Valley Communications" 199 "Actia" 201 "Disenos Y Technologia" 211 "Digital Switching Systems" 215 "Xintex/Atena" 224 "EMMI NETWORK" 228 "ZF" 229 "Garmin" 233 "Yacht Monitoring Solutions" 235 "Sailormade Marine Telemetry/Tetra Technology" 243 "Eride" 257 "Honda Motor" 272 "Groco" 273 "Actisense" 274 "Amphenol LTW Technology" 275 "Navico" 283 "Hamilton Jet" 285 "Sea Recovery" 286 "Coelmo SRL Italy" 295 "BEP Marine" 304 "Empir Bus" 305 "NovAtel" 306 "Sleipner Motor" 307 "MBW Technologies" 315 "ICOM" 328 "Qwerty" 329 "Dief" 341 "Boening Automationstechnologie" 345 "Korean Maritime University" 351 "Thrane and Thrane" 355 "Mastervolt" 356 "Fischer Panda Generators" 358 "Victron Energy" 370 "Rolls Royce Marine" 373 "Electronic Design" 374 "Northern Lights" 378 "Glendinning" 381 "B & G" 384 "Rose Point Navigation Systems" 385 "Johnson Outdoors Marine Electronics Inc Geonav" 394 "Capi 2" 396 "Beyond Measure" 400 "Livorsi Marine" 404 "ComNav" 409 "Chetco" 419 "Fusion Electronics" 421 "Standard Horizon" 422 "True Heading" 426 "Egersund Marine Electronics" 427 "em-trak Marine Electronics" 431 "Tohatsu Co, JP" 437 "Digital Yacht" 438 "Comar Systems Limited" 440 "Cummins" 443 "VDO (aka Continental-Corporation)" 451 "Parker Hannifin aka Village Marine Tech" 459 "Alltek Marine Electronics" 460 "SAN GIORGIO S.E.I.N" 466 "Veethree Electronics & Marine" 470 "SI-TEX Marine Electronics" 471 "Sea Cross Marine" 475 "GME aka Standard Communications" 476 "Humminbird Marine Electronics" 478 "Ocean Sat" 481 "Chetco Digital Instruments" 493 "Watcheye" 499 "Lcj Capteurs" 502 "Attwood Marine" 503 "Naviop S.R.L." 504 "Vesper Marine" 510 "Marinesoft" 513 "Simarine" 517 "NoLand Engineering" 518 "Transas USA" 529 "National Instruments Korea" 530 "National Marine Electronics Association" 532 "Onwa Marine" 540 "Webasto" 571 "Marinecraft (South Korea)" 573 "McMurdo Group aka Orolia" 578 "Advansea" 579 "KVH" 580 "San Jose Technology" 583 "Yacht Control" 586 "Suzuki Motor" 591 "US Coast Guard" 595 "Ship Module aka Customware" 600 "Aquatic AV" 605 "Aventics" 606 "Intellian" 612 "SamwonIT" 614 "Arlt Tecnologies" 637 "Bavaria Yachts" 641 "Diverse Yacht Services" 644 "Wema U.S.A dba KUS" 658 "Shenzhen Jiuzhou Himunication" 688 "Rockford" 699 "Harman International" 704 "JL Audio" 708 "Lars Thrane" 715 "Autonnic" 717 "Yacht Devices" 734 "REAP Systems" 735 "AEM Performance Electronics" 739 "LxNav" 741 "Littelfuse, Inc (formerly Carling Technologies)" 743 "DaeMyung" 744 "Woosung" 748 "ISOTTA IFRA srl" 773 "Clarion US" 776 "HMI Systems" 777 "Ocean Signal" 778 "Seakeeper" 781 "Poly Planar" 785 "Fischer Panda DE" 795 "Broyda Industries" 796 "Canadian Automotive" 797 "Tides Marine" 798 "Lumishore" 799 "Still Water Designs and Audio" 802 "BJ Technologies (Beneteau)" 803 "Gill Sensors" 811 "Blue Water Desalination" 815 "FLIR" 824 "Undheim Systems" 826 "Lewmar" 838 "TeamSurv" 844 "Fell Marine" 847 "Oceanvolt" 862 "Prospec" 868 "Data Panel" 890 "L3 Technologies" 894 "Rhodan Marine Systems" 896 "Nexfour Solutions" 905 "ASA Electronics" 909 "Marines Co (South Korea)" 911 "Nautic-on" 917 "Sentinel" 929 "JL Marine Systems" 930 "Ecotronix" 944 "Zontisa Marine" 951 "EXOR International" 962 "Timbolier Industries" 963 "TJC Micro" 968 "Cox Powertrain" 969 "Blue Seas" 981 "Kobelt Manufacturing" 992 "Blue Ocean IOT" 997 "Xenta Systems" 999 "Signal K" 1004 "Ultraflex" 1008 "Lintest SmartBoat" 1011 "Soundmax" 1020 "Team Italia Marine (Onyx Marine Automation s.r.l)" 1021 "Entratech" 1022 "ITC" 1029 "The Marine Guardian" 1047 "Sonic" 1051 "ProNav" 1053 "Vetus Maxwell INC." 1056 "Lithium Pros" 1059 "Boatrax" 1062 "Marol Co ltd" 1065 "CALYPSO Instruments" 1066 "Spot Zero Water" 1069 "Lithionics Battery" 1070 "Quick-teck Electronics" 1075 "Uniden America" 1083 "Nauticoncept" 1084 "Shadow-Caster LED lighting" 1085 "Wet Sounds" 1088 "E-T-A Circuit Breakers" 1092 "Scheiber" 1100 "Smart Yachts International Limited" 1109 "Dockmate" 1114 "Bobs Machine" 1118 "L3Harris ASV" 1119 "Balmar" 1120 "Elettromedia" 1127 "Electromaax" 1140 "Across Oceans Systems" 1145 "Kiwi Yachting" 1150 "BSB Artificial Intelligence" 1151 "Orca Technologies" 1154 "TBS Electronics" 1158 "Technoton Electroics" 1160 "MG Energy Systems" 1169 "Sea Machine Robotics" 1171 "Vista Manufacturing" 1183 "Zipwake" 1186 "Sailmon" 1192 "Airmoniq Pro Kft" 1194 "Sierra Marine" 1200 "Xinuo Information Technology (Xiamen)" 1218 "Septentrio" 1233 "NKE Marine Electronics" 1238 "SuperTrack Aps" 1239 "Honda Electronics" 1245 "Raritan Engineering" 1249 "Integrated Power Solutions AG" 1260 "Interactive Technologies" 1283 "LTG-Tech" 1299 "Energy Solutions (UK)" 1300 "WATT Fuel Cell" 1302 "Pro Mainer" 1305 "Dragonfly Energy" 1306 "Koden Electronics" 1311 "Humphree" 1316 "Hinkley Yachts" 1317 "Global Marine Management GmbH (GMM)" 1320 "Triskel Marine" 1330 "Warwick Control Technologies" 1331 "Dolphin Charger" 1337 "Barnacle Systems" 1348 "Radian IoT" 1353 "Ocean LED Marine" 1359 "BluNav" 1361 "OVA (Nantong Saiyang Electronics Co., Ltd)" 1368 "RAD Propulsion" 1369 "Electric Yacht" 1372 "Elco Motor Yachts" 1384 "Tecnoseal Foundry S.r.l" 1385 "Pro Charging Systems" 1389 "EVEX" 1398 "Gobius Sensor Technology" 1403 "Arco Marine" 1408 "Lenco Marine" 1413 "Naocontrol" 1417 "Revatek" 1438 "Aeolionics" 1439 "PredictWind" 1440 "Egis Mobile Electric" 1445 "Starboard Yacht Group" 1446 "Roswell Marine" 1451 "ePropulsion (Guangdong ePropulsion Technology Ltd.)" 1452 "Micro-Air" 1453 "Vital Battery" 1458 "Ride Controller" 1460 "Tocaro Blue" 1461 "Vanquish Yachts" 1471 "FT Technologies" 1478 "Alps Alpine" 1481 "E-Force Marine" 1482 "CMC Marine" 1483 "Nanjing Sandemarine Information Technology" 1850 "Teleflex Marine (SeaStar Solutions)" 1851 "Raymarine" 1852 "Navionics" 1853 "Japan Radio" 1854 "Northstar Technologies" 1855 "Furuno" 1856 "Trimble" 1857 "Simrad" 1858 "Litton" 1859 "Kvasar" 1860 "MMP" 1861 "Vector Cantech" 1862 "Yamaha Marine" 1863 "Faria Instruments" ;
VAL_ 2583658752 Industry_Code 0 "Global" 1 "Highway" 2 "Agriculture" 3 "Construction" 4 "Marine Industry" 5 "Industrial" ;
VAL_ 2583659008 Manufacturer_Code 69 "ARKS Enterprises" 78 "FW Murphy/Enovation Controls" 80 "Twin Disc" 85 "Kohler Power Systems" 88 "Hemisphere GPS" 135 "Airmar" 137 "Maretron" 140 "Lowrance" 144 "Mercury Marine" 147 "Nautibus Electronic" 148 "Blue Water Data" 154 "Westerbeke" 157 "ISSPRO" 161 "Offshore Systems (UK)" 163 "Evinrude/BRP" 165 "CPAC Systems" 168 "Xantrex Technology" 169 "Marlin Technologies" 172 "Yanmar Marine" 174 "Volvo Penta" 176 "Carling Technologies Inc. (Moritz Aerospace)" 185 "Beede Instruments" 192 "Floscan Instrument" 193 "Nobeltec" 198 "Mystic Valley Communications" 199 "Actia" 201 "Disenos Y Technologia" 211 "Digital Switching Systems" 215 "Xintex/Atena" 224 "EMMI NETWORK" 228 "ZF" 229 "Garmin" 233 "Yacht Monitoring Solutions" 235 "Sailormade Marine Telemetry/Tetra Technology" 243 "Eride" 257 "Honda Motor" 272 "Groco" 273 "Actisense" 274 "Amphenol LTW Technology" 275 "Navico" 283 "Hamilton Jet" 285 "Sea Recovery" 286 "Coelmo SRL Italy" 295 "BEP Marine" 304 "Empir Bus" 305 "NovAtel" 306 "Sleipner Motor" 307 "MBW Technologies" 315 "ICOM" 328 "Qwerty" 329 "Dief" 341 "Boening Automationstechnologie" 345 "Korean Maritime University" 351 "Thrane and Thrane" 355 "Mastervolt" 356 "Fischer Panda Generators" 358 "Victron Energy" 370 "Rolls Royce Marine" 373 "Electronic Design" 374 "Northern Lights" 378 "Glendinning" 381 "B & G" 384 "Rose Point Navigation Systems" 385 "Johnson Outdoors Marine Electronics Inc Geonav" 394 "Capi 2" 396 "Beyond Measure" 400 "Livorsi Marine" 404 "ComNav" 409 "Chetco" 419 "Fusion Electronics" 421 "Standard Horizon" 422 "True Heading" 426 "Egersund Marine Electronics" 427 "em-trak Marine Electronics" 431 "Tohatsu Co, JP" 437 "Digital Yacht" 438 "Comar Systems Limited" 440 "Cummins" 443 "VDO (aka Continental-Corporation)" 451 "Parker Hannifin aka Village Marine Tech" 459 "Alltek Marine Electronics" 460 "SAN GIORGIO S.E.I.N" 466 "Veethree Electronics & Marine" 470 "SI-TEX Marine Electronics" 471 "Sea Cross Marine" 475 "GME aka Standard Communications" 476 "Humminbird Marine Electronics" 478 "Ocean Sat" 481 "Chetco Digital Instruments" 493 "Watcheye" 499 "Lcj Capteurs" 502 "Attwood Marine" 503 "Naviop S.R.L." 504 "Vesper Marine" 510 "Marinesoft" 513 "Simarine" 517 "NoLand Engineering" 518 "Transas USA" 529 "National Instruments Korea" 530 "National Marine Electronics Association" 532 "Onwa Marine" 540 "Webasto" 571 "Marinecraft (South Korea)" 573 "McMurdo Group aka Orolia" 578 "Advansea" 579 "KVH" 580 "San Jose Technology" 583 "Yacht Control" 586 "Suzuki Motor" 591 "US Coast Guard" 595 "Ship Module aka Customware" 600 "Aquatic AV" 605 "Aventics" 606 "Intellian" 612 "SamwonIT" 614 "Arlt Tecnologies" 637 "Bavaria Yachts" 641 "Diverse Yacht Services" 644 "Wema U.S.A dba KUS" 658 "Shenzhen Jiuzhou Himunication" 688 "Rockford" 699 "Harman International" 704 "JL Audio" 708 "Lars Thrane" 715 "Autonnic" 717 "Yacht Devices" 734 "REAP Systems" 735 "AEM Performance Electronics" 739 "LxNav" 741 "Littelfuse, Inc (formerly Carling Technologies)" 743 "DaeMyung" 744 "Woosung" 748 "ISOTTA IFRA srl" 773 "Clarion US" 776 "HMI Systems" 777 "Ocean Signal" 778 "Seakeeper" 781 "Poly Planar" 785 "Fischer Panda DE" 795 "Broyda Industries" 796 "Canadian Automotive" 797 "Tides Marine" 798 "Lumishore" 799 "Still Water Designs and Audio" 802 "BJ Technologies (Beneteau)" 803 "Gill Sensors" 811 "Blue Water Desalination" 815 "FLIR" 824 "Undheim Systems" 826 "Lewmar" 838 "TeamSurv" 844 "Fell Marine" 847 "Oceanvolt" 862 "Prospec" 868 "Data Panel" 890 "L3 Technologies" 894 "Rhodan Marine Systems" 896 "Nexfour Solutions" 905 "ASA Electronics" 909 "Marines Co (South Korea)" 911 "Nautic-on" 917 "Sentinel" 929 "JL Marine Systems" 930 "Ecotronix" 944 "Zontisa Marine" 951 "EXOR International" 962 "Timbolier Industries" 963 "TJC Micro" 968 "Cox Powertrain" 969 "Blue Seas" 981 "Kobelt Manufacturing" 992 "Blue Ocean IOT" 997 "Xenta Systems" 999 "Signal K" 1004 "Ultraflex" 1008 "Lintest SmartBoat" 1011 "Soundmax" 1020 "Team Italia Marine (Onyx Marine Automation s.r.l)" 1021 "Entratech" 1022 "ITC" 1029 "The Marine Guardian" 1047 "Sonic" 1051 "ProNav" 1053 "Vetus Maxwell INC." 1056 "Lithium Pros" 1059 "Boatrax" 1062 "Marol Co ltd" 1065 "CALYPSO Instruments" 1066 "Spot Zero Water" 1069 "Lithionics Battery" 1070 "Quick-teck Electronics" 1075 "Uniden America" 1083 "Nauticoncept" 1084 "Shadow-Caster LED lighting" 1085 "Wet Sounds" 1088 "E-T-A Circuit Breakers" 1092 "Scheiber" 1100 "Smart Yachts International Limited" 1109 "Dockmate" 1114 "Bobs Machine" 1118 "L3Harris ASV" 1119 "Balmar" 1120 "Elettromedia" 1127 "Electromaax" 1140 "Across Oceans Systems" 1145 "Kiwi Yachting" 1150 "BSB Artificial Intelligence" 1151 "Orca Technologies" 1154 "TBS Electronics" 1158 "Technoton Electroics" 1160 "MG Energy Systems" 1169 "Sea Machine Robotics" 1171 "Vista Manufacturing" 1183 "Zipwake" 1186 "Sailmon" 1192 "Airmoniq Pro Kft" 1194 "Sierra Marine" 1200 "Xinuo Information Technology (Xiamen)" 1218 "Septentrio" 1233 "NKE Marine Electronics" 1238 "SuperTrack Aps" 1239 "Honda Electronics" 1245 "Raritan Engineering" 1249 "Integrated Power Solutions AG" 1260 "Interactive Technologies" 1283 "LTG-Tech" 1299 "Energy Solutions (UK)" 1300 "WATT Fuel Cell" 1302 "Pro Mainer" 1305 "Dragonfly Energy" 1306 "Koden Electronics" 1311 "Humphree" 1316 "Hinkley Yachts" 1317 "Global Marine Management GmbH (GMM)" 1320 "Triskel Marine" 1330 "Warwick Control Technologies" 1331 "Dolphin Charger" 1337 "Barnacle Systems" 1348 "Radian IoT" 1353 "Ocean LED Marine" 1359 "BluNav" 1361 "OVA (Nantong Saiyang Electronics Co., Ltd)" 1368 "RAD Propulsion" 1369 "Electric Yacht" 1372 "Elco Motor Yachts" 1384 "Tecnoseal Foundry S.r.l" 1385 "Pro Charging Systems" 1389 "EVEX" 1398 "Gobius Sensor Technology" 1403 "Arco Marine" 1408 "Lenco Marine" 1413 "Naocontrol" 1417 "Revatek" 1438 "Aeolionics" 1439 "PredictWind" 1440 "Egis Mobile Electric" 1445 "Starboard Yacht Group" 1446 "Roswell Marine" 1451 "ePropulsion (Guangdong ePropulsion Technology Ltd.)" 1452 "Micro-Air" 1453 "Vital Battery" 1458 "Ride Controller" 1460 "Tocaro Blue" 1461 "Vanquish Yachts" 1471 "FT Technologies" 1478 "Alps Alpine" 1481 "E-Force Marine" 1482 "CMC Marine" 1483 "Nanjing Sandemarine Information Technology" 1850 "Teleflex Marine (SeaStar Solutions)" 1851 "Raymarine" 1852 "Navionics" 1853 "Japan Radio" 1854 "Northstar Technologies" 1855 "Furuno" 1856 "Trimble" 1857 "Simrad" 1858 "Litton" 1859 "Kvasar" 1860 "MMP" 1861 "Vector Cantech" 1862 "Yamaha Marine" 1863 "Faria Instruments" ;
VAL_ 2583659008 Industry_Code 0 "Global" 1 "Highway" 2 "Agriculture" 3 "Construction" 4 "Marine Industry" 5 "Industrial" ;
VAL_ 2583659264 Manufacturer_Code 69 "ARKS Enterprises" 78 "FW Murphy/Enovation Controls" 80 "Twin Disc" 85 "Kohler Power Systems" 88 "Hemisphere GPS" 135 "Airmar" 137 "Maretron" 140 "Lowrance" 144 "Mercury Marine" 147 "Nautibus Electronic" 148 "Blue Water Data" 154 "Westerbeke" 157 "ISSPRO" 161 "Offshore Systems (UK)" 163 "Evinrude/BRP" 165 "CPAC Systems" 168 "Xantrex Technology" 169 "Marlin Technologies" 172 "Yanmar Marine" 174 "Volvo Penta" 176 "Carling Technologies Inc. (Moritz Aerospace)" 185 "Beede Instruments" 192 "Floscan Instrument" 193 "Nobeltec" 198 "Mystic Valley Communications" 199 "Actia" 201 "Disenos Y Technologia" 211 "Digital Switching Systems" 215 "Xintex/Atena" 224 "EMMI NETWORK" 228 "ZF" 229 "Garmin" 233 "Yacht Monitoring Solutions" 235 "Sailormade Marine Telemetry/Tetra Technology" 243 "Eride" 257 "Honda Motor" 272 "Groco" 273 "Actisense" 274 "Amphenol LTW Technology" 275 "Navico" 283 "Hamilton Jet" 285 "Sea Recovery" 286 "Coelmo SRL Italy" 295 "BEP Marine" 304 "Empir Bus" 305 "NovAtel" 306 "Sleipner Motor" 307 "MBW Technologies" 315 "ICOM" 328 "Qwerty" 329 "Dief" 341 "Boening Automationstechnologie" 345 "Korean Maritime University" 351 "Thrane and Thrane" 355 "Mastervolt" 356 "Fischer Panda Generators" 358 "Victron Energy" 370 "Rolls Royce Marine" 373 "Electronic Design" 374 "Northern Lights" 378 "Glendinning" 381 "B & G" 384 "Rose Point Navigation Systems" 385 "Johnson Outdoors Marine Electronics Inc Geonav" 394 "Capi 2" 396 "Beyond Measure" 400 "Livorsi Marine" 404 "ComNav" 409 "Chetco" 419 "Fusion Electronics" 421 "Standard Horizon" 422 "True Heading" 426 "Egersund Marine Electronics" 427 "em-trak Marine Electronics" 431 "Tohatsu Co, JP" 437 "Digital Yacht" 438 "Comar Systems Limited" 440 "Cummins" 443 "VDO (aka Continental-Corporation)" 451 "Parker Hannifin aka Village Marine Tech" 459 "Alltek Marine Electronics" 460 "SAN GIORGIO S.E.I.N" 466 "Veethree Electronics & Marine" 470 "SI-TEX Marine Electronics" 471 "Sea Cross Marine" 475 "GME aka Standard Communications" 476 "Humminbird Marine Electronics" 478 "Ocean Sat" 481 "Chetco Digital Instruments" 493 "Watcheye" 499 "Lcj Capteurs" 502 "Attwood Marine" 503 "Naviop S.R.L." 504 "Vesper Marine" 510 "Marinesoft" 513 "Simarine" 517 "NoLand Engineering" 518 "Transas USA" 529 "National Instruments Korea" 530 "National Marine Electronics Association" 532 "Onwa Marine" 540 "Webasto" 571 "Marinecraft (South Korea)" 573 "McMurdo Group aka Orolia" 578 "Advansea" 579 "KVH" 580 "San Jose Technology" 583 "Yacht Control" 586 "Suzuki Motor" 591 "US Coast Guard" 595 "Ship Module aka Customware" 600 "Aquatic AV" 605 "Aventics" 606 "Intellian" 612 "SamwonIT" 614 "Arlt Tecnologies" 637 "Bavaria Yachts" 641 "Diverse Yacht Services" 644 "Wema U.S.A dba KUS" 658 "Shenzhen Jiuzhou Himunication" 688 "Rockford" 699 "Harman International" 704 "JL Audio" 708 "Lars Thrane" 715 "Autonnic" 717 "Yacht Devices" 734 "REAP Systems" 735 "AEM Performance Electronics" 739 "LxNav" 741 "Littelfuse, Inc (formerly Carling Technologies)" 743 "DaeMyung" 744 "Woosung" 748 "ISOTTA IFRA srl" 773 "Clarion US" 776 "HMI Systems" 777 "Ocean Signal" 778 "Seakeeper" 781 "Poly Planar" 785 "Fischer Panda DE" 795 "Broyda Industries" 796 "Canadian Automotive" 797 "Tides Marine" 798 "Lumishore" 799 "Still Water Designs and Audio" 802 "BJ Technologies (Beneteau)" 803 "Gill Sensors" 811 "Blue Water Desalination" 815 "FLIR" 824 "Undheim Systems" 826 "Lewmar" 838 "TeamSurv" 844 "Fell Marine" 847 "Oceanvolt" 862 "Prospec" 868 "Data Panel" 890 "L3 Technologies" 894 "Rhodan Marine Systems" 896 "Nexfour Solutions" 905 "ASA Electronics" 909 "Marines Co (South Korea)" 911 "Nautic-on" 917 "Sentinel" 929 "JL Marine Systems" 930 "Ecotronix" 944 "Zontisa Marine" 951 "EXOR International" 962 "Timbolier Industries" 963 "TJC Micro" 968 "Cox Powertrain" 969 "Blue Seas" 981 "Kobelt Manufacturing" 992 "Blue Ocean IOT" 997 "Xenta Systems" 999 "Signal K" 1004 "Ultraflex" 1008 "Lintest SmartBoat" 1011 "Soundmax" 1020 "Team Italia Marine (Onyx Marine Automation s.r.l)" 1021 "Entratech" 1022 "ITC" 1029 "The Marine Guardian" 1047 "Sonic" 1051 "ProNav" 1053 "Vetus Maxwell INC." 1056 "Lithium Pros" 1059 "Boatrax" 1062 "Marol Co ltd" 1065 "CALYPSO Instruments" 1066 "Spot Zero Water" 1069 "Lithionics Battery" 1070 "Quick-teck Electronics" 1075 "Uniden America" 1083 "Nauticoncept" 1084 "Shadow-Caster LED lighting" 1085 "Wet Sounds" 1088 "E-T-A Circuit Breakers" 1092 "Scheiber" 1100 "Smart Yachts International Limited" 1109 "Dockmate" 1114 "Bobs Machine" 1118 "L3Harris ASV" 1119 "Balmar" 1120 "Elettromedia" 1127 "Electromaax" 1140 "Across Oceans Systems" 1145 "Kiwi Yachting" 1150 "BSB Artificial Intelligence" 1151 "Orca Technologies" 1154 "TBS Electronics" 1158 "Technoton Electroics" 1160 "MG Energy Systems" 1169 "Sea Machine Robotics" 1171 "Vista Manufacturing" 1183 "Zipwake" 1186 "Sailmon" 1192 "Airmoniq Pro Kft" 1194 "Sierra Marine" 1200 "Xinuo Information Technology (Xiamen)" 1218 "Septentrio" 1233 "NKE Marine Electronics" 1238 "SuperTrack Aps" 1239 "Honda Electronics" 1245 "Raritan Engineering" 1249 "Integrated Power Solutions AG" 1260 "Interactive Technologies" 1283 "LTG-Tech" 1299 "Energy Solutions (UK)" 1300 "WATT Fuel Cell" 1302 "Pro Mainer" 1305 "Dragonfly Energy" 1306 "Koden Electronics" 1311 "Humphree" 1316 "Hinkley Yachts" 1317 "Global Marine Management GmbH (GMM)" 1320 "Triskel Marine" 1330 "Warwick Control Technologies" 1331 "Dolphin Charger" 1337 "Barnacle Systems" 1348 "Radian IoT" 1353 "Ocean LED Marine" 1359 "BluNav" 1361 "OVA (Nantong Saiyang Electronics Co., Ltd)" 1368 "RAD Propulsion" 1369 "Electric Yacht" 1372 "Elco Motor Yachts" 1384 "Tecnoseal Foundry S.r.l" 1385 "Pro Charging Systems" 1389 "EVEX" 1398 "Gobius Sensor Technology" 1403 "Arco Marine" 1408 "Lenco Marine" 1413 "Naocontrol" 1417 "Revatek" 1438 "Aeolionics" 1439 "PredictWind" 1440 "Egis Mobile Electric" 1445 "Starboard Yacht Group" 1446 "Roswell Marine" 1451 "ePropulsion (Guangdong ePropulsion Technology Ltd.)" 1452 "Micro-Air" 1453 "Vital Battery" 1458 "Ride Controller" 1460 "Tocaro Blue" 1461 "Vanquish Yachts" 1471 "FT Technologies" 1478 "Alps Alpine" 1481 "E-Force Marine" 1482 "CMC Marine" 1483 "Nanjing Sandemarine Information Technology" 1850 "Teleflex Marine (SeaStar Solutions)" 1851 "Raymarine" 1852 "Navionics" 1853 "Japan Radio" 1854 "Northstar Technologies" 1855 "Furuno" 1856 "Trimble" 1857 "Simrad" 1858 "Litton" 1859 "Kvasar" 1860 "MMP" 1861 "Vector Cantech" 1862 "Yamaha Marine" 1863 "Faria Instruments" ;
VAL_ 2583659264 Industry_Code 0 "Global" 1 "Highway" 2 "Agriculture" 3 "Construction" 4 "Marine Industry" 5 "Industrial" ;
VAL_ 2583660288 Manufacturer_Code 69 "ARKS Enterprises" 78 "FW Murphy/Enovation Controls" 80 "Twin Disc" 85 "Kohler Power Systems" 88 "Hemisphere GPS" 135 "Airmar" 137 "Maretron" 140 "Lowrance" 144 "Mercury Marine" 147 "Nautibus Electronic" 148 "Blue Water Data" 154 "Westerbeke" 157 "ISSPRO" 161 "Offshore Systems (UK)" 163 "Evinrude/BRP" 165 "CPAC Systems" 168 "Xantrex Technology" 169 "Marlin Technologies" 172 "Yanmar Marine" 174 "Volvo Penta" 176 "Carling Technologies Inc. (Moritz Aerospace)" 185 "Beede Instruments" 192 "Floscan Instrument" 193 "Nobeltec" 198 "Mystic Valley Communications" 199 "Actia" 201 "Disenos Y Technologia" 211 "Digital Switching Systems" 215 "Xintex/Atena" 224 "EMMI NETWORK" 228 "ZF" 229 "Garmin" 233 "Yacht Monitoring Solutions" 235 "Sailormade Marine Telemetry/Tetra Technology" 243 "Eride" 257 "Honda Motor" 272 "Groco" 273 "Actisense" 274 "Amphenol LTW Technology" 275 "Navico" 283 "Hamilton Jet" 285 "Sea Recovery" 286 "Coelmo SRL Italy" 295 "BEP Marine" 304 "Empir Bus" 305 "NovAtel" 306 "Sleipner Motor" 307 "MBW Technologies" 315 "ICOM" 328 "Qwerty" 329 "Dief" 341 "Boening Automationstechnologie" 345 "Korean Maritime University" 351 "Thrane and Thrane" 355 "Mastervolt" 356 "Fischer Panda Generators" 358 "Victron Energy" 370 "Rolls Royce Marine" 373 "Electronic Design" 374 "Northern Lights" 378 "Glendinning" 381 "B & G" 384 "Rose Point Navigation Systems" 385 "Johnson Outdoors Marine Electronics Inc Geonav" 394 "Capi 2" 396 "Beyond Measure" 400 "Livorsi Marine" 404 "ComNav" 409 "Chetco" 419 "Fusion Electronics" 421 "Standard Horizon" 422 "True Heading" 426 "Egersund Marine Electronics" 427 "em-trak Marine Electronics" 431 "Tohatsu Co, JP" 437 "Digital Yacht" 438 "Comar Systems Limited" 440 "Cummins" 443 "VDO (aka Continental-Corporation)" 451 "Parker Hannifin aka Village Marine Tech" 459 "Alltek Marine Electronics" 460 "SAN GIORGIO S.E.I.N" 466 "Veethree Electronics & Marine" 470 "SI-TEX Marine Electronics" 471 "Sea Cross Marine" 475 "GME aka Standard Communications" 476 "Humminbird Marine Electronics" 478 "Ocean Sat" 481 "Chetco Digital Instruments" 493 "Watcheye" 499 "Lcj Capteurs" 502 "Attwood Marine" 503 "Naviop S.R.L." 504 "Vesper Marine" 510 "Marinesoft" 513 "Simarine" 517 "NoLand Engineering" 518 "Transas USA" 529 "National Instruments Korea" 530 "National Marine Electronics Association" 532 "Onwa Marine" 540 "Webasto" 571 "Marinecraft (South Korea)" 573 "McMurdo Group aka Orolia" 578 "Advansea" 579 "KVH" 580 "San Jose Technology" 583 "Yacht Control" 586 "Suzuki Motor" 591 "US Coast Guard" 595 "Ship Module aka Customware" 600 "Aquatic AV" 605 "Aventics" 606 "Intellian" 612 "SamwonIT" 614 "Arlt Tecnologies" 637 "Bavaria Yachts" 641 "Diverse Yacht Services" 644 "Wema U.S.A dba KUS" 658 "Shenzhen Jiuzhou Himunication" 688 "Rockford" 699 "Harman International" 704 "JL Audio" 708 "Lars Thrane" 715 "Autonnic" 717 "Yacht Devices" 734 "REAP Systems" 735 "AEM Performance Electronics" 739 "LxNav" 741 "Littelfuse, Inc (formerly Carling Technologies)" 743 "DaeMyung" 744 "Woosung" 748 "ISOTTA IFRA srl" 773 "Clarion US" 776 "HMI Systems" 777 "Ocean Signal" 778 "Seakeeper" 781 "Poly Planar" 785 "Fischer Panda DE" 795 "Broyda Industries" 796 "Canadian Automotive" 797 "Tides Marine" 798 "Lumishore" 799 "Still Water Designs and Audio" 802 "BJ Technologies (Beneteau)" 803 "Gill Sensors" 811 "Blue Water Desalination" 815 "FLIR" 824 "Undheim Systems" 826 "Lewmar" 838 "TeamSurv" 844 "Fell Marine" 847 "Oceanvolt" 862 "Prospec" 868 "Data Panel" 890 "L3 Technologies" 894 "Rhodan Marine Systems" 896 "Nexfour Solutions" 905 "ASA Electronics" 909 "Marines Co (South Korea)" 911 "Nautic-on" 917 "Sentinel" 929 "JL Marine Systems" 930 "Ecotronix" 944 "Zontisa Marine" 951 "EXOR International" 962 "Timbolier Industries" 963 "TJC Micro" 968 "Cox Powertrain" 969 "Blue Seas" 981 "Kobelt Manufacturing" 992 "Blue Ocean IOT" 997 "Xenta Systems" 999 "Signal K" 1004 "Ultraflex" 1008 "Lintest SmartBoat" 1011 "Soundmax" 1020 "Team Italia Marine (Onyx Marine Automation s.r.l)" 1021 "Entratech" 1022 "ITC" 1029 "The Marine Guardian" 1047 "Sonic" 1051 "ProNav" 1053 "Vetus Maxwell INC." 1056 "Lithium Pros" 1059 "Boatrax" 1062 "Marol Co ltd" 1065 "CALYPSO Instruments" 1066 "Spot Zero Water" 1069 "Lithionics Battery" 1070 "Quick-teck Electronics" 1075 "Uniden America" 1083 "Nauticoncept" 1084 "Shadow-Caster LED lighting" 1085 "Wet Sounds" 1088 "E-T-A Circuit Breakers" 1092 "Scheiber" 1100 "Smart Yachts International Limited" 1109 "Dockmate" 1114 "Bobs Machine" 1118 "L3Harris ASV" 1119 "Balmar" 1120 "Elettromedia" 1127 "Electromaax" 1140 "Across Oceans Systems" 1145 "Kiwi Yachting" 1150 "BSB Artificial Intelligence" 1151 "Orca Technologies" 1154 "TBS Electronics" 1158 "Technoton Electroics" 1160 "MG Energy Systems" 1169 "Sea Machine Robotics" 1171 "Vista Manufacturing" 1183 "Zipwake" 1186 "Sailmon" 1192 "Airmoniq Pro Kft" 1194 "Sierra Marine" 1200 "Xinuo Information Technology (Xiamen)" 1218 "Septentrio" 1233 "NKE Marine Electronics" 1238 "SuperTrack Aps" 1239 "Honda Electronics" 1245 "Raritan Engineering" 1249 "Integrated Power Solutions AG" 1260 "Interactive Technologies" 1283 "LTG-Tech" 1299 "Energy Solutions (UK)" 1300 "WATT Fuel Cell" 1302 "Pro Mainer" 1305 "Dragonfly Energy" 1306 "Koden Electronics" 1311 "Humphree" 1316 "Hinkley Yachts" 1317 "Global Marine Management GmbH (GMM)" 1320 "Triskel Marine" 1330 "Warwick Control Technologies" 1331 "Dolphin Charger" 1337 "Barnacle Systems" 1348 "Radian IoT" 1353 "Ocean LED Marine" 1359 "BluNav" 1361 "OVA (Nantong Saiyang Electronics Co., Ltd)" 1368 "RAD Propulsion" 1369 "Electric Yacht" 1372 "Elco Motor Yachts" 1384 "Tecnoseal Foundry S.r.l" 1385 "Pro Charging Systems" 1389 "EVEX" 1398 "Gobius Sensor Technology" 1403 "Arco Marine" 1408 "Lenco Marine" 1413 "Naocontrol" 1417 "Revatek" 1438 "Aeolionics" 1439 "PredictWind" 1440 "Egis Mobile Electric" 1445 "Starboard Yacht Group" 1446 "Roswell Marine" 1451 "ePropulsion (Guangdong ePropulsion Technology Ltd.)" 1452 "Micro-Air" 1453 "Vital Battery" 1458 "Ride Controller" 1460 "Tocaro Blue" 1461 "Vanquish Yachts" 1471 "FT Technologies" 1478 "Alps Alpine" 1481 "E-Force Marine" 1482 "CMC Marine" 1483 "Nanjing Sandemarine Information Technology" 1850 "Teleflex Marine (SeaStar Solutions)" 1851 "Raymarine" 1852 "Navionics" 1853 "Japan Radio" 1854 "Northstar Technologies" 1855 "Furuno" 1856 "Trimble" 1857 "Simrad" 1858 "Litton" 1859 "Kvasar" 1860 "MMP" 1861 "Vector Cantech" 1862 "Yamaha Marine" 1863 "Faria Instruments" ;
VAL_ 2583660288 Industry_Code 0 "Global" 1 "Highway" 2 "Agriculture" 3 "Construction" 4 "Marine Industry" 5 "Industrial" ;
VAL_ 2583674880 Manufacturer_Code 69 "ARKS Enterprises" 78 "FW Murphy/Enovation Controls" 80 "Twin Disc" 85 "Kohler Power Systems" 88 "Hemisphere GPS" 135 "Airmar" 137 "Maretron" 140 "Lowrance" 144 "Mercury Marine" 147 "Nautibus Electronic" 148 "Blue Water Data" 154 "Westerbeke" 157 "ISSPRO" 161 "Offshore Systems (UK)" 163 "Evinrude/BRP" 165 "CPAC Systems" 168 "Xantrex Technology" 169 "Marlin Technologies" 172 "Yanmar Marine" 174 "Volvo Penta" 176 "Carling Technologies Inc. (Moritz Aerospace)" 185 "Beede Instruments" 192 "Floscan Instrument" 193 "Nobeltec" 198 "Mystic Valley Communications" 199 "Actia" 201 "Disenos Y Technologia" 211 "Digital Switching Systems" 215 "Xintex/Atena" 224 "EMMI NETWORK" 228 "ZF" 229 "Garmin" 233 "Yacht Monitoring Solutions" 235 "Sailormade Marine Telemetry/Tetra Technology" 243 "Eride" 257 "Honda Motor" 272 "Groco" 273 "Actisense" 274 "Amphenol LTW Technology" 275 "Navico" 283 "Hamilton Jet" 285 "Sea Recovery" 286 "Coelmo SRL Italy" 295 "BEP Marine" 304 "Empir Bus" 305 "NovAtel" 306 "Sleipner Motor" 307 "MBW Technologies" 315 "ICOM" 328 "Qwerty" 329 "Dief" 341 "Boening Automationstechnologie" 345 "Korean Maritime University" 351 "Thrane and Thrane" 355 "Mastervolt" 356 "Fischer Panda Generators" 358 "Victron Energy" 370 "Rolls Royce Marine" 373 "Electronic Design" 374 "Northern Lights" 378 "Glendinning" 381 "B & G" 384 "Rose Point Navigation Systems" 385 "Johnson Outdoors Marine Electronics Inc Geonav" 394 "Capi 2" 396 "Beyond Measure" 400 "Livorsi Marine" 404 "ComNav" 409 "Chetco" 419 "Fusion Electronics" 421 "Standard Horizon" 422 "True Heading" 426 "Egersund Marine Electronics" 427 "em-trak Marine Electronics" 431 "Tohatsu Co, JP" 437 "Digital Yacht" 438 "Comar Systems Limited" 440 "Cummins" 443 "VDO (aka Continental-Corporation)" 451 "Parker Hannifin aka Village Marine Tech" 459 "Alltek Marine Electronics" 460 "SAN GIORGIO S.E.I.N" 466 "Veethree Electronics & Marine" 470 "SI-TEX Marine Electronics" 471 "Sea Cross Marine" 475 "GME aka Standard Communications" 476 "Humminbird Marine Electronics" 478 "Ocean Sat" 481 "Chetco Digital Instruments" 493 "Watcheye" 499 "Lcj Capteurs" 502 "Attwood Marine" 503 "Naviop S.R.L." 504 "Vesper Marine" 510 "Marinesoft" 513 "Simarine" 517 "NoLand Engineering" 518 "Transas USA" 529 "National Instruments Korea" 530 "National Marine Electronics Association" 532 "Onwa Marine" 540 "Webasto" 571 "Marinecraft (South Korea)" 573 "McMurdo Group aka Orolia" 578 "Advansea" 579 "KVH" 580 "San Jose Technology" 583 "Yacht Control" 586 "Suzuki Motor" 591 "US Coast Guard" 595 "Ship Module aka Customware" 600 "Aquatic AV" 605 "Aventics" 606 "Intellian" 612 "SamwonIT" 614 "Arlt Tecnologies" 637 "Bavaria Yachts" 641 "Diverse Yacht Services" 644 "Wema U.S.A dba KUS" 658 "Shenzhen Jiuzhou Himunication" 688 "Rockford" 699 "Harman International" 704 "JL Audio" 708 "Lars Thrane" 715 "Autonnic" 717 "Yacht Devices" 734 "REAP Systems" 735 "AEM Performance Electronics" 739 "LxNav" 741 "Littelfuse, Inc (formerly Carling Technologies)" 743 "DaeMyung" 744 "Woosung" 748 "ISOTTA IFRA srl" 773 "Clarion US" 776 "HMI Systems" 777 "Ocean Signal" 778 "Seakeeper" 781 "Poly Planar" 785 "Fischer Panda DE" 795 "Broyda Industries" 796 "Canadian Automotive" 797 "Tides Marine" 798 "Lumishore" 799 "Still Water Designs and Audio" 802 "BJ Technologies (Beneteau)" 803 "Gill Sensors" 811 "Blue Water Desalination" 815 "FLIR" 824 "Undheim Systems" 826 "Lewmar" 838 "TeamSurv" 844 "Fell Marine" 847 "Oceanvolt" 862 "Prospec" 868 "Data Panel" 890 "L3 Technologies" 894 "Rhodan Marine Systems" 896 "Nexfour Solutions" 905 "ASA Electronics" 909 "Marines Co (South Korea)" 911 "Nautic-on" 917 "Sentinel" 929 "JL Marine Systems" 930 "Ecotronix" 944 "Zontisa Marine" 951 "EXOR International" 962 "Timbolier Industries" 963 "TJC Micro" 968 "Cox Powertrain" 969 "Blue Seas" 981 "Kobelt Manufacturing" 992 "Blue Ocean IOT" 997 "Xenta Systems" 999 "Signal K" 1004 "Ultraflex" 1008 "Lintest SmartBoat" 1011 "Soundmax" 1020 "Team Italia Marine (Onyx Marine Automation s.r.l)" 1021 "Entratech" 1022 "ITC" 1029 "The Marine Guardian" 1047 "Sonic" 1051 "ProNav" 1053 "Vetus Maxwell INC." 1056 "Lithium Pros" 1059 "Boatrax" 1062 "Marol Co ltd" 1065 "CALYPSO Instruments" 1066 "Spot Zero Water" 1069 "Lithionics Battery" 1070 "Quick-teck Electronics" 1075 "Uniden America" 1083 "Nauticoncept" 1084 "Shadow-Caster LED lighting" 1085 "Wet Sounds" 1088 "E-T-A Circuit Breakers" 1092 "Scheiber" 1100 "Smart Yachts International Limited" 1109 "Dockmate" 1114 "Bobs Machine" 1118 "L3Harris ASV" 1119 "Balmar" 1120 "Elettromedia" 1127 "Electromaax" 1140 "Across Oceans Systems" 1145 "Kiwi Yachting" 1150 "BSB Artificial Intelligence" 1151 "Orca Technologies" 1154 "TBS Electronics" 1158 "Technoton Electroics" 1160 "MG Energy Systems" 1169 "Sea Machine Robotics" 1171 "Vista Manufacturing" 1183 "Zipwake" 1186 "Sailmon" 1192 "Airmoniq Pro Kft" 1194 "Sierra Marine" 1200 "Xinuo Information Technology (Xiamen)" 1218 "Septentrio" 1233 "NKE Marine Electronics" 1238 "SuperTrack Aps" 1239 "Honda Electronics" 1245 "Raritan Engineering" 1249 "Integrated Power Solutions AG" 1260 "Interactive Technologies" 1283 "LTG-Tech" 1299 "Energy Solutions (UK)" 1300 "WATT Fuel Cell" 1302 "Pro Mainer" 1305 "Dragonfly Energy" 1306 "Koden Electronics" 1311 "Humphree" 1316 "Hinkley Yachts" 1317 "Global Marine Management GmbH (GMM)" 1320 "Triskel Marine" 1330 "Warwick Control Technologies" 1331 "Dolphin Charger" 1337 "Barnacle Systems" 1348 "Radian IoT" 1353 "Ocean LED Marine" 1359 "BluNav" 1361 "OVA (Nantong Saiyang Electronics Co., Ltd)" 1368 "RAD Propulsion" 1369 "Electric Yacht" 1372 "Elco Motor Yachts" 1384 "Tecnoseal Foundry S.r.l" 1385 "Pro Charging Systems" 1389 "EVEX" 1398 "Gobius Sensor Technology" 1403 "Arco Marine" 1408 "Lenco Marine" 1413 "Naocontrol" 1417 "Revatek" 1438 "Aeolionics" 1439 "PredictWind" 1440 "Egis Mobile Electric" 1445 "Starboard Yacht Group" 1446 "Roswell Marine" 1451 "ePropulsion (Guangdong ePropulsion Technology Ltd.)" 1452 "Micro-Air" 1453 "Vital Battery" 1458 "Ride Controller" 1460 "Tocaro Blue" 1461 "Vanquish Yachts" 1471 "FT Technologies" 1478 "Alps Alpine" 1481 "E-Force Marine" 1482 "CMC Marine" 1483 "Nanjing Sandemarine Information Technology" 1850 "Teleflex Marine (SeaStar Solutions)" 1851 "Raymarine" 1852 "Navionics" 1853 "Japan Radio" 1854 "Northstar Technologies" 1855 "Furuno" 1856 "Trimble" 1857 "Simrad" 1858 "Litton" 1859 "Kvasar" 1860 "MMP" 1861 "Vector Cantech" 1862 "Yamaha Marine" 1863 "Faria Instruments" ;
VAL_ 2583674880 Industry_Code 0 "Global" 1 "Highway" 2 "Agriculture" 3 "Construction" 4 "Marine Industry" 5 "Industrial" ;
VAL_ 2583675648 Manufacturer_Code 69 "ARKS Enterprises" 78 "FW Murphy/Enovation Controls" 80 "Twin Disc" 85 "Kohler Power Systems" 88 "Hemisphere GPS" 135 "Airmar" 137 "Maretron" 140 "Lowrance" 144 "Mercury Marine" 147 "Nautibus Electronic" 148 "Blue Water Data" 154 "Westerbeke" 157 "ISSPRO" 161 "Offshore Systems (UK)" 163 "Evinrude/BRP" 165 "CPAC Systems" 168 "Xantrex Technology" 169 "Marlin Technologies" 172 "Yanmar Marine" 174 "Volvo Penta" 176 "Carling Technologies Inc. (Moritz Aerospace)" 185 "Beede Instruments" 192 "Floscan Instrument" 193 "Nobeltec" 198 "Mystic Valley Communications" 199 "Actia" 201 "Disenos Y Technologia" 211 "Digital Switching Systems" 215 "Xintex/Atena" 224 "EMMI NETWORK" 228 "ZF" 229 "Garmin" 233 "Yacht Monitoring Solutions" 235 "Sailormade Marine Telemetry/Tetra Technology" 243 "Eride" 257 "Honda Motor" 272 "Groco" 273 "Actisense" 274 "Amphenol LTW Technology" 275 "Navico" 283 "Hamilton Jet" 285 "Sea Recovery" 286 "Coelmo SRL Italy" 295 "BEP Marine" 304 "Empir Bus" 305 "NovAtel" 306 "Sleipner Motor" 307 "MBW Technologies" 315 "ICOM" 328 "Qwerty" 329 "Dief" 341 "Boening Automationstechnologie" 345 "Korean Maritime University" 351 "Thrane and Thrane" 355 "Mastervolt" 356 "Fischer Panda Generators" 358 "Victron Energy" 370 "Rolls Royce Marine" 373 "Electronic Design" 374 "Northern Lights" 378 "Glendinning" 381 "B & G" 384 "Rose Point Navigation Systems" 385 "Johnson Outdoors Marine Electronics Inc Geonav" 394 "Capi 2" 396 "Beyond Measure" 400 "Livorsi Marine" 404 "ComNav" 409 "Chetco" 419 "Fusion Electronics" 421 "Standard Horizon" 422 "True Heading" 426 "Egersund Marine Electronics" 427 "em-trak Marine Electronics" 431 "Tohatsu Co, JP" 437 "Digital Yacht" 438 "Comar Systems Limited" 440 "Cummins" 443 "VDO (aka Continental-Corporation)" 451 "Parker Hannifin aka Village Marine Tech" 459 "Alltek Marine Electronics" 460 "SAN GIORGIO S.E.I.N" 466 "Veethree Electronics & Marine" 470 "SI-TEX Marine Electronics" 471 "Sea Cross Marine" 475 "GME aka Standard Communications" 476 "Humminbird Marine Electronics" 478 "Ocean Sat" 481 "Chetco Digital Instruments" 493 "Watcheye" 499 "Lcj Capteurs" 502 "Attwood Marine" 503 "Naviop S.R.L." 504 "Vesper Marine" 510 "Marinesoft" 513 "Simarine" 517 "NoLand Engineering" 518 "Transas USA" 529 "National Instruments Korea" 530 "National Marine Electronics Association" 532 "Onwa Marine" 540 "Webasto" 571 "Marinecraft (South Korea)" 573 "McMurdo Group aka Orolia" 578 "Advansea" 579 "KVH" 580 "San Jose Technology" 583 "Yacht Control" 586 "Suzuki Motor" 591 "US Coast Guard" 595 "Ship Module aka Customware" 600 "Aquatic AV" 605 "Aventics" 606 "Intellian" 612 "SamwonIT" 614 "Arlt Tecnologies" 637 "Bavaria Yachts" 641 "Diverse Yacht Services" 644 "Wema U.S.A dba KUS" 658 "Shenzhen Jiuzhou Himunication" 688 "Rockford" 699 "Harman International" 704 "JL Audio" 708 "Lars Thrane" 715 "Autonnic" 717 "Yacht Devices" 734 "REAP Systems" 735 "AEM Performance Electronics" 739 "LxNav" 741 "Littelfuse, Inc (formerly Carling Technologies)" 743 "DaeMyung" 744 "Woosung" 748 "ISOTTA IFRA srl" 773 "Clarion US" 776 "HMI Systems" 777 "Ocean Signal" 778 "Seakeeper" 781 "Poly Planar" 785 "Fischer Panda DE" 795 "Broyda Industries" 796 "Canadian Automotive" 797 "Tides Marine" 798 "Lumishore" 799 "Still Water Designs and Audio" 802 "BJ Technologies (Beneteau)" 803 "Gill Sensors" 811 "Blue Water Desalination" 815 "FLIR" 824 "Undheim Systems" 826 "Lewmar" 838 "TeamSurv" 844 "Fell Marine" 847 "Oceanvolt" 862 "Prospec" 868 "Data Panel" 890 "L3 Technologies" 894 "Rhodan Marine Systems" 896 "Nexfour Solutions" 905 "ASA Electronics" 909 "Marines Co (South Korea)" 911 "Nautic-on" 917 "Sentinel" 929 "JL Marine Systems" 930 "Ecotronix" 944 "Zontisa Marine" 951 "EXOR International" 962 "Timbolier Industries" 963 "TJC Micro" 968 "Cox Powertrain" 969 "Blue Seas" 981 "Kobelt Manufacturing" 992 "Blue Ocean IOT" 997 "Xenta Systems" 999 "Signal K" 1004 "Ultraflex" 1008 "Lintest SmartBoat" 1011 "Soundmax" 1020 "Team Italia Marine (Onyx Marine Automation s.r.l)" 1021 "Entratech" 1022 "ITC" 1029 "The Marine Guardian" 1047 "Sonic" 1051 "ProNav" 1053 "Vetus Maxwell INC." 1056 "Lithium Pros" 1059 "Boatrax" 1062 "Marol Co ltd" 1065 "CALYPSO Instruments" 1066 "Spot Zero Water" 1069 "Lithionics Battery" 1070 "Quick-teck Electronics" 1075 "Uniden America" 1083 "Nauticoncept" 1084 "Shadow-Caster LED lighting" 1085 "Wet Sounds" 1088 "E-T-A Circuit Breakers" 1092 "Scheiber" 1100 "Smart Yachts International Limited" 1109 "Dockmate" 1114 "Bobs Machine" 1118 "L3Harris ASV" 1119 "Balmar" 1120 "Elettromedia" 1127 "Electromaax" 1140 "Across Oceans Systems" 1145 "Kiwi Yachting" 1150 "BSB Artificial Intelligence" 1151 "Orca Technologies" 1154 "TBS Electronics" 1158 "Technoton Electroics" 1160 "MG Energy Systems" 1169 "Sea Machine Robotics" 1171 "Vista Manufacturing" 1183 "Zipwake" 1186 "Sailmon" 1192 "Airmoniq Pro Kft" 1194 "Sierra Marine" 1200 "Xinuo Information Technology (Xiamen)" 1218 "Septentrio" 1233 "NKE Marine Electronics" 1238 "SuperTrack Aps" 1239 "Honda Electronics" 1245 "Raritan Engineering" 1249 "Integrated Power Solutions AG" 1260 "Interactive Technologies" 1283 "LTG-Tech" 1299 "Energy Solutions (UK)" 1300 "WATT Fuel Cell" 1302 "Pro Mainer" 1305 "Dragonfly Energy" 1306 "Koden Electronics" 1311 "Humphree" 1316 "Hinkley Yachts" 1317 "Global Marine Management GmbH (GMM)" 1320 "Triskel Marine" 1330 "Warwick Control Technologies" 1331 "Dolphin Charger" 1337 "Barnacle Systems" 1348 "Radian IoT" 1353 "Ocean LED Marine" 1359 "BluNav" 1361 "OVA (Nantong Saiyang Electronics Co., Ltd)" 1368 "RAD Propulsion" 1369 "Electric Yacht" 1372 "Elco Motor Yachts" 1384 "Tecnoseal Foundry S.r.l" 1385 "Pro Charging Systems" 1389 "EVEX" 1398 "Gobius Sensor Technology" 1403 "Arco Marine" 1408 "Lenco Marine" 1413 "Naocontrol" 1417 "Revatek" 1438 "Aeolionics" 1439 "PredictWind" 1440 "Egis Mobile Electric" 1445 "Starboard Yacht Group" 1446 "Roswell Marine" 1451 "ePropulsion (Guangdong ePropulsion Technology Ltd.)" 1452 "Micro-Air" 1453 "Vital Battery" 1458 "Ride Controller" 1460 "Tocaro Blue" 1461 "Vanquish Yachts" 1471 "FT Technologies" 1478 "Alps Alpine" 1481 "E-Force Marine" 1482 "CMC Marine" 1483 "Nanjing Sandemarine Information Technology" 1850 "Teleflex Marine (SeaStar Solutions)" 1851 "Raymarine" 1852 "Navionics" 1853 "Japan Radio" 1854 "Northstar Technologies" 1855 "Furuno" 1856 "Trimble" 1857 "Simrad" 1858 "Litton" 1859 "Kvasar" 1860 "MMP" 1861 "Vector Cantech" 1862 "Yamaha Marine" 1863 "Faria Instruments" ;
VAL_ 2583675648 Industry_Code 0 "Global" 1 "Highway" 2 "Agriculture" 3 "Construction" 4 "Marine Industry" 5 "Industrial" ;
VAL_ 2583675904 Manufacturer_Code 69 "ARKS Enterprises" 78 "FW Murphy/Enovation Controls" 80 "Twin Disc" 85 "Kohler Power Systems" 88 "Hemisphere GPS" 135 "Airmar" 137 "Maretron" 140 "Lowrance" 144 "Mercury Marine" 147 "Nautibus Electronic" 148 "Blue Water Data" 154 "Westerbeke" 157 "ISSPRO" 161 "Offshore Systems (UK)" 163 "Evinrude/BRP" 165 "CPAC Systems" 168 "Xantrex Technology" 169 "Marlin Technologies" 172 "Yanmar Marine" 174 "Volvo Penta" 176 "Carling Technologies Inc. (Moritz Aerospace)" 185 "Beede Instruments" 192 "Floscan Instrument" 193 "Nobeltec" 198 "Mystic Valley Communications" 199 "Actia" 201 "Disenos Y Technologia" 211 "Digital Switching Systems" 215 "Xintex/Atena" 224 "EMMI NETWORK" 228 "ZF" 229 "Garmin" 233 "Yacht Monitoring Solutions" 235 "Sailormade Marine Telemetry/Tetra Technology" 243 "Eride" 257 "Honda Motor" 272 "Groco" 273 "Actisense" 274 "Amphenol LTW Technology" 275 "Navico" 283 "Hamilton Jet" 285 "Sea Recovery" 286 "Coelmo SRL Italy" 295 "BEP Marine" 304 "Empir Bus" 305 "NovAtel" 306 "Sleipner Motor" 307 "MBW Technologies" 315 "ICOM" 328 "Qwerty" 329 "Dief" 341 "Boening Automationstechnologie" 345 "Korean Maritime University" 351 "Thrane and Thrane" 355 "Mastervolt" 356 "Fischer Panda Generators" 358 "Victron Energy" 370 "Rolls Royce Marine" 373 "Electronic Design" 374 "Northern Lights" 378 "Glendinning" 381 "B & G" 384 "Rose Point Navigation Systems" 385 "Johnson Outdoors Marine Electronics Inc Geonav" 394 "Capi 2" 396 "Beyond Measure" 400 "Livorsi Marine" 404 "ComNav" 409 "Chetco" 419 "Fusion Electronics" 421 "Standard Horizon" 422 "True Heading" 426 "Egersund Marine Electronics" 427 "em-trak Marine Electronics" 431 "Tohatsu Co, JP" 437 "Digital Yacht" 438 "Comar Systems Limited" 440 "Cummins" 443 "VDO (aka Continental-Corporation)" 451 "Parker Hannifin aka Village Marine Tech" 459 "Alltek Marine Electronics" 460 "SAN GIORGIO S.E.I.N" 466 "Veethree Electronics & Marine" 470 "SI-TEX Marine Electronics" 471 "Sea Cross Marine" 475 "GME aka Standard Communications" 476 "Humminbird Marine Electronics" 478 "Ocean Sat" 481 "Chetco Digital Instruments" 493 "Watcheye" 499 "Lcj Capteurs" 502 "Attwood Marine" 503 "Naviop S.R.L." 504 "Vesper Marine" 510 "Marinesoft" 513 "Simarine" 517 "NoLand Engineering" 518 "Transas USA" 529 "National Instruments Korea" 530 "National Marine Electronics Association" 532 "Onwa Marine" 540 "Webasto" 571 "Marinecraft (South Korea)" 573 "McMurdo Group aka Orolia" 578 "Advansea" 579 "KVH" 580 "San Jose Technology" 583 "Yacht Control" 586 "Suzuki Motor" 591 "US Coast Guard" 595 "Ship Module aka Customware" 600 "Aquatic AV" 605 "Aventics" 606 "Intellian" 612 "SamwonIT" 614 "Arlt Tecnologies" 637 "Bavaria Yachts" 641 "Diverse Yacht Services" 644 "Wema U.S.A dba KUS" 658 "Shenzhen Jiuzhou Himunication" 688 "Rockford" 699 "Harman International" 704 "JL Audio" 708 "Lars Thrane" 715 "Autonnic" 717 "Yacht Devices" 734 "REAP Systems" 735 "AEM Performance Electronics" 739 "LxNav" 741 "Littelfuse, Inc (formerly Carling Technologies)" 743 "DaeMyung" 744 "Woosung" 748 "ISOTTA IFRA srl" 773 "Clarion US" 776 "HMI Systems" 777 "Ocean Signal" 778 "Seakeeper" 781 "Poly Planar" 785 "Fischer Panda DE" 795 "Broyda Industries" 796 "Canadian Automotive" 797 "Tides Marine" 798 "Lumishore" 799 "Still Water Designs and Audio" 802 "BJ Technologies (Beneteau)" 803 "Gill Sensors" 811 "Blue Water Desalination" 815 "FLIR" 824 "Undheim Systems" 826 "Lewmar" 838 "TeamSurv" 844 "Fell Marine" 847 "Oceanvolt" 862 "Prospec" 868 "Data Panel" 890 "L3 Technologies" 894 "Rhodan Marine Systems" 896 "Nexfour Solutions" 905 "ASA Electronics" 909 "Marines Co (South Korea)" 911 "Nautic-on" 917 "Sentinel" 929 "JL Marine Systems" 930 "Ecotronix" 944 "Zontisa Marine" 951 "EXOR International" 962 "Timbolier Industries" 963 "TJC Micro" 968 "Cox Powertrain" 969 "Blue Seas" 981 "Kobelt Manufacturing" 992 "Blue Ocean IOT" 997 "Xenta Systems" 999 "Signal K" 1004 "Ultraflex" 1008 "Lintest SmartBoat" 1011 "Soundmax" 1020 "Team Italia Marine (Onyx Marine Automation s.r.l)" 1021 "Entratech" 1022 "ITC" 1029 "The Marine Guardian" 1047 "Sonic" 1051 "ProNav" 1053 "Vetus Maxwell INC." 1056 "Lithium Pros" 1059 "Boatrax" 1062 "Marol Co ltd" 1065 "CALYPSO Instruments" 1066 "Spot Zero Water" 1069 "Lithionics Battery" 1070 "Quick-teck Electronics" 1075 "Uniden America" 1083 "Nauticoncept" 1084 "Shadow-Caster LED lighting" 1085 "Wet Sounds" 1088 "E-T-A Circuit Breakers" 1092 "Scheiber" 1100 "Smart Yachts International Limited" 1109 "Dockmate" 1114 "Bobs Machine" 1118 "L3Harris ASV" 1119 "Balmar" 1120 "Elettromedia" 1127 "Electromaax" 1140 "Across Oceans Systems" 1145 "Kiwi Yachting" 1150 "BSB Artificial Intelligence" 1151 "Orca Technologies" 1154 "TBS Electronics" 1158 "Technoton Electroics" 1160 "MG Energy Systems" 1169 "Sea Machine Robotics" 1171 "Vista Manufacturing" 1183 "Zipwake" 1186 "Sailmon" 1192 "Airmoniq Pro Kft" 1194 "Sierra Marine" 1200 "Xinuo Information Technology (Xiamen)" 1218 "Septentrio" 1233 "NKE Marine Electronics" 1238 "SuperTrack Aps" 1239 "Honda Electronics" 1245 "Raritan Engineering" 1249 "Integrated Power Solutions AG" 1260 "Interactive Technologies" 1283 "LTG-Tech" 1299 "Energy Solutions (UK)" 1300 "WATT Fuel Cell" 1302 "Pro Mainer" 1305 "Dragonfly Energy" 1306 "Koden Electronics" 1311 "Humphree" 1316 "Hinkley Yachts" 1317 "Global Marine Management GmbH (GMM)" 1320 "Triskel Marine" 1330 "Warwick Control Technologies" 1331 "Dolphin Charger" 1337 "Barnacle Systems" 1348 "Radian IoT" 1353 "Ocean LED Marine" 1359 "BluNav" 1361 "OVA (Nantong Saiyang Electronics Co., Ltd)" 1368 "RAD Propulsion" 1369 "Electric Yacht" 1372 "Elco Motor Yachts" 1384 "Tecnoseal Foundry S.r.l" 1385 "Pro Charging Systems" 1389 "EVEX" 1398 "Gobius Sensor Technology" 1403 "Arco Marine" 1408 "Lenco Marine" 1413 "Naocontrol" 1417 "Revatek" 1438 "Aeolionics" 1439 "PredictWind" 1440 "Egis Mobile Electric" 1445 "Starboard Yacht Group" 1446 "Roswell Marine" 1451 "ePropulsion (Guangdong ePropulsion Technology Ltd.)" 1452 "Micro-Air" 1453 "Vital Battery" 1458 "Ride Controller" 1460 "Tocaro Blue" 1461 "Vanquish Yachts" 1471 "FT Technologies" 1478 "Alps Alpine" 1481 "E-Force Marine" 1482 "CMC Marine" 1483 "Nanjing Sandemarine Information Technology" 1850 "Teleflex Marine (SeaStar Solutions)" 1851 "Raymarine" 1852 "Navionics" 1853 "Japan Radio" 1854 "Northstar Technologies" 1855 "Furuno" 1856 "Trimble" 1857 "Simrad" 1858 "Litton" 1859 "Kvasar" 1860 "MMP" 1861 "Vector Cantech" 1862 "Yamaha Marine" 1863 "Faria Instruments" ;
VAL_ 2583675904 Industry_Code 0 "Global" 1 "Highway" 2 "Agriculture" 3 "Construction" 4 "Marine Industry" 5 "Industrial" ;
CM_ SG_ 2583635968 Text "STRING field: decode bytes as ASCII (0x00/@/0xFF = terminator); canboat type: STRING_FIX";
CM_ SG_ 2650760704 Current_Waypoint_Name "STRING field: decode bytes as ASCII (0x00/@/0xFF = terminator); canboat type: STRING_FIX";
CM_ SG_ 2650760704 Next_Waypoint_Name "STRING field: decode bytes as ASCII (0x00/@/0xFF = terminator); canboat type: STRING_FIX";
CM_ SG_ 2550267904 Source "STRING field: decode bytes as ASCII (0x00/@/0xFF = terminator); canboat type: STRING_FIX";
CM_ SG_ 2550267904 Device "STRING field: decode bytes as ASCII (0x00/@/0xFF = terminator); canboat type: STRING_FIX";
CM_ SG_ 2550267904 Sentence "STRING field: decode bytes as ASCII (0x00/@/0xFF = terminator); canboat type: STRING_FIX";

BA_DEF_ BO_ "GenMsgCycleTime" INT 0 60000;
BA_DEF_ BO_ "ProtocolType" STRING;

BA_DEF_ BO_ "J1939PGN" INT 0 262143;
BA_ "J1939PGN" BO_ 2583635968 130856;
BA_ "J1939PGN" BO_ 2650745856 130860;
BA_ "GenMsgCycleTime" BO_ 2650745856 1000;
BA_ "J1939PGN" BO_ 2583642112 130880;
BA_ "J1939PGN" BO_ 2583642368 130881;
BA_ "J1939PGN" BO_ 2583647232 130900;
BA_ "J1939PGN" BO_ 2583649792 130910;
BA_ "J1939PGN" BO_ 2583650048 130911;
BA_ "J1939PGN" BO_ 2583650304 130912;
BA_ "J1939PGN" BO_ 2583650560 130913;
BA_ "J1939PGN" BO_ 2650760704 130918;
BA_ "GenMsgCycleTime" BO_ 2650760704 1000;
BA_ "J1939PGN" BO_ 2583652608 130921;
BA_ "J1939PGN" BO_ 2583657216 130939;
BA_ "J1939PGN" BO_ 2650767360 130944;
BA_ "J1939PGN" BO_ 2583658752 130945;
BA_ "J1939PGN" BO_ 2583659008 130946;
BA_ "J1939PGN" BO_ 2583659264 130947;
BA_ "J1939PGN" BO_ 2583660288 130951;
BA_ "J1939PGN" BO_ 2583674880 131008;
BA_ "J1939PGN" BO_ 2583675648 131011;
BA_ "J1939PGN" BO_ 2583675904 131012;
BA_ "J1939PGN" BO_ 2550136832 262161;
BA_ "J1939PGN" BO_ 2550136832 262384;
BA_ "J1939PGN" BO_ 2550136832 262386;
BA_ "J1939PGN" BO_ 2550136832 262388;
BA_ "J1939PGN" BO_ 2550202368 262400;
BA_ "J1939PGN" BO_ 2550267904 262656;
BA_ "J1939PGN" BO_ 2550267904 262657;
BA_ "J1939PGN" BO_ 2550267904 262658;
